VERSION ""

NS_ :

BS_:

BU_: ILC4 ILC3 ILC2 ILC1 C1 C0 ACU ECAS2 CCU TPMS ACC AEBS Door4 Door3 Door2 Door1 WWCU HVAC HVAC_HMI EPHS LDWS SCSM EVCC ECAS1 BMS SWS EBS VCU2 PCi_ECM DCU EPH VFC VCU1 Tachograph EPIC

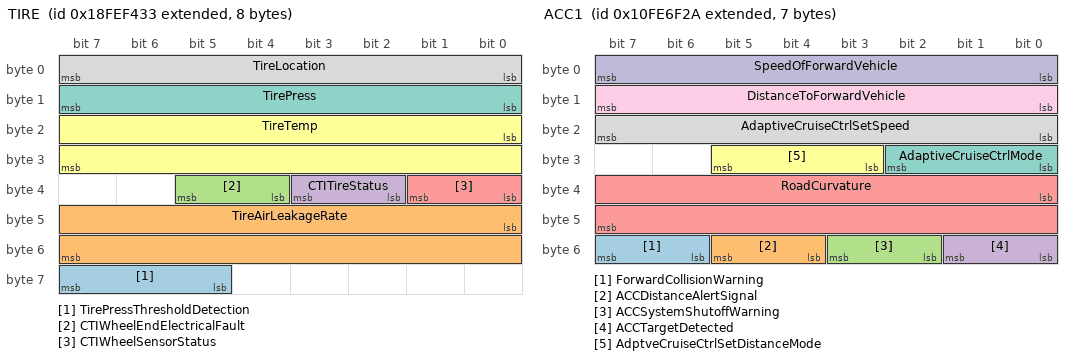
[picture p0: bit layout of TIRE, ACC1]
BO_ 2566845491 TIRE: 8 TPMS
 SG_ TirePressThresholdDetection : 61|3@1+ (1,0) [0|7] "" Vector__XXX
 SG_ TireAirLeakageRate : 40|16@1+ (0.1,0) [0|6425.5] "Pa/s" Vector__XXX
 SG_ CTIWheelEndElectricalFault : 36|2@1+ (1,0) [0|3] "" Vector__XXX
 SG_ CTITireStatus : 34|2@1+ (1,0) [0|3] "" Vector__XXX
 SG_ CTIWheelSensorStatus : 32|2@1+ (1,0) [0|3] "" Vector__XXX
 SG_ TireTemp : 16|16@1+ (0.03125,-273) [-273|1735] "deg" Vector__XXX
 SG_ TirePress : 8|8@1+ (8,0) [0|2040] "kPa" Vector__XXX
 SG_ TireLocation : 0|8@1+ (1,0) [0|255] "" Vector__XXX

BO_ 2432593706 ACC1: 7 ACC
 SG_ ForwardCollisionWarning : 54|2@1+ (1,0) [0|0] "" Vector__XXX
 SG_ ACCDistanceAlertSignal : 52|2@1+ (1,0) [0|3] "" Vector__XXX
 SG_ ACCSystemShutoffWarning : 50|2@1+ (1,0) [0|3] "" Vector__XXX
 SG_ ACCTargetDetected : 48|2@1+ (1,0) [0|3] "" Vector__XXX
 SG_ RoadCurvature : 32|16@1+ (0.0078125,-250) [-250|251.992] "1/km" Vector__XXX
 SG_ AdptveCruiseCtrlSetDistanceMode : 27|3@1+ (1,0) [0|7] "" Vector__XXX
 SG_ AdaptiveCruiseCtrlMode : 24|3@1+ (1,0) [0|7] "" Vector__XXX
 SG_ AdaptiveCruiseCtrlSetSpeed : 16|8@1+ (1,0) [0|250] "km/h" Vector__XXX
 SG_ DistanceToForwardVehicle : 8|8@1+ (1,0) [0|250] "m" Vector__XXX
 SG_ SpeedOfForwardVehicle : 0|8@1+ (1,0) [0|250] "km/h" Vector__XXX

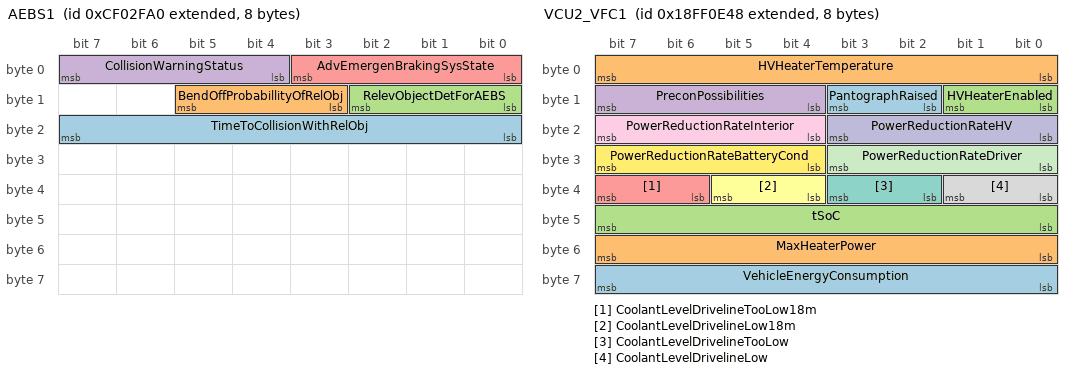
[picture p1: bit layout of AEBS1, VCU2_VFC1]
BO_ 2364551072 AEBS1: 8 AEBS
 SG_ TimeToCollisionWithRelObj : 16|8@1+ (0.05,0) [0|13] "sec" Vector__XXX
 SG_ BendOffProbabillityOfRelObj : 11|3@1+ (1,0) [0|0] "" Vector__XXX
 SG_ RelevObjectDetForAEBS : 8|3@1+ (1,0) [0|0] "" Vector__XXX
 SG_ CollisionWarningStatus : 4|4@1+ (1,0) [0|0] "" Vector__XXX
 SG_ AdvEmergenBrakingSysState : 0|4@1+ (1,0) [0|0] "" Vector__XXX

BO_ 2566852168 VCU2_VFC1: 8 VCU2
 SG_ VehicleEnergyConsumption : 56|8@1+ (1,0) [0|0] "kWh/100km" Vector__XXX
 SG_ MaxHeaterPower : 48|8@1+ (500,0) [0|125000] "Watt" Vector__XXX
 SG_ tSoC : 40|8@1+ (0.4,0) [0|100] "%" Vector__XXX
 SG_ PreconPossibilities : 12|4@1+ (1,0) [0|0] "" Vector__XXX
 SG_ CoolantLevelDrivelineTooLow18m : 38|2@1+ (1,0) [0|3] "" Vector__XXX
 SG_ CoolantLevelDrivelineLow18m : 36|2@1+ (1,0) [0|3] "" Vector__XXX
 SG_ CoolantLevelDrivelineTooLow : 34|2@1+ (1,0) [0|3] "" Vector__XXX
 SG_ CoolantLevelDrivelineLow : 32|2@1+ (1,0) [0|3] "" Vector__XXX
 SG_ PowerReductionRateInterior : 20|4@1+ (10,0) [0|100] "%" Vector__XXX
 SG_ PowerReductionRateHV : 16|4@1+ (10,0) [0|100] "%" Vector__XXX
 SG_ PowerReductionRateDriver : 24|4@1+ (10,0) [0|100] "%" Vector__XXX
 SG_ PowerReductionRateBatteryCond : 28|4@1+ (10,0) [0|100] "%" Vector__XXX
 SG_ PantographRaised : 10|2@1+ (1,0) [0|0] "" Vector__XXX
 SG_ HVHeaterTemperature : 0|8@1+ (1,-50) [-50|205] "C" Vector__XXX
 SG_ HVHeaterEnabled : 8|2@1+ (1,0) [0|0] "" Vector__XXX

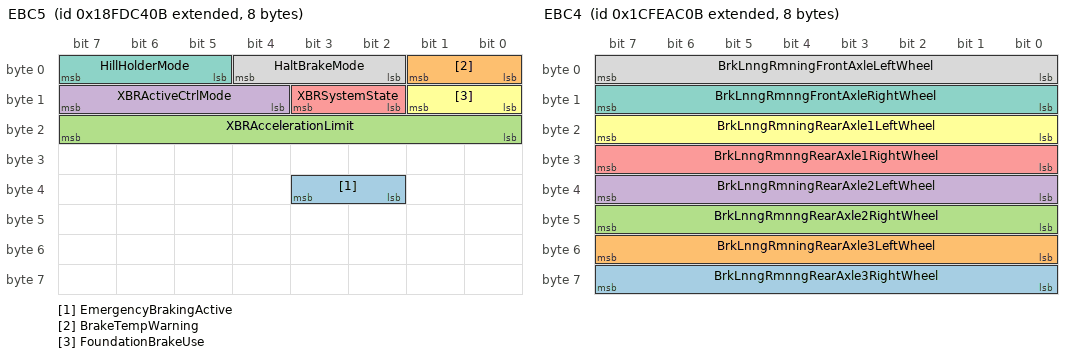
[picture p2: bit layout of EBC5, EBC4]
BO_ 2566767627 EBC5: 8 EBS
 SG_ EmergencyBrakingActive : 34|2@1+ (1,0) [0|0] "" Vector__XXX
 SG_ BrakeTempWarning : 0|2@1+ (1,0) [0|3] "" Vector__XXX
 SG_ XBRAccelerationLimit : 16|8@1+ (0.1,-12.5) [-12.5|12.5] "m/s²" Vector__XXX
 SG_ XBRActiveCtrlMode : 12|4@1+ (1,0) [0|15] "" Vector__XXX
 SG_ XBRSystemState : 10|2@1+ (1,0) [0|3] "" Vector__XXX
 SG_ FoundationBrakeUse : 8|2@1+ (1,0) [0|3] "" Vector__XXX
 SG_ HillHolderMode : 5|3@1+ (1,0) [0|7] "" Vector__XXX
 SG_ HaltBrakeMode : 2|3@1+ (1,0) [0|7] "" Vector__XXX

BO_ 2565865739 EBC1_EBS: 8 EBS
 SG_ SrcAddrssOfCtrllngDvcFrBrkCntrl : 48|8@1+ (1,0) [0|255] "" Vector__XXX
 SG_ BrakePedalPos : 8|8@1+ (0.4,0) [0|100] "%" Vector__XXX
 SG_ TrctrMntdTrilerABSWarningSignal : 62|2@1+ (1,0) [0|3] "" Vector__XXX
 SG_ TrailerABSStatus : 60|2@1+ (1,0) [0|3] "" Vector__XXX
 SG_ HaltBrakeSwitch : 58|2@1+ (1,0) [0|3] "" Vector__XXX
 SG_ ATC_ASRInformationSignal : 46|2@1+ (1,0) [0|3] "" Vector__XXX
 SG_ ABS_EBSAmberWarningSignal : 44|2@1+ (1,0) [0|3] "" Vector__XXX
 SG_ EBSRedWarningSignal : 42|2@1+ (1,0) [0|3] "" Vector__XXX
 SG_ ABSFullyOperational : 40|2@1+ (1,0) [0|3] "" Vector__XXX
 SG_ EngRetarderSelection : 32|8@1+ (0.4,0) [0|100] "%" Vector__XXX
 SG_ RemoteAccelEnableSwitch : 30|2@1+ (1,0) [0|3] "" Vector__XXX
 SG_ EngAuxEngShutdownSwitch : 28|2@1+ (1,0) [0|3] "" Vector__XXX
 SG_ EngDerateSwitch : 26|2@1+ (1,0) [0|3] "" Vector__XXX
 SG_ AccelInterlockSwitch : 24|2@1+ (1,0) [0|3] "" Vector__XXX
 SG_ TractionCtrlOverrideSwitch : 22|2@1+ (1,0) [0|3] "" Vector__XXX
 SG_ ASRHillHolderSwitch : 20|2@1+ (1,0) [0|3] "" Vector__XXX
 SG_ ASROffroadSwitch : 18|2@1+ (1,0) [0|3] "" Vector__XXX
 SG_ ABSOffroadSwitch : 16|2@1+ (1,0) [0|3] "" Vector__XXX
 SG_ EBSBrakeSwitch : 6|2@1+ (1,0) [0|3] "" Vector__XXX
 SG_ AntiLockBrakingActive : 4|2@1+ (1,0) [0|3] "" Vector__XXX
 SG_ ASRBrakeCtrlActive : 2|2@1+ (1,0) [0|3] "" Vector__XXX
 SG_ ASREngCtrlActive : 0|2@1+ (1,0) [0|3] "" Vector__XXX

BO_ 2633935883 EBC4: 8 EBS
 SG_ BrkLnngRmnngRearAxle3RightWheel : 56|8@1+ (0.4,0) [0|100] "%" Vector__XXX
 SG_ BrkLnngRmningRearAxle3LeftWheel : 48|8@1+ (0.4,0) [0|100] "%" Vector__XXX
 SG_ BrkLnngRmnngRearAxle2RightWheel : 40|8@1+ (0.4,0) [0|100] "%" Vector__XXX
 SG_ BrkLnngRmningRearAxle2LeftWheel : 32|8@1+ (0.4,0) [0|100] "%" Vector__XXX
 SG_ BrkLnngRmnngRearAxle1RightWheel : 24|8@1+ (0.4,0) [0|100] "%" Vector__XXX
 SG_ BrkLnngRmningRearAxle1LeftWheel : 16|8@1+ (0.4,0) [0|100] "%" Vector__XXX
 SG_ BrkLnngRmnngFrontAxleRightWheel : 8|8@1+ (0.4,0) [0|100] "%" Vector__XXX
 SG_ BrkLnngRmningFrontAxleLeftWheel : 0|8@1+ (0.4,0) [0|100] "%" Vector__XXX

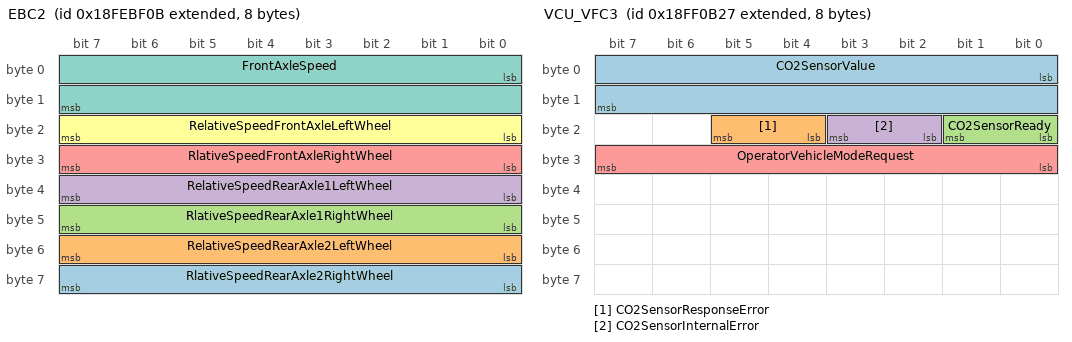
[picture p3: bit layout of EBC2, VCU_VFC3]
BO_ 2566831883 EBC2: 8 EBS
 SG_ RlativeSpeedRearAxle2RightWheel : 56|8@1+ (0.0625,-7.8125) [-7.8125|7.8125] "km/h" Vector__XXX
 SG_ RelativeSpeedRearAxle2LeftWheel : 48|8@1+ (0.0625,-7.8125) [-7.8125|7.8125] "km/h" Vector__XXX
 SG_ RlativeSpeedRearAxle1RightWheel : 40|8@1+ (0.0625,-7.8125) [-7.8125|7.8125] "km/h" Vector__XXX
 SG_ RelativeSpeedRearAxle1LeftWheel : 32|8@1+ (0.0625,-7.8125) [-7.8125|7.8125] "km/h" Vector__XXX
 SG_ RlativeSpeedFrontAxleRightWheel : 24|8@1+ (0.0625,-7.8125) [-7.8125|7.8125] "km/h" Vector__XXX
 SG_ RelativeSpeedFrontAxleLeftWheel : 16|8@1+ (0.0625,-7.8125) [-7.8125|7.8125] "km/h" Vector__XXX
 SG_ FrontAxleSpeed : 0|16@1+ (0.00390625,0) [0|250.996] "km/h" Vector__XXX

BO_ 2365479471 ASC1_ECAS1: 8 ECAS1
 SG_ SspensionCtrlRefusalInformation : 56|4@1+ (1,0) [0|15] "" Vector__XXX
 SG_ SuspensionRemoteCtrl2 : 50|2@1+ (1,0) [0|3] "" Vector__XXX
 SG_ SuspensionRemoteCtrl1 : 48|2@1+ (1,0) [0|3] "" Vector__XXX
 SG_ RearAxleInBumperRange : 42|2@1+ (1,0) [0|3] "" Vector__XXX
 SG_ FrontAxleInBumperRange : 40|2@1+ (1,0) [0|3] "" Vector__XXX
 SG_ DoorRelease : 36|2@1+ (1,0) [0|3] "" Vector__XXX
 SG_ VehicleMotionInhibit : 34|2@1+ (1,0) [0|3] "" Vector__XXX
 SG_ SecurityDevice : 32|2@1+ (1,0) [0|3] "" Vector__XXX
 SG_ LevelCtrlMode : 28|4@1+ (1,0) [0|15] "" Vector__XXX
 SG_ KneelingInformation : 24|4@1+ (1,0) [0|15] "" Vector__XXX
 SG_ LiftingCtrlModeRearAxle : 22|2@1+ (1,0) [0|3] "" Vector__XXX
 SG_ LiftingCtrlModeFrontAxle : 20|2@1+ (1,0) [0|3] "" Vector__XXX
 SG_ LoweringCtrlModeRearAxle : 18|2@1+ (1,0) [0|3] "" Vector__XXX
 SG_ LoweringCtrlModeFrontAxle : 16|2@1+ (1,0) [0|3] "" Vector__XXX
 SG_ AboveNominalLevelRearAxle : 14|2@1+ (1,0) [0|3] "" Vector__XXX
 SG_ AboveNominalLevelFrontAxle : 12|2@1+ (1,0) [0|3] "" Vector__XXX
 SG_ BelowNominalLevelRearAxle : 10|2@1+ (1,0) [0|3] "" Vector__XXX
 SG_ BelowNominalLevelFrontAxle : 8|2@1+ (1,0) [0|3] "" Vector__XXX
 SG_ NominalLevelRearAxle : 4|4@1+ (1,0) [0|15] "" Vector__XXX
 SG_ NominalLevelFrontAxle : 0|4@1+ (1,0) [0|15] "" Vector__XXX
 SG_ LiftAxle2Pos : 46|2@1+ (1,0) [0|3] "" Vector__XXX
 SG_ LiftAxle1Pos : 38|2@1+ (1,0) [0|3] "" Vector__XXX

BO_ 2365525031 VCU_VFC2: 8 VCU1
 SG_ EmergencyBrakeLight : 2|2@1+ (1,0) [0|0] "" Vector__XXX
 SG_ BrakeLightRequest : 0|2@1+ (1,0) [0|0] "" Vector__XXX

BO_ 2565866801 ETC2_VFC: 8 VFC
 SG_ TransCurrentGear : 24|8@1+ (1,-125) [-125|125] "" Vector__XXX

BO_ 2565812692 DCU_Veh_4: 8 Door4
 SG_ DeadboltInput : 62|2@1- (1,0) [0|0] ""  VFC
 SG_ Door_Block_Input_State : 60|2@1+ (1,0) [0|3] ""  VFC
 SG_ Light_Barrier_Input_State : 58|2@1+ (1,0) [0|3] ""  VFC
 SG_ External_Close_Button : 56|2@1+ (1,0) [0|3] ""  VFC
 SG_ External_Open_Button : 54|2@1+ (1,0) [0|3] ""  VFC
 SG_ Workshop_Button : 52|2@1+ (1,0) [0|3] ""  VFC
 SG_ Inner_Sensitive_Edge_Input_State : 50|2@1+ (1,0) [0|3] ""  VFC
 SG_ Spare_In_5 : 48|2@1+ (1,0) [0|3] ""  VFC
 SG_ Spare_In_4 : 46|2@1+ (1,0) [0|3] ""  VFC
 SG_ Spare_In_3 : 44|2@1+ (1,0) [0|3] ""  VFC
 SG_ Spare_In_2 : 42|2@1+ (1,0) [0|3] ""  VFC
 SG_ Spare_In_1 : 40|2@1+ (1,0) [0|3] ""  VFC
 SG_ Door_Mode_Right : 36|4@1+ (1,0) [0|15] ""  VFC
 SG_ Door_Mode_Left : 32|4@1+ (1,0) [0|15] ""  VFC
 SG_ Right_Leaf_Obstruction_State : 28|4@1+ (1,0) [0|15] ""  VFC
 SG_ Left_Leaf_Obstruction_State : 24|4@1+ (1,0) [0|15] ""  VFC
 SG_ Door_Position_Right : 16|8@1+ (0.4,0) [0|102] ""  VFC
 SG_ Door_Position_Left : 8|8@1+ (0.4,0) [0|102] ""  VFC
 SG_ Leaf_State_Right : 4|4@1+ (1,0) [0|15] ""  VFC
 SG_ Leaf_State_Left : 0|4@1+ (1,0) [0|15] ""  VFC

BO_ 2565812691 DCU_Veh_3: 8 Door3
 SG_ DeadboltInput : 62|2@1- (1,0) [0|0] ""  VFC
 SG_ Door_Block_Input_State : 60|2@1+ (1,0) [0|3] ""  VFC
 SG_ Light_Barrier_Input_State : 58|2@1+ (1,0) [0|3] ""  VFC
 SG_ External_Close_Button : 56|2@1+ (1,0) [0|3] ""  VFC
 SG_ External_Open_Button : 54|2@1+ (1,0) [0|3] ""  VFC
 SG_ Workshop_Button : 52|2@1+ (1,0) [0|3] ""  VFC
 SG_ Inner_Sensitive_Edge_Input_State : 50|2@1+ (1,0) [0|3] ""  VFC
 SG_ Spare_In_5 : 48|2@1+ (1,0) [0|3] ""  VFC
 SG_ Spare_In_4 : 46|2@1+ (1,0) [0|3] ""  VFC
 SG_ Spare_In_3 : 44|2@1+ (1,0) [0|3] ""  VFC
 SG_ Spare_In_2 : 42|2@1+ (1,0) [0|3] ""  VFC
 SG_ Spare_In_1 : 40|2@1+ (1,0) [0|3] ""  VFC
 SG_ Door_Mode_Right : 36|4@1+ (1,0) [0|15] ""  VFC
 SG_ Door_Mode_Left : 32|4@1+ (1,0) [0|15] ""  VFC
 SG_ Right_Leaf_Obstruction_State : 28|4@1+ (1,0) [0|15] ""  VFC
 SG_ Left_Leaf_Obstruction_State : 24|4@1+ (1,0) [0|15] ""  VFC
 SG_ Door_Position_Right : 16|8@1+ (0.4,0) [0|102] ""  VFC
 SG_ Door_Position_Left : 8|8@1+ (0.4,0) [0|102] ""  VFC
 SG_ Leaf_State_Right : 4|4@1+ (1,0) [0|15] ""  VFC
 SG_ Leaf_State_Left : 0|4@1+ (1,0) [0|15] ""  VFC

BO_ 2565812690 DCU_Veh_2: 8 Door2
 SG_ DeadboltInput : 62|2@1- (1,0) [0|0] ""  VFC
 SG_ Door_Block_Input_State : 60|2@1+ (1,0) [0|3] ""  VFC
 SG_ Light_Barrier_Input_State : 58|2@1+ (1,0) [0|3] ""  VFC
 SG_ External_Close_Button : 56|2@1+ (1,0) [0|3] ""  VFC
 SG_ External_Open_Button : 54|2@1+ (1,0) [0|3] ""  VFC
 SG_ Workshop_Button : 52|2@1+ (1,0) [0|3] ""  VFC
 SG_ Inner_Sensitive_Edge_Input_State : 50|2@1+ (1,0) [0|3] ""  VFC
 SG_ Spare_In_5 : 48|2@1+ (1,0) [0|3] ""  VFC
 SG_ Spare_In_4 : 46|2@1+ (1,0) [0|3] ""  VFC
 SG_ Spare_In_3 : 44|2@1+ (1,0) [0|3] ""  VFC
 SG_ Spare_In_2 : 42|2@1+ (1,0) [0|3] ""  VFC
 SG_ Spare_In_1 : 40|2@1+ (1,0) [0|3] ""  VFC
 SG_ Door_Mode_Right : 36|4@1+ (1,0) [0|15] ""  VFC
 SG_ Door_Mode_Left : 32|4@1+ (1,0) [0|15] ""  VFC
 SG_ Right_Leaf_Obstruction_State : 28|4@1+ (1,0) [0|15] ""  VFC
 SG_ Left_Leaf_Obstruction_State : 24|4@1+ (1,0) [0|15] ""  VFC
 SG_ Door_Position_Right : 16|8@1+ (0.4,0) [0|102] ""  VFC
 SG_ Door_Position_Left : 8|8@1+ (0.4,0) [0|102] ""  VFC
 SG_ Leaf_State_Right : 4|4@1+ (1,0) [0|15] ""  VFC
 SG_ Leaf_State_Left : 0|4@1+ (1,0) [0|15] ""  VFC

BO_ 2565812689 DCU_Veh_1: 8 Door1
 SG_ DeadboltInput : 62|2@1- (1,0) [0|0] ""  VFC
 SG_ Door_Block_Input_State : 60|2@1+ (1,0) [0|3] ""  VFC
 SG_ Light_Barrier_Input_State : 58|2@1+ (1,0) [0|3] ""  VFC
 SG_ External_Close_Button : 56|2@1+ (1,0) [0|3] ""  VFC
 SG_ External_Open_Button : 54|2@1+ (1,0) [0|3] ""  VFC
 SG_ Workshop_Button : 52|2@1+ (1,0) [0|3] ""  VFC
 SG_ Inner_Sensitive_Edge_Input_State : 50|2@1+ (1,0) [0|3] ""  VFC
 SG_ Spare_In_5 : 48|2@1+ (1,0) [0|3] ""  VFC
 SG_ Spare_In_4 : 46|2@1+ (1,0) [0|3] ""  VFC
 SG_ Spare_In_3 : 44|2@1+ (1,0) [0|3] ""  VFC
 SG_ Spare_In_2 : 42|2@1+ (1,0) [0|3] ""  VFC
 SG_ Spare_In_1 : 40|2@1+ (1,0) [0|3] ""  VFC
 SG_ Door_Mode_Right : 36|4@1+ (1,0) [0|15] ""  VFC
 SG_ Door_Mode_Left : 32|4@1+ (1,0) [0|15] ""  VFC
 SG_ Right_Leaf_Obstruction_State : 28|4@1+ (1,0) [0|15] ""  VFC
 SG_ Left_Leaf_Obstruction_State : 24|4@1+ (1,0) [0|15] ""  VFC
 SG_ Door_Position_Right : 16|8@1+ (0.4,0) [0|102] ""  VFC
 SG_ Door_Position_Left : 8|8@1+ (0.4,0) [0|102] ""  VFC
 SG_ Leaf_State_Right : 4|4@1+ (1,0) [0|15] ""  VFC
 SG_ Leaf_State_Left : 0|4@1+ (1,0) [0|15] ""  VFC

BO_ 2565854257 Veh_DCU_4: 8 VFC
 SG_ AutoCloseTime : 56|4@1+ (1,0) [0|14] "s"  Door4
 SG_ Inhibit_Opening : 62|2@1- (1,0) [0|0] ""  Door4
 SG_ Inhibit_Closing : 60|2@1- (1,0) [0|0] ""  Door4
 SG_ Ignore_Outer_Sensitive_Edge : 54|2@1+ (1,0) [0|3] ""  Door4
 SG_ Ignore_Light_Barrier : 50|2@1+ (1,0) [0|3] ""  Door4
 SG_ Spare_Out_Request_7 : 44|2@1+ (1,0) [0|3] ""  Door4
 SG_ Spare_Out_Request_5 : 40|2@1+ (1,0) [0|3] ""  Door4
 SG_ Spare_Out_Request_4 : 38|2@1+ (1,0) [0|3] ""  Door4
 SG_ Spare_Out_Request_3 : 36|2@1+ (1,0) [0|3] ""  Door4
 SG_ Spare_Out_Request_2 : 34|2@1+ (1,0) [0|3] ""  Door4
 SG_ Spare_Out_Request_6 : 42|2@1+ (1,0) [0|3] ""  Door4
 SG_ Spare_Out_Request_8 : 46|2@1+ (1,0) [0|3] ""  Door4
 SG_ Ignore_Speed_Obstruction : 52|2@1+ (1,0) [0|3] ""  Door4
 SG_ Ignore_Sensitive_Edge : 48|2@1+ (1,0) [0|3] ""  Door4
 SG_ Spare_Out_Request_1 : 32|2@1+ (1,0) [0|3] ""  Door4
 SG_ Door_Position_Request_Right : 24|8@1+ (0.4,0) [0|102] ""  Door4
 SG_ Door_Position_Request_Left_Both : 16|8@1+ (0.4,0) [0|102] ""  Door4
 SG_ Right_Leaf_Command : 12|4@1+ (1,0) [0|15] ""  Door4
 SG_ Left_Leaf_Command : 8|4@1+ (1,0) [0|15] ""  Door4
 SG_ Buzzer : 6|2@1+ (1,0) [0|3] ""  Door4
 SG_ Step_Lights : 4|2@1+ (1,0) [0|3] ""  Door4
 SG_ Reset_Inhibit_Emergency_Valve : 2|2@1+ (1,0) [0|3] ""  Door4
 SG_ Speed_Standstill_Signal : 0|2@1+ (1,0) [0|3] ""  Door4

BO_ 2565854001 Veh_DCU_3: 8 VFC
 SG_ AutoCloseTime : 56|4@1+ (1,0) [0|14] "s"  Door3
 SG_ Inhibit_Opening : 62|2@1- (1,0) [0|0] ""  Door3
 SG_ Inhibit_Closing : 60|2@1- (1,0) [0|0] ""  Door3
 SG_ Ignore_Outer_Sensitive_Edge : 54|2@1+ (1,0) [0|3] ""  Door3
 SG_ Ignore_Light_Barrier : 50|2@1+ (1,0) [0|3] ""  Door3
 SG_ Spare_Out_Request_7 : 44|2@1+ (1,0) [0|3] ""  Door3
 SG_ Spare_Out_Request_5 : 40|2@1+ (1,0) [0|3] ""  Door3
 SG_ Spare_Out_Request_4 : 38|2@1+ (1,0) [0|3] ""  Door3
 SG_ Spare_Out_Request_3 : 36|2@1+ (1,0) [0|3] ""  Door3
 SG_ Spare_Out_Request_2 : 34|2@1+ (1,0) [0|3] ""  Door3
 SG_ Spare_Out_Request_6 : 42|2@1+ (1,0) [0|3] ""  Door3
 SG_ Spare_Out_Request_8 : 46|2@1+ (1,0) [0|3] ""  Door3
 SG_ Ignore_Speed_Obstruction : 52|2@1+ (1,0) [0|3] ""  Door3
 SG_ Ignore_Sensitive_Edge : 48|2@1+ (1,0) [0|3] ""  Door3
 SG_ Spare_Out_Request_1 : 32|2@1+ (1,0) [0|3] ""  Door3
 SG_ Door_Position_Request_Right : 24|8@1+ (0.4,0) [0|102] ""  Door3
 SG_ Door_Position_Request_Left_Both : 16|8@1+ (0.4,0) [0|102] ""  Door3
 SG_ Right_Leaf_Command : 12|4@1+ (1,0) [0|15] ""  Door3
 SG_ Left_Leaf_Command : 8|4@1+ (1,0) [0|15] ""  Door3
 SG_ Buzzer : 6|2@1+ (1,0) [0|3] ""  Door3
 SG_ Step_Lights : 4|2@1+ (1,0) [0|3] ""  Door3
 SG_ Reset_Inhibit_Emergency_Valve : 2|2@1+ (1,0) [0|3] ""  Door3
 SG_ Speed_Standstill_Signal : 0|2@1+ (1,0) [0|3] ""  Door3

BO_ 2565853745 Veh_DCU_2: 8 VFC
 SG_ AutoCloseTime : 56|4@1+ (1,0) [0|14] "s"  Door2
 SG_ Inhibit_Opening : 62|2@1- (1,0) [0|0] ""  Door2
 SG_ Inhibit_Closing : 60|2@1- (1,0) [0|0] ""  Door2
 SG_ Ignore_Outer_Sensitive_Edge : 54|2@1+ (1,0) [0|3] ""  Door2
 SG_ Ignore_Light_Barrier : 50|2@1+ (1,0) [0|3] ""  Door2
 SG_ Spare_Out_Request_7 : 44|2@1+ (1,0) [0|3] ""  Door2
 SG_ Spare_Out_Request_5 : 40|2@1+ (1,0) [0|3] ""  Door2
 SG_ Spare_Out_Request_4 : 38|2@1+ (1,0) [0|3] ""  Door2
 SG_ Spare_Out_Request_3 : 36|2@1+ (1,0) [0|3] ""  Door2
 SG_ Spare_Out_Request_2 : 34|2@1+ (1,0) [0|3] ""  Door2
 SG_ Spare_Out_Request_6 : 42|2@1+ (1,0) [0|3] ""  Door2
 SG_ Spare_Out_Request_8 : 46|2@1+ (1,0) [0|3] ""  Door2
 SG_ Ignore_Speed_Obstruction : 52|2@1+ (1,0) [0|3] ""  Door2
 SG_ Ignore_Sensitive_Edge : 48|2@1+ (1,0) [0|3] ""  Door2
 SG_ Spare_Out_Request_1 : 32|2@1+ (1,0) [0|3] ""  Door2
 SG_ Door_Position_Request_Right : 24|8@1+ (0.4,0) [0|102] ""  Door2
 SG_ Door_Position_Request_Left_Both : 16|8@1+ (0.4,0) [0|102] ""  Door2
 SG_ Right_Leaf_Command : 12|4@1+ (1,0) [0|15] ""  Door2
 SG_ Left_Leaf_Command : 8|4@1+ (1,0) [0|15] ""  Door2
 SG_ Buzzer : 6|2@1+ (1,0) [0|3] ""  Door2
 SG_ Step_Lights : 4|2@1+ (1,0) [0|3] ""  Door2
 SG_ Reset_Inhibit_Emergency_Valve : 2|2@1+ (1,0) [0|3] ""  Door2
 SG_ Speed_Standstill_Signal : 0|2@1+ (1,0) [0|3] ""  Door2

BO_ 2565853489 Veh_DCU_1: 8 VFC
 SG_ Inhibit_Opening : 62|2@1- (1,0) [0|0] ""  Door1
 SG_ Inhibit_Closing : 60|2@1- (1,0) [0|0] ""  Door1
 SG_ AutoCloseTime : 56|4@1+ (1,0) [0|14] "s"  Door1
 SG_ Ignore_Outer_Sensitive_Edge : 54|2@1+ (1,0) [0|3] ""  Door1
 SG_ Ignore_Light_Barrier : 50|2@1+ (1,0) [0|3] ""  Door1
 SG_ Spare_Out_Request_7 : 44|2@1+ (1,0) [0|3] ""  Door1
 SG_ Spare_Out_Request_5 : 40|2@1+ (1,0) [0|3] ""  Door1
 SG_ Spare_Out_Request_4 : 38|2@1+ (1,0) [0|3] ""  Door1
 SG_ Spare_Out_Request_3 : 36|2@1+ (1,0) [0|3] ""  Door1
 SG_ Spare_Out_Request_2 : 34|2@1+ (1,0) [0|3] ""  Door1
 SG_ Spare_Out_Request_6 : 42|2@1+ (1,0) [0|3] ""  Door1
 SG_ Spare_Out_Request_8 : 46|2@1+ (1,0) [0|3] ""  Door1
 SG_ Ignore_Speed_Obstruction : 52|2@1+ (1,0) [0|3] ""  Door1
 SG_ Ignore_Sensitive_Edge : 48|2@1+ (1,0) [0|3] ""  Door1
 SG_ Spare_Out_Request_1 : 32|2@1+ (1,0) [0|3] ""  Door1
 SG_ Door_Position_Request_Right : 24|8@1+ (0.4,0) [0|102] ""  Door1
 SG_ Door_Position_Request_Left_Both : 16|8@1+ (0.4,0) [0|102] ""  Door1
 SG_ Right_Leaf_Command : 12|4@1+ (1,0) [0|15] ""  Door1
 SG_ Left_Leaf_Command : 8|4@1+ (1,0) [0|15] ""  Door1
 SG_ Buzzer : 6|2@1+ (1,0) [0|3] ""  Door1
 SG_ Step_Lights : 4|2@1+ (1,0) [0|3] ""  Door1
 SG_ Reset_Inhibit_Emergency_Valve : 2|2@1+ (1,0) [0|3] ""  Door1
 SG_ Speed_Standstill_Signal : 0|2@1+ (1,0) [0|3] ""  Door1

BO_ 2566853885 WiperStatus: 8 WWCU
 SG_ Motor2sensorstatus : 2|2@1+ (1,0) [0|3] "" Vector__XXX
 SG_ Motor1sensorstatus : 0|2@1+ (1,0) [0|3] "" Vector__XXX

BO_ 2566850855 CMS: 8 VFC
 SG_ CMS_DayNightSwitch : 0|8@1+ (1,0) [0|0] "" Vector__XXX

BO_ 2566851367 VCU_VFC3: 8 VCU1
 SG_ CO2SensorValue : 0|16@1+ (1,0) [0|0] "ppm" Vector__XXX
 SG_ CO2SensorResponseError : 20|2@1+ (1,0) [0|0] "" Vector__XXX
 SG_ CO2SensorReady : 16|2@1+ (1,0) [0|0] "" Vector__XXX
 SG_ CO2SensorInternalError : 18|2@1+ (1,0) [0|0] "" Vector__XXX
 SG_ OperatorVehicleModeRequest : 24|8@1+ (1,0) [0|0] "" Vector__XXX

BO_ 2566889521 WWCUDoor: 8 VFC
 SG_ WWCUDoorOpen : 0|1@1+ (1,0) [0|0] "" Vector__XXX

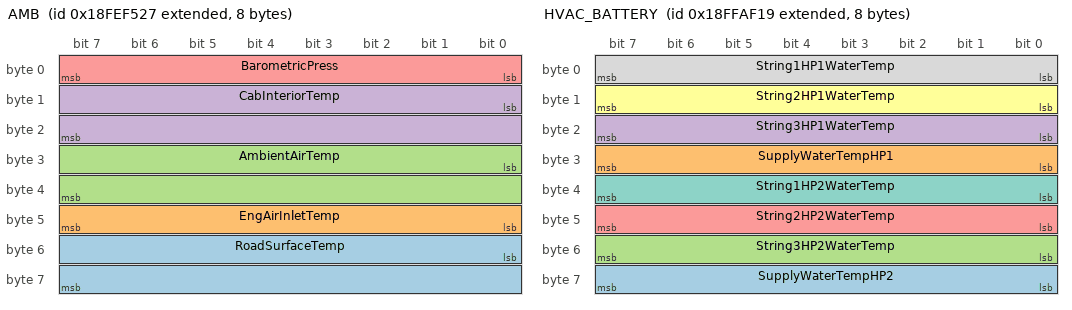
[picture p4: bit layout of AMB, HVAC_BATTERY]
BO_ 2566845735 AMB: 8 VFC
 SG_ RoadSurfaceTemp : 48|16@1+ (0.03125,-273) [-273|1735] "deg" Vector__XXX
 SG_ EngAirInletTemp : 40|8@1+ (1,-40) [-40|210] "deg" Vector__XXX
 SG_ AmbientAirTemp : 24|16@1+ (0.03125,-273) [-273|1735] "deg" Vector__XXX
 SG_ CabInteriorTemp : 8|16@1+ (0.03125,-273) [-273|1735] "deg" Vector__XXX
 SG_ BarometricPress : 0|8@1+ (0.5,0) [0|125] "kPa" Vector__XXX

BO_ 2566893337 HVAC_BATTERY: 8 HVAC
 SG_ SupplyWaterTempHP2 : 56|8@1+ (0.4,-40) [0|62] "degC" Vector__XXX
 SG_ SupplyWaterTempHP1 : 24|8@1+ (0.4,-40) [0|62] "degC" Vector__XXX
 SG_ String3HP2WaterTemp : 48|8@1+ (0.4,-40) [0|62] "degC" Vector__XXX
 SG_ String3HP1WaterTemp : 16|8@1+ (0.4,-40) [0|62] "degC" Vector__XXX
 SG_ String2HP2WaterTemp : 40|8@1+ (0.4,-40) [0|62] "degC" Vector__XXX
 SG_ String2HP1WaterTemp : 8|8@1+ (0.4,-40) [0|62] "degC" Vector__XXX
 SG_ String1HP2WaterTemp : 32|8@1+ (0.4,-40) [0|62] "degC" Vector__XXX
 SG_ String1HP1WaterTemp : 0|8@1+ (0.4,-40) [0|62] "degC" Vector__XXX

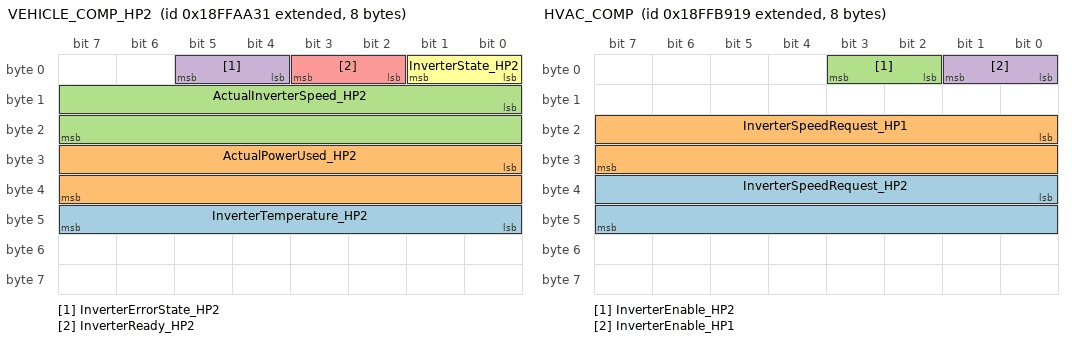
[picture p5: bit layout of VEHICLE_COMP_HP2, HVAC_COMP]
BO_ 2566892081 VEHICLE_COMP_HP2: 8 VFC
 SG_ InverterTemperature_HP2 : 40|8@1+ (1,-40) [0|0] "" Vector__XXX
 SG_ ActualPowerUsed_HP2 : 24|16@1+ (0.005,-160) [-160|167.675] "kW" Vector__XXX
 SG_ ActualInverterSpeed_HP2 : 8|16@1+ (1,-32000) [-32000|32255] "rpm" Vector__XXX
 SG_ InverterErrorState_HP2 : 4|2@1+ (1,0) [0|3] "" Vector__XXX
 SG_ InverterReady_HP2 : 2|2@1+ (1,0) [0|3] "" Vector__XXX
 SG_ InverterState_HP2 : 0|2@1+ (1,0) [0|3] "" Vector__XXX

BO_ 2566895897 HVAC_COMP: 8 HVAC
 SG_ InverterSpeedRequest_HP2 : 32|16@1+ (1,-32000) [-32000|32255] "" Vector__XXX
 SG_ InverterSpeedRequest_HP1 : 16|16@1+ (1,-32000) [-32000|32255] "" Vector__XXX
 SG_ InverterEnable_HP2 : 2|2@1+ (1,0) [0|3] "" Vector__XXX
 SG_ InverterEnable_HP1 : 0|2@1+ (1,0) [0|3] "" Vector__XXX

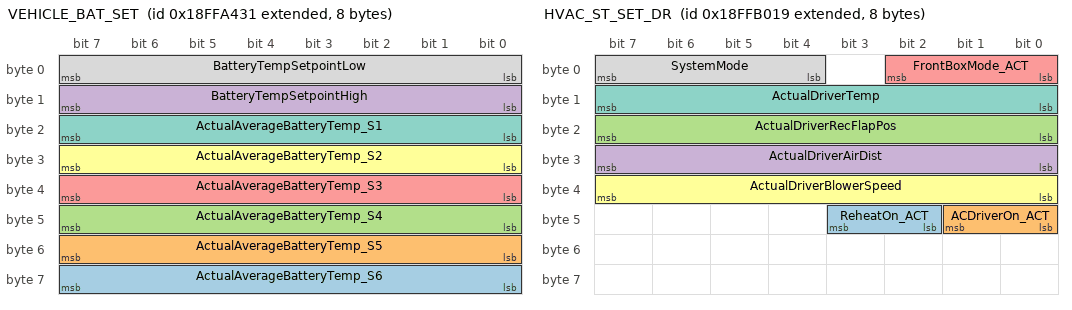
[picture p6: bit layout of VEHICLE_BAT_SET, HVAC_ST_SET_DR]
BO_ 2566890545 VEHICLE_BAT_SET: 8 VFC
 SG_ ActualAverageBatteryTemp_S6 : 56|8@1+ (0.4,-40) [-40|62] "C" Vector__XXX
 SG_ ActualAverageBatteryTemp_S5 : 48|8@1+ (0.4,-40) [-40|62] "C" Vector__XXX
 SG_ ActualAverageBatteryTemp_S4 : 40|8@1+ (0.4,-40) [-40|62] "C" Vector__XXX
 SG_ BatteryTempSetpointHigh : 8|8@1+ (0.4,-40) [-40|62] "" Vector__XXX
 SG_ ActualAverageBatteryTemp_S3 : 32|8@1+ (0.4,-40) [-40|62] "C" Vector__XXX
 SG_ ActualAverageBatteryTemp_S2 : 24|8@1+ (0.4,-40) [-40|62] "C" Vector__XXX
 SG_ ActualAverageBatteryTemp_S1 : 16|8@1+ (0.4,-40) [-40|62] "C" Vector__XXX
 SG_ BatteryTempSetpointLow : 0|8@1+ (0.4,-40) [-40|62] "" Vector__XXX

BO_ 2566893593 HVAC_ST_SET_DR: 8 HVAC
 SG_ ReheatOn_ACT : 42|2@1+ (1,0) [0|3] "-" Vector__XXX
 SG_ ACDriverOn_ACT : 40|2@1+ (1,0) [0|3] "" Vector__XXX
 SG_ ActualDriverRecFlapPos : 16|8@1+ (1,0) [0|255] "%" Vector__XXX
 SG_ ActualDriverAirDist : 24|8@1+ (1,0) [0|255] "%" Vector__XXX
 SG_ FrontBoxMode_ACT : 0|3@1+ (1,0) [0|7] "" Vector__XXX
 SG_ ActualDriverBlowerSpeed : 32|8@1+ (1,0) [0|255] "%" Vector__XXX
 SG_ ActualDriverTemp : 8|8@1+ (0.4,-40) [-40|62] "C" Vector__XXX
 SG_ SystemMode : 4|4@1+ (1,0) [0|15] "" Vector__XXX

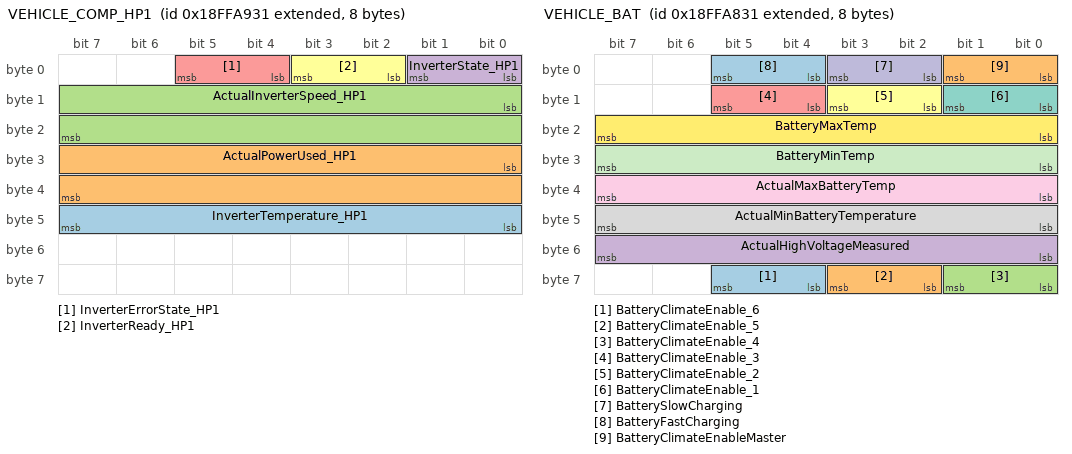
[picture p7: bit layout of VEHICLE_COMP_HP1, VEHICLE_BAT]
BO_ 2566891825 VEHICLE_COMP_HP1: 8 VFC
 SG_ InverterTemperature_HP1 : 40|8@1+ (1,-40) [0|0] "" Vector__XXX
 SG_ ActualPowerUsed_HP1 : 24|16@1+ (0.005,-160) [-160|167.675] "kW" Vector__XXX
 SG_ ActualInverterSpeed_HP1 : 8|16@1+ (1,-32000) [-32000|32255] "rpm" Vector__XXX
 SG_ InverterState_HP1 : 0|2@1+ (1,0) [0|3] "" Vector__XXX
 SG_ InverterErrorState_HP1 : 4|2@1+ (1,0) [0|3] "" Vector__XXX
 SG_ InverterReady_HP1 : 2|2@1+ (1,0) [0|3] "" Vector__XXX

BO_ 2566891569 VEHICLE_BAT: 8 VFC
 SG_ BatteryClimateEnable_6 : 60|2@1+ (1,0) [0|3] "" Vector__XXX
 SG_ BatteryClimateEnable_5 : 58|2@1+ (1,0) [0|3] "" Vector__XXX
 SG_ BatteryClimateEnable_4 : 56|2@1+ (1,0) [0|3] "" Vector__XXX
 SG_ ActualHighVoltageMeasured : 48|8@1+ (4,0) [0|1020] "" Vector__XXX
 SG_ BatteryClimateEnable_3 : 12|2@1+ (1,0) [0|3] "" Vector__XXX
 SG_ BatteryClimateEnable_2 : 10|2@1+ (1,0) [0|3] "" Vector__XXX
 SG_ BatteryClimateEnable_1 : 8|2@1+ (1,0) [0|3] "" Vector__XXX
 SG_ ActualMinBatteryTemperature : 40|8@1+ (0.4,-40) [-40|62] "C" Vector__XXX
 SG_ ActualMaxBatteryTemp : 32|8@1+ (0.4,-40) [-40|62] "C" Vector__XXX
 SG_ BatterySlowCharging : 2|2@1+ (1,0) [0|3] "" Vector__XXX
 SG_ BatteryMinTemp : 24|8@1+ (0.4,-40) [0|0] "C" Vector__XXX
 SG_ BatteryMaxTemp : 16|8@1+ (0.4,-40) [-40|62] "" Vector__XXX
 SG_ BatteryFastCharging : 4|2@1+ (1,0) [0|3] "" Vector__XXX
 SG_ BatteryClimateEnableMaster : 0|2@1+ (1,0) [0|3] "" Vector__XXX

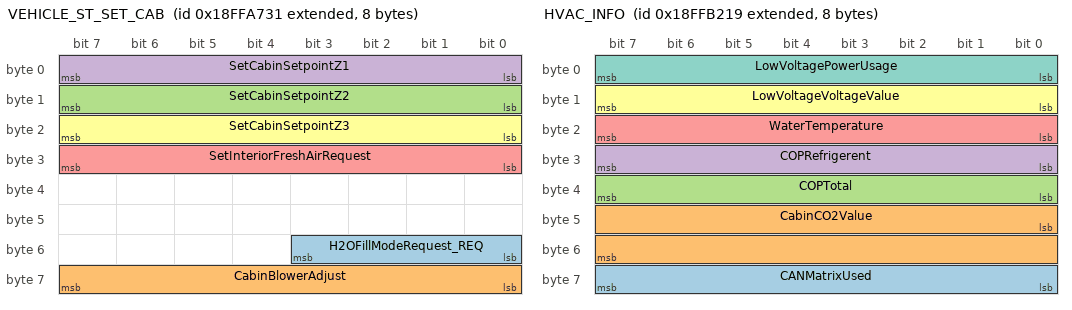
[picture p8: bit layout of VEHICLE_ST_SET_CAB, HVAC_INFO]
BO_ 2566891313 VEHICLE_ST_SET_CAB: 8 VFC
 SG_ H2OFillModeRequest_REQ : 48|4@1+ (1,0) [0|15] "-" Vector__XXX
 SG_ CabinBlowerAdjust : 56|8@1+ (1,-100) [-100|155] "%" Vector__XXX
 SG_ SetCabinSetpointZ2 : 8|8@1+ (0.4,-40) [0|0] "C" Vector__XXX
 SG_ SetCabinSetpointZ1 : 0|8@1+ (0.4,-40) [0|0] "C" Vector__XXX
 SG_ SetInteriorFreshAirRequest : 24|8@1+ (1,0) [0|255] "%" Vector__XXX
 SG_ SetCabinSetpointZ3 : 16|8@1+ (0.4,-40) [0|0] "C" Vector__XXX

BO_ 2566894105 HVAC_INFO: 8 HVAC
 SG_ CANMatrixUsed : 56|8@1+ (1,0) [0|0] "" Vector__XXX
 SG_ CabinCO2Value : 40|16@1+ (1,0) [0|64000] "ppm" Vector__XXX
 SG_ COPTotal : 32|8@1+ (0.05,0) [0|12.75] "" Vector__XXX
 SG_ COPRefrigerent : 24|8@1+ (0.05,0) [0|12.75] "" Vector__XXX
 SG_ WaterTemperature : 16|8@1+ (0.4,-40) [-40|62] "C" Vector__XXX
 SG_ LowVoltageVoltageValue : 8|8@1+ (0.25,0) [0|62.5] "V" Vector__XXX
 SG_ LowVoltagePowerUsage : 0|8@1+ (0.1,0) [0|25] "kW" Vector__XXX

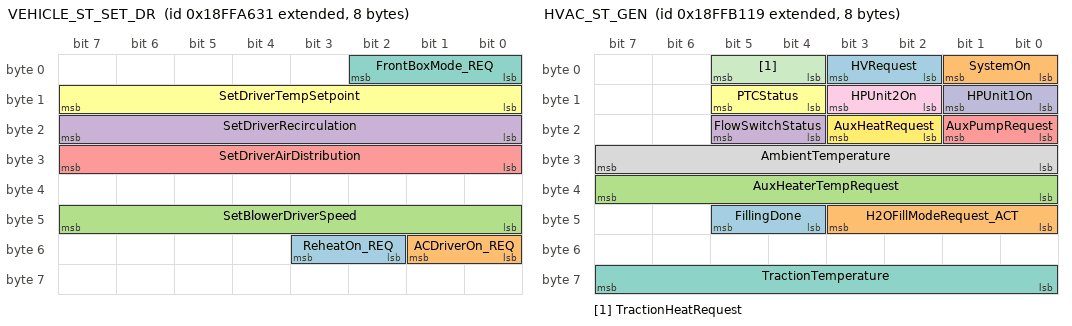
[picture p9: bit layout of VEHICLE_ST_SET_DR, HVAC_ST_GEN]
BO_ 2566891057 VEHICLE_ST_SET_DR: 8 VFC
 SG_ ReheatOn_REQ : 50|2@1+ (1,0) [0|3] "-" Vector__XXX
 SG_ ACDriverOn_REQ : 48|2@1+ (1,0) [0|3] "" Vector__XXX
 SG_ SetBlowerDriverSpeed : 40|8@1+ (1,0) [0|255] "%" Vector__XXX
 SG_ SetDriverRecirculation : 16|8@1+ (1,0) [0|255] "%" Vector__XXX
 SG_ SetDriverAirDistribution : 24|8@1+ (1,0) [0|255] "%" Vector__XXX
 SG_ SetDriverTempSetpoint : 8|8@1+ (0.4,-40) [-40|62] "C" Vector__XXX
 SG_ FrontBoxMode_REQ : 0|3@1+ (1,0) [0|7] "" Vector__XXX

BO_ 2566890801 VEHICLE_ST: 8 VFC
 SG_ AmbientLimitOverwrite : 60|2@1+ (1,0) [0|0] "" Vector__XXX
 SG_ AuxHeatSelection : 56|4@1+ (1,0) [0|0] "" Vector__XXX
 SG_ PowerReductionRateBat : 28|4@1+ (1,0) [0|15] "" Vector__XXX
 SG_ AuxHeaterActualTemp : 48|8@1+ (0.4,0) [0|102] "C" Vector__XXX
 SG_ Preconditioning : 14|2@1+ (1,0) [0|3] "" Vector__XXX
 SG_ PTCEnable : 12|2@1+ (1,0) [0|3] "" Vector__XXX
 SG_ TractionHeatMinimum : 40|8@1+ (0.4,-40) [-40|62] "C" Vector__XXX
 SG_ Door4Status : 38|2@1+ (1,0) [0|3] "" Vector__XXX
 SG_ Door3Status : 36|2@1+ (1,0) [0|3] "" Vector__XXX
 SG_ Door2Status : 34|2@1+ (1,0) [0|3] "" Vector__XXX
 SG_ Door1Status : 32|2@1+ (1,0) [0|3] "" Vector__XXX
 SG_ PowerReductionRateDriver : 24|4@1+ (1,0) [0|15] "" Vector__XXX
 SG_ PowerReductionRateInterior : 20|4@1+ (1,0) [0|15] "" Vector__XXX
 SG_ PowerReductionRateHV : 16|4@1+ (1,0) [0|15] "" Vector__XXX
 SG_ AuxHeatActivation : 10|2@1+ (1,0) [0|3] "" Vector__XXX
 SG_ TractionHeatEnable : 8|2@1+ (1,0) [0|3] "" Vector__XXX
 SG_ DriveReady : 6|2@1+ (1,0) [0|3] "" Vector__XXX
 SG_ EngineRunning : 4|2@1+ (1,0) [0|3] "" Vector__XXX
 SG_ Ignition : 2|2@1+ (1,0) [0|3] "" Vector__XXX
 SG_ MainSwitch : 0|2@1+ (1,0) [0|3] "" Vector__XXX

BO_ 2566893849 HVAC_ST_GEN: 8 HVAC
 SG_ FillingDone : 44|2@1+ (1,0) [0|3] "-" Vector__XXX
 SG_ H2OFillModeRequest_ACT : 40|4@1+ (1,0) [0|15] "-" Vector__XXX
 SG_ AuxHeaterTempRequest : 32|8@1+ (0.4,0) [0|102] "" Vector__XXX
 SG_ FlowSwitchStatus : 20|2@1+ (1,0) [0|0] "" Vector__XXX
 SG_ AuxPumpRequest : 16|2@1+ (1,0) [0|3] "" Vector__XXX
 SG_ PTCStatus : 12|2@1+ (1,0) [0|3] "" Vector__XXX
 SG_ TractionTemperature : 56|8@1+ (0.4,0) [0|102] "C" Vector__XXX
 SG_ AmbientTemperature : 24|8@1+ (0.4,-40) [-40|62] "C" Vector__XXX
 SG_ HPUnit2On : 10|2@1+ (1,0) [0|3] "" Vector__XXX
 SG_ HPUnit1On : 8|2@1+ (1,0) [0|3] "" Vector__XXX
 SG_ TractionHeatRequest : 4|2@1+ (1,0) [0|3] "" Vector__XXX
 SG_ AuxHeatRequest : 18|2@1+ (1,0) [0|3] "" Vector__XXX
 SG_ HVRequest : 2|2@1+ (1,0) [0|3] "" Vector__XXX
 SG_ SystemOn : 0|2@1+ (1,0) [0|3] "" Vector__XXX

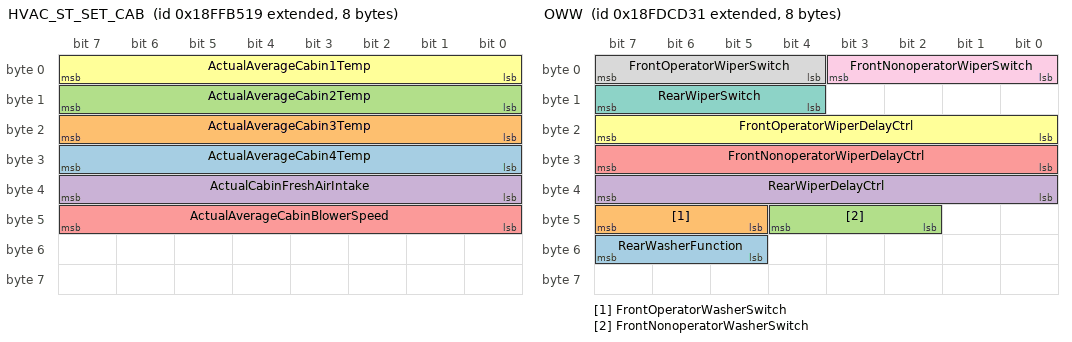
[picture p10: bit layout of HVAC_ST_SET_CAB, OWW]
BO_ 2566894873 HVAC_ST_SET_CAB: 8 HVAC
 SG_ ActualAverageCabin4Temp : 24|8@1+ (0.4,-40) [-40|62] "C" Vector__XXX
 SG_ ActualAverageCabin3Temp : 16|8@1+ (0.4,-40) [-40|62] "C" Vector__XXX
 SG_ ActualAverageCabin2Temp : 8|8@1+ (0.4,-40) [-40|62] "C" Vector__XXX
 SG_ ActualCabinFreshAirIntake : 32|8@1+ (1,0) [0|255] "%" Vector__XXX
 SG_ ActualAverageCabinBlowerSpeed : 40|8@1+ (1,0) [0|255] "%" Vector__XXX
 SG_ ActualAverageCabin1Temp : 0|8@1+ (0.4,-40) [-40|62] "C" Vector__XXX

BO_ 2566834941 DM1_WWCU: 22 WWCU
 SG_ FailureModeIdentifier5 : 160|5@1+ (1,0) [0|0] "" Vector__XXX
 SG_ FailureModeIdentifier4 : 128|5@1+ (1,0) [0|0] "" Vector__XXX
 SG_ FailureModeIdentifier3 : 96|5@1+ (1,0) [0|0] "" Vector__XXX
 SG_ FailureModeIdentifier2 : 64|5@1+ (1,0) [0|0] "" Vector__XXX
 SG_ OccurenceCount5 : 168|7@1+ (1,0) [0|126] "" Vector__XXX
 SG_ OccurenceCount4 : 136|7@1+ (1,0) [0|126] "" Vector__XXX
 SG_ OccurenceCount3 : 104|7@1+ (1,0) [0|126] "" Vector__XXX
 SG_ OccurenceCount2 : 72|7@1+ (1,0) [0|126] "" Vector__XXX
 SG_ SPNConversionMethod5 : 175|1@1+ (1,0) [0|1] "" Vector__XXX
 SG_ SPNConversionMethod4 : 143|1@1+ (1,0) [0|1] "" Vector__XXX
 SG_ SPNConversionMethod3 : 111|1@1+ (1,0) [0|1] "" Vector__XXX
 SG_ SPNConversionMethod2 : 79|1@1+ (1,0) [0|1] "" Vector__XXX
 SG_ SPN5High : 165|3@1+ (1,0) [0|7] "" Vector__XXX
 SG_ SPN5 : 144|16@1+ (1,0) [0|65536] "" Vector__XXX
 SG_ SPN4High : 133|3@1+ (1,0) [0|7] "" Vector__XXX
 SG_ SPN4 : 112|16@1+ (1,0) [0|65536] "" Vector__XXX
 SG_ SPN3High : 101|3@1+ (1,0) [0|7] "" Vector__XXX
 SG_ SPN3 : 80|16@1+ (1,0) [0|65536] "" Vector__XXX
 SG_ SPN2High : 69|3@1+ (1,0) [0|7] "" Vector__XXX
 SG_ SPN2 : 48|16@1+ (1,0) [0|65536] "" Vector__XXX
 SG_ SPN1 : 16|16@1+ (1,0) [0|65536] "" Vector__XXX
 SG_ SPNConversionMethod1 : 47|1@1+ (1,0) [0|1] "" Vector__XXX
 SG_ OccurenceCount1 : 40|7@1+ (1,0) [0|126] "" Vector__XXX
 SG_ SPN1High : 37|3@1+ (1,0) [0|7] "" Vector__XXX
 SG_ FailureModeIdentifier1 : 32|5@1+ (1,0) [0|0] "" Vector__XXX
 SG_ FlashMalfuncIndicatorLamp : 14|2@1+ (1,0) [0|3] "" Vector__XXX
 SG_ FlashRedStopLamp : 12|2@1+ (1,0) [0|3] "" Vector__XXX
 SG_ FlashAmberWarningLamp : 10|2@1+ (1,0) [0|3] "" Vector__XXX
 SG_ FlashProtectLamp : 8|2@1+ (1,0) [0|3] "" Vector__XXX
 SG_ MalfunctionIndicatorLampStatus : 6|2@1+ (1,0) [0|3] "" Vector__XXX
 SG_ RedStopLampState : 4|2@1+ (1,0) [0|3] "" Vector__XXX
 SG_ AmberWarningLampStatus : 2|2@1+ (1,0) [0|3] "" Vector__XXX
 SG_ ProtectLampStatus : 0|2@1+ (1,0) [0|3] "" Vector__XXX

BO_ 2566834713 DM1_HVAC: 22 HVAC
 SG_ FailureModeIdentifier5 : 160|5@1+ (1,0) [0|0] "" Vector__XXX
 SG_ FailureModeIdentifier4 : 128|5@1+ (1,0) [0|0] "" Vector__XXX
 SG_ FailureModeIdentifier3 : 96|5@1+ (1,0) [0|0] "" Vector__XXX
 SG_ FailureModeIdentifier2 : 64|5@1+ (1,0) [0|0] "" Vector__XXX
 SG_ OccurenceCount5 : 168|7@1+ (1,0) [0|126] "" Vector__XXX
 SG_ OccurenceCount4 : 136|7@1+ (1,0) [0|126] "" Vector__XXX
 SG_ OccurenceCount3 : 104|7@1+ (1,0) [0|126] "" Vector__XXX
 SG_ OccurenceCount2 : 72|7@1+ (1,0) [0|126] "" Vector__XXX
 SG_ SPNConversionMethod5 : 175|1@1+ (1,0) [0|1] "" Vector__XXX
 SG_ SPNConversionMethod4 : 143|1@1+ (1,0) [0|1] "" Vector__XXX
 SG_ SPNConversionMethod3 : 111|1@1+ (1,0) [0|1] "" Vector__XXX
 SG_ SPNConversionMethod2 : 79|1@1+ (1,0) [0|1] "" Vector__XXX
 SG_ SPN5High : 165|3@1+ (1,0) [0|7] "" Vector__XXX
 SG_ SPN5 : 144|16@1+ (1,0) [0|65536] "" Vector__XXX
 SG_ SPN4High : 133|3@1+ (1,0) [0|7] "" Vector__XXX
 SG_ SPN4 : 112|16@1+ (1,0) [0|65536] "" Vector__XXX
 SG_ SPN3High : 101|3@1+ (1,0) [0|7] "" Vector__XXX
 SG_ SPN3 : 80|16@1+ (1,0) [0|65536] "" Vector__XXX
 SG_ SPN2High : 69|3@1+ (1,0) [0|7] "" Vector__XXX
 SG_ SPN2 : 48|16@1+ (1,0) [0|65536] "" Vector__XXX
 SG_ SPN1 : 16|16@1+ (1,0) [0|65536] "" Vector__XXX
 SG_ SPNConversionMethod1 : 47|1@1+ (1,0) [0|1] "" Vector__XXX
 SG_ OccurenceCount1 : 40|7@1+ (1,0) [0|126] "" Vector__XXX
 SG_ SPN1High : 37|3@1+ (1,0) [0|7] "" Vector__XXX
 SG_ FailureModeIdentifier1 : 32|5@1+ (1,0) [0|0] "" Vector__XXX
 SG_ FlashMalfuncIndicatorLamp : 14|2@1+ (1,0) [0|3] "" Vector__XXX
 SG_ FlashRedStopLamp : 12|2@1+ (1,0) [0|3] "" Vector__XXX
 SG_ FlashAmberWarningLamp : 10|2@1+ (1,0) [0|3] "" Vector__XXX
 SG_ FlashProtectLamp : 8|2@1+ (1,0) [0|3] "" Vector__XXX
 SG_ MalfunctionIndicatorLampStatus : 6|2@1+ (1,0) [0|3] "" Vector__XXX
 SG_ RedStopLampState : 4|2@1+ (1,0) [0|3] "" Vector__XXX
 SG_ AmberWarningLampStatus : 2|2@1+ (1,0) [0|3] "" Vector__XXX
 SG_ ProtectLampStatus : 0|2@1+ (1,0) [0|3] "" Vector__XXX

BO_ 2365531141 CL_DNR: 8 VFC
 SG_ Illumination : 0|8@1+ (0.4,0) [0|100] "%" Vector__XXX

BO_ 2566769969 OWW: 8 VFC
 SG_ RearWasherFunction : 53|3@1+ (1,0) [0|7] "" Vector__XXX
 SG_ FrontOperatorWasherSwitch : 45|3@1+ (1,0) [0|7] "" Vector__XXX
 SG_ FrontNonoperatorWasherSwitch : 42|3@1+ (1,0) [0|7] "" Vector__XXX
 SG_ RearWiperDelayCtrl : 32|8@1+ (0.4,0) [0|100] "%" Vector__XXX
 SG_ FrontNonoperatorWiperDelayCtrl : 24|8@1+ (0.4,0) [0|100] "%" Vector__XXX
 SG_ FrontOperatorWiperDelayCtrl : 16|8@1+ (0.4,0) [0|100] "%" Vector__XXX
 SG_ RearWiperSwitch : 12|4@1+ (1,0) [0|15] "" Vector__XXX
 SG_ FrontOperatorWiperSwitch : 4|4@1+ (1,0) [0|15] "" Vector__XXX
 SG_ FrontNonoperatorWiperSwitch : 0|4@1+ (1,0) [0|15] "" Vector__XXX

BO_ 2561271857 FLIC: 8 VFC
 SG_ LaneDepartureWarningEnableCmd : 0|2@1+ (1,0) [0|3] ""  LDWS

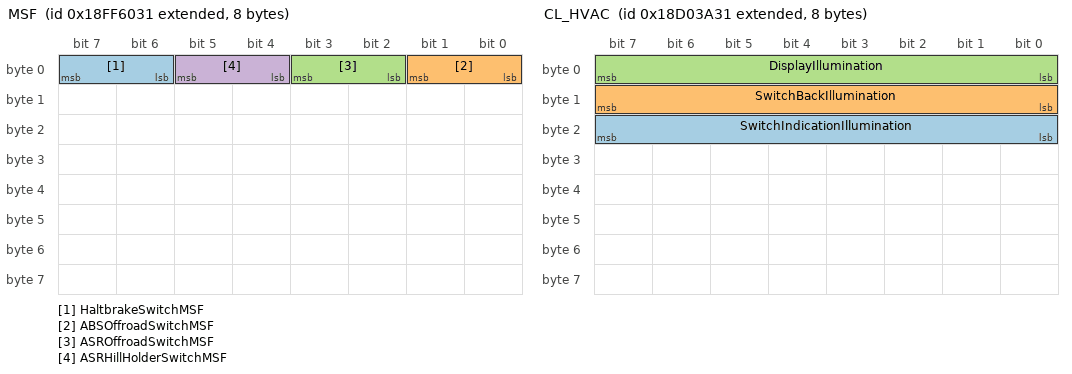
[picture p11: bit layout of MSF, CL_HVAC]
BO_ 2566873137 MSF: 8 VFC
 SG_ HaltbrakeSwitchMSF : 6|2@1+ (1,0) [0|0] "" Vector__XXX
 SG_ ABSOffroadSwitchMSF : 0|2@1+ (1,0) [0|0] "" Vector__XXX
 SG_ ASROffroadSwitchMSF : 2|2@1+ (1,0) [0|0] "" Vector__XXX
 SG_ ASRHillHolderSwitchMSF : 4|2@1+ (1,0) [0|0] "" Vector__XXX

BO_ 2563804199 CL_SCSM: 8 VFC
 SG_ Illumination : 0|8@1+ (0.4,0) [0|100] "%"  SCSM

BO_ 2563788071 CL_SWS: 8 VFC
 SG_ Illumination : 0|8@1+ (0.4,0) [0|100] "%"  SWS

BO_ 2563783217 CL_HVAC: 8 VFC
 SG_ SwitchIndicationIllumination : 16|8@1+ (0.4,0) [0|100] "%"  HVAC_HMI
 SG_ SwitchBackIllumination : 8|8@1+ (0.4,0) [0|100] "%"  HVAC_HMI
 SG_ DisplayIllumination : 0|8@1+ (0.4,0) [0|100] "%"  HVAC_HMI

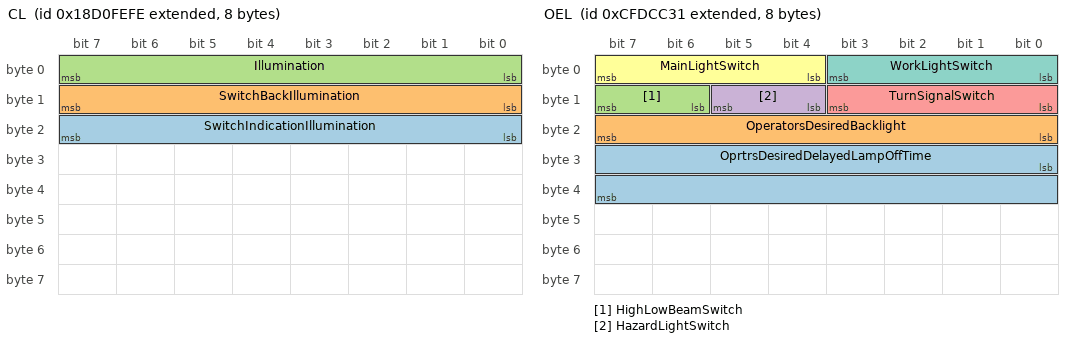
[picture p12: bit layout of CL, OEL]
BO_ 2563833598 CL: 8 Vector__XXX
 SG_ SwitchIndicationIllumination : 16|8@1+ (0.4,0) [0|100] "%" Vector__XXX
 SG_ SwitchBackIllumination : 8|8@1+ (0.4,0) [0|100] "%" Vector__XXX
 SG_ Illumination : 0|8@1+ (0.4,0) [0|100] "%" Vector__XXX

BO_ 2365443121 OEL: 8 VFC
 SG_ OprtrsDesiredDelayedLampOffTime : 24|16@1+ (1,0) [0|64255] "s" Vector__XXX
 SG_ OperatorsDesiredBacklight : 16|8@1+ (0.4,0) [0|100] "%" Vector__XXX
 SG_ HighLowBeamSwitch : 14|2@1+ (1,0) [0|3] "" Vector__XXX
 SG_ HazardLightSwitch : 12|2@1+ (1,0) [0|3] "" Vector__XXX
 SG_ TurnSignalSwitch : 8|4@1+ (1,0) [0|15] "" Vector__XXX
 SG_ MainLightSwitch : 4|4@1+ (1,0) [0|15] "" Vector__XXX
 SG_ WorkLightSwitch : 0|4@1+ (1,0) [0|15] "" Vector__XXX

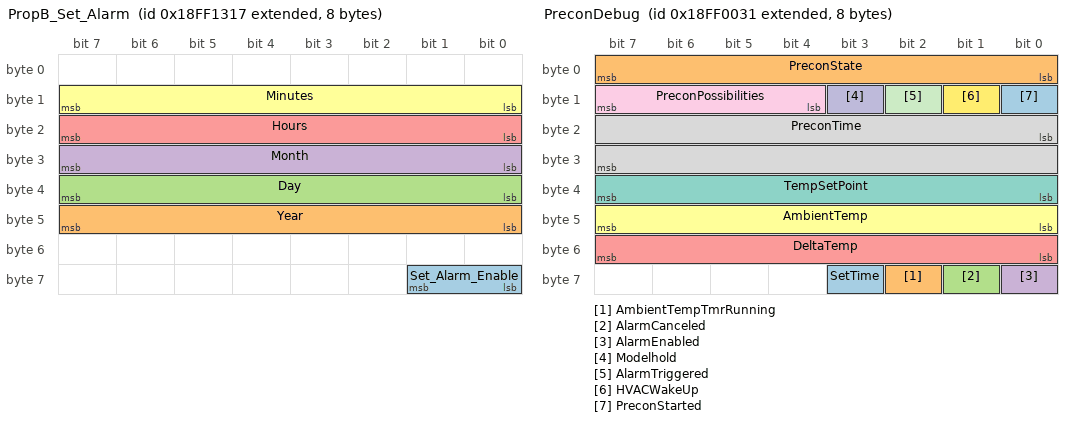
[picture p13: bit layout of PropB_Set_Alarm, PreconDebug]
BO_ 2566853399 PropB_Set_Alarm: 8 EPIC
 SG_ Set_Alarm_Enable : 56|2@1+ (1,0) [0|0] "" Vector__XXX
 SG_ Year : 40|8@1+ (1,1985) [1985|2235] "years" Vector__XXX
 SG_ Day : 32|8@1+ (0.25,0) [0|62.5] "days" Vector__XXX
 SG_ Month : 24|8@1+ (1,0) [0|250] "months" Vector__XXX
 SG_ Hours : 16|8@1+ (1,0) [0|250] "hr" Vector__XXX
 SG_ Minutes : 8|8@1+ (1,0) [0|250] "min" Vector__XXX

BO_ 2566848561 PreconDebug: 8 VFC
 SG_ SetTime : 59|1@1+ (1,0) [0|1] "" Vector__XXX
 SG_ AmbientTempTmrRunning : 58|1@1+ (1,0) [0|1] "" Vector__XXX
 SG_ AlarmCanceled : 57|1@1+ (1,0) [0|1] "" Vector__XXX
 SG_ AlarmEnabled : 56|1@1+ (1,0) [0|1] "" Vector__XXX
 SG_ DeltaTemp : 48|8@1+ (1,0) [0|255] "" Vector__XXX
 SG_ AmbientTemp : 40|8@1+ (1,0) [0|255] "" Vector__XXX
 SG_ TempSetPoint : 32|8@1+ (1,0) [0|255] "" Vector__XXX
 SG_ PreconTime : 16|16@1+ (1,0) [0|65535] "" Vector__XXX
 SG_ PreconPossibilities : 12|4@1+ (1,0) [0|15] "" Vector__XXX
 SG_ Modelhold : 11|1@1+ (1,0) [0|1] "" Vector__XXX
 SG_ AlarmTriggered : 10|1@1+ (1,0) [0|1] "" Vector__XXX
 SG_ HVACWakeUp : 9|1@1+ (1,0) [0|1] "" Vector__XXX
 SG_ PreconStarted : 8|1@1+ (1,0) [0|1] "" Vector__XXX
 SG_ PreconState : 0|8@1+ (1,0) [0|255] "" Vector__XXX

BO_ 2566848817 PreconDebug2: 8 VFC
 SG_ SystemTime : 32|32@1+ (1,0) [0|4294967295] "" Vector__XXX
 SG_ CurrentAlarmTime : 0|32@1+ (1,0) [0|4294967295] "" Vector__XXX

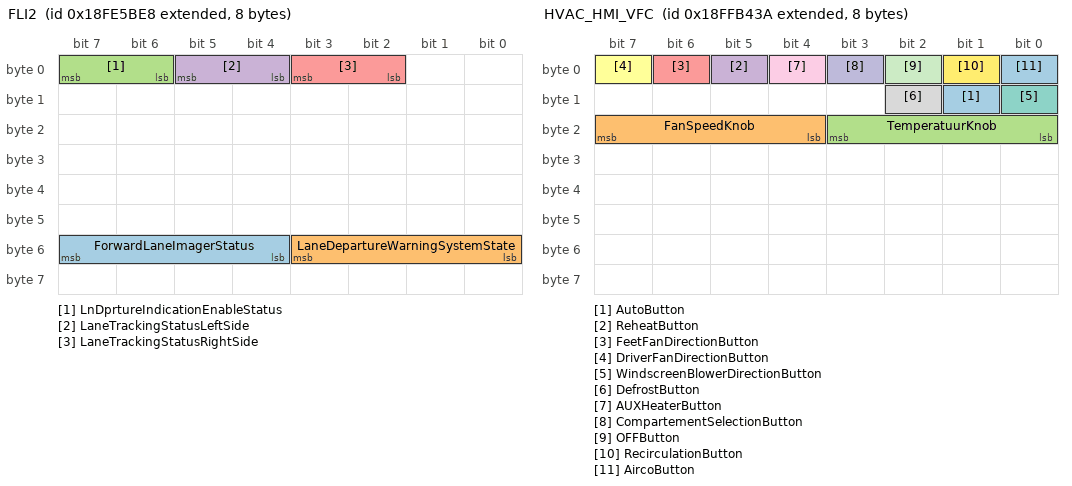
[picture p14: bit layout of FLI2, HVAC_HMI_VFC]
BO_ 2566806504 FLI2: 8 LDWS
 SG_ ForwardLaneImagerStatus : 52|4@1+ (1,0) [0|0] "" Vector__XXX
 SG_ LaneDepartureWarningSystemState : 48|4@1+ (1,0) [0|0] "" Vector__XXX
 SG_ LnDprtureIndicationEnableStatus : 6|2@1+ (1,0) [0|3] "" Vector__XXX
 SG_ LaneTrackingStatusLeftSide : 4|2@1+ (1,0) [0|3] "" Vector__XXX
 SG_ LaneTrackingStatusRightSide : 2|2@1+ (1,0) [0|3] "" Vector__XXX

BO_ 2431649768 FLI1: 8 LDWS
 SG_ LaneDepartureImminentLeftSide : 6|2@1+ (1,0) [0|3] "" Vector__XXX
 SG_ LaneDepartureImminentRightSide : 4|2@1+ (1,0) [0|3] "" Vector__XXX

BO_ 2566894650 HVAC_HMI_VFC: 8 HVAC_HMI
 SG_ AutoButton : 9|1@1+ (1,0) [0|0] "" Vector__XXX
 SG_ FanSpeedKnob : 20|4@1+ (1,-5) [0|0] "" Vector__XXX
 SG_ TemperatuurKnob : 16|4@1+ (1,-5) [0|0] "" Vector__XXX
 SG_ ReheatButton : 5|1@1+ (1,0) [0|0] "" Vector__XXX
 SG_ FeetFanDirectionButton : 6|1@1+ (1,0) [0|0] "" Vector__XXX
 SG_ DriverFanDirectionButton : 7|1@1+ (1,0) [0|0] "" Vector__XXX
 SG_ WindscreenBlowerDirectionButton : 8|1@1+ (1,0) [0|0] "" Vector__XXX
 SG_ DefrostButton : 10|1@1+ (1,0) [0|0] "" Vector__XXX
 SG_ AUXHeaterButton : 4|1@1+ (1,0) [0|0] "" Vector__XXX
 SG_ CompartementSelectionButton : 3|1@1+ (1,0) [0|0] "" Vector__XXX
 SG_ OFFButton : 2|1@1+ (1,0) [0|0] "" Vector__XXX
 SG_ RecirculationButton : 1|1@1+ (1,0) [0|0] "" Vector__XXX
 SG_ AircoButton : 0|1@1+ (1,0) [0|0] "" Vector__XXX

BO_ 2565867787 VDC2: 8 EBS
 SG_ SteerWheelAngle : 0|16@1+ (0.000976563,-31.374) [-31.374|31.374] "rad" Vector__XXX

BO_ 2349399885 SWS_2: 8 SWS
 SG_ AUX_IO_Channel6 : 0|16@1+ (1,0) [0|64255] "count" Vector__XXX

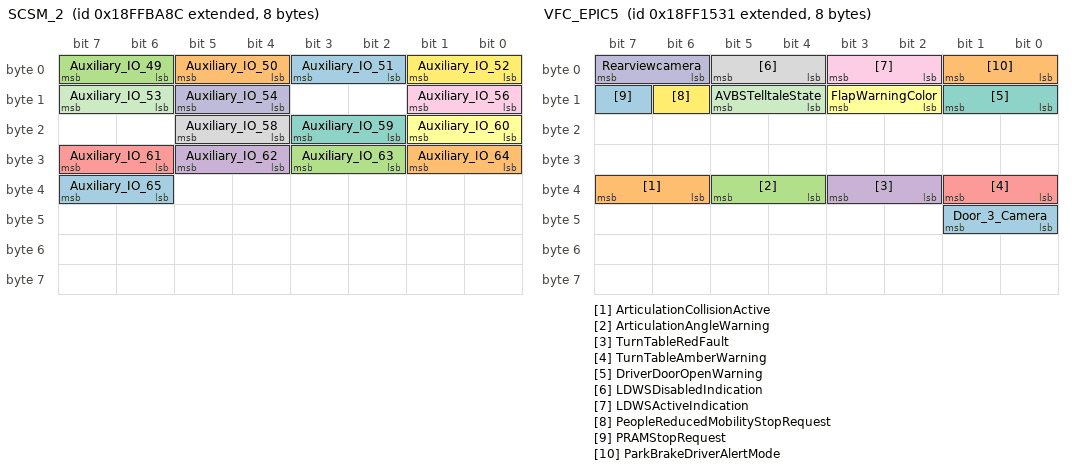
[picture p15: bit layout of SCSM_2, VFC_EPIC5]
BO_ 2566896268 SCSM_2: 8 SCSM
 SG_ Auxiliary_IO_65 : 38|2@1+ (1,0) [0|3] "" Vector__XXX
 SG_ Auxiliary_IO_64 : 24|2@1+ (1,0) [0|3] "" Vector__XXX
 SG_ Auxiliary_IO_63 : 26|2@1+ (1,0) [0|3] "" Vector__XXX
 SG_ Auxiliary_IO_62 : 28|2@1+ (1,0) [0|3] "" Vector__XXX
 SG_ Auxiliary_IO_61 : 30|2@1+ (1,0) [0|3] "" Vector__XXX
 SG_ Auxiliary_IO_60 : 16|2@1+ (1,0) [0|3] "" Vector__XXX
 SG_ Auxiliary_IO_59 : 18|2@1+ (1,0) [0|3] "" Vector__XXX
 SG_ Auxiliary_IO_58 : 20|2@1+ (1,0) [0|3] "" Vector__XXX
 SG_ Auxiliary_IO_56 : 8|2@1+ (1,0) [0|3] "" Vector__XXX
 SG_ Auxiliary_IO_54 : 12|2@1+ (1,0) [0|3] "" Vector__XXX
 SG_ Auxiliary_IO_53 : 14|2@1+ (1,0) [0|3] "" Vector__XXX
 SG_ Auxiliary_IO_52 : 0|2@1+ (1,0) [0|3] "" Vector__XXX
 SG_ Auxiliary_IO_51 : 2|2@1+ (1,0) [0|3] "" Vector__XXX
 SG_ Auxiliary_IO_50 : 4|2@1+ (1,0) [0|3] "" Vector__XXX
 SG_ Auxiliary_IO_49 : 6|2@1+ (1,0) [0|3] "" Vector__XXX

BO_ 2566873740 SCSM_1: 8 SCSM
 SG_ MessageCounter_SCSM1 : 56|4@1+ (1,0) [0|15] "" Vector__XXX
 SG_ MessageChecksum_SCSM1 : 60|4@1+ (1,0) [0|15] "" Vector__XXX
 SG_ Auxiliary_IO_32 : 24|2@1+ (1,0) [0|3] "" Vector__XXX
 SG_ Auxiliary_IO_31 : 26|2@1+ (1,0) [0|3] "" Vector__XXX
 SG_ Auxiliary_IO_30 : 28|2@1+ (1,0) [0|3] "" Vector__XXX
 SG_ Auxiliary_IO_29 : 30|2@1+ (1,0) [0|3] "" Vector__XXX
 SG_ Auxiliary_IO_28 : 16|2@1+ (1,0) [0|3] "" Vector__XXX
 SG_ Auxiliary_IO_27 : 18|2@1+ (1,0) [0|3] "" Vector__XXX
 SG_ Auxiliary_IO_26 : 20|2@1+ (1,0) [0|3] "" Vector__XXX
 SG_ Auxiliary_IO_25 : 22|2@1+ (1,0) [0|3] "" Vector__XXX
 SG_ Auxiliary_IO_24 : 8|2@1+ (1,0) [0|3] "" Vector__XXX
 SG_ Auxiliary_IO_23 : 10|2@1+ (1,0) [0|3] "" Vector__XXX
 SG_ Auxiliary_IO_22 : 12|2@1+ (1,0) [0|3] "" Vector__XXX
 SG_ Auxiliary_IO_21 : 14|2@1+ (1,0) [0|3] "" Vector__XXX
 SG_ Auxiliary_IO_20 : 0|2@1+ (1,0) [0|3] "" Vector__XXX
 SG_ Auxiliary_IO_19 : 2|2@1+ (1,0) [0|3] "" Vector__XXX
 SG_ Auxiliary_IO_18 : 4|2@1+ (1,0) [0|3] "" Vector__XXX
 SG_ Auxiliary_IO_17 : 6|2@1+ (1,0) [0|3] "" Vector__XXX

BO_ 2561015629 SWS_1: 8 SWS
 SG_ Auxiliary_IO_96 : 24|2@1+ (1,0) [0|3] "" Vector__XXX
 SG_ Auxiliary_IO_93 : 30|2@1+ (1,0) [0|3] "" Vector__XXX
 SG_ Auxiliary_IO_98 : 36|2@1+ (1,0) [0|3] "" Vector__XXX
 SG_ Auxiliary_IO_99 : 34|2@1+ (1,0) [0|3] "" Vector__XXX
 SG_ Auxiliary_IO_100 : 32|2@1+ (1,0) [0|3] "" Vector__XXX
 SG_ Auxiliary_IO_95 : 26|2@1+ (1,0) [0|3] "" Vector__XXX
 SG_ Auxiliary_IO_94 : 28|2@1+ (1,0) [0|3] "" Vector__XXX
 SG_ Auxiliary_IO_92 : 16|2@1+ (1,0) [0|3] "" Vector__XXX
 SG_ Auxiliary_IO_91 : 18|2@1+ (1,0) [0|3] "" Vector__XXX
 SG_ Auxiliary_IO_90 : 20|2@1+ (1,0) [0|3] "" Vector__XXX
 SG_ Auxiliary_IO_89 : 22|2@1+ (1,0) [0|3] "" Vector__XXX
 SG_ Auxiliary_IO_88 : 8|2@1+ (1,0) [0|3] "" Vector__XXX
 SG_ Auxiliary_IO_87 : 10|2@1+ (1,0) [0|3] "" Vector__XXX
 SG_ Auxiliary_IO_86 : 12|2@1+ (1,0) [0|3] "" Vector__XXX
 SG_ Auxiliary_IO_85 : 14|2@1+ (1,0) [0|3] "" Vector__XXX
 SG_ Auxiliary_IO_81 : 6|2@1+ (1,0) [0|3] "" Vector__XXX
 SG_ Auxiliary_IO_82 : 4|2@1+ (1,0) [0|3] "" Vector__XXX
 SG_ Auxiliary_IO_84 : 0|2@1+ (1,0) [0|3] "" Vector__XXX

BO_ 2566834828 DM1_SCSM: 22 SCSM
 SG_ FailureModeIdentifier5 : 160|5@1+ (1,0) [0|0] "" Vector__XXX
 SG_ FailureModeIdentifier4 : 128|5@1+ (1,0) [0|0] "" Vector__XXX
 SG_ FailureModeIdentifier3 : 96|5@1+ (1,0) [0|0] "" Vector__XXX
 SG_ FailureModeIdentifier2 : 64|5@1+ (1,0) [0|0] "" Vector__XXX
 SG_ OccurenceCount5 : 168|7@1+ (1,0) [0|126] "" Vector__XXX
 SG_ OccurenceCount4 : 136|7@1+ (1,0) [0|126] "" Vector__XXX
 SG_ OccurenceCount3 : 104|7@1+ (1,0) [0|126] "" Vector__XXX
 SG_ OccurenceCount2 : 72|7@1+ (1,0) [0|126] "" Vector__XXX
 SG_ SPNConversionMethod5 : 175|1@1+ (1,0) [0|1] "" Vector__XXX
 SG_ SPNConversionMethod4 : 143|1@1+ (1,0) [0|1] "" Vector__XXX
 SG_ SPNConversionMethod3 : 111|1@1+ (1,0) [0|1] "" Vector__XXX
 SG_ SPNConversionMethod2 : 79|1@1+ (1,0) [0|1] "" Vector__XXX
 SG_ SPN5High : 165|3@1+ (1,0) [0|7] "" Vector__XXX
 SG_ SPN5 : 144|16@1+ (1,0) [0|65536] "" Vector__XXX
 SG_ SPN4High : 133|3@1+ (1,0) [0|7] "" Vector__XXX
 SG_ SPN4 : 112|16@1+ (1,0) [0|65536] "" Vector__XXX
 SG_ SPN3High : 101|3@1+ (1,0) [0|7] "" Vector__XXX
 SG_ SPN3 : 80|16@1+ (1,0) [0|65536] "" Vector__XXX
 SG_ SPN2High : 69|3@1+ (1,0) [0|7] "" Vector__XXX
 SG_ SPN2 : 48|16@1+ (1,0) [0|65536] "" Vector__XXX
 SG_ SPN1 : 16|16@1+ (1,0) [0|65536] "" Vector__XXX
 SG_ SPNConversionMethod1 : 47|1@1+ (1,0) [0|1] "" Vector__XXX
 SG_ OccurenceCount1 : 40|7@1+ (1,0) [0|126] "" Vector__XXX
 SG_ SPN1High : 37|3@1+ (1,0) [0|7] "" Vector__XXX
 SG_ FailureModeIdentifier1 : 32|5@1+ (1,0) [0|0] "" Vector__XXX
 SG_ FlashMalfuncIndicatorLamp : 14|2@1+ (1,0) [0|3] "" Vector__XXX
 SG_ FlashRedStopLamp : 12|2@1+ (1,0) [0|3] "" Vector__XXX
 SG_ FlashAmberWarningLamp : 10|2@1+ (1,0) [0|3] "" Vector__XXX
 SG_ FlashProtectLamp : 8|2@1+ (1,0) [0|3] "" Vector__XXX
 SG_ MalfunctionIndicatorLampStatus : 6|2@1+ (1,0) [0|3] "" Vector__XXX
 SG_ RedStopLampState : 4|2@1+ (1,0) [0|3] "" Vector__XXX
 SG_ AmberWarningLampStatus : 2|2@1+ (1,0) [0|3] "" Vector__XXX
 SG_ ProtectLampStatus : 0|2@1+ (1,0) [0|3] "" Vector__XXX

BO_ 2565799719 SORT: 8 Vector__XXX
 SG_ AUTOSORT : 2|2@1+ (1,0) [0|0] "" Vector__XXX

BO_ 2566678856 EVOI1: 8 VCU2
 SG_ EstimatedRemainingDistance : 0|16@1+ (0.25,0) [0|0] "km" Vector__XXX

BO_ 2566853937 VFC_EPIC5: 8 VFC
 SG_ Door_3_Camera : 40|2@1+ (1,0) [0|0] "" Vector__XXX
 SG_ ArticulationCollisionActive : 38|2@1+ (1,0) [0|0] "" Vector__XXX
 SG_ ArticulationAngleWarning : 36|2@1+ (1,0) [0|0] "" Vector__XXX
 SG_ TurnTableRedFault : 34|2@1+ (1,0) [0|0] "" Vector__XXX
 SG_ TurnTableAmberWarning : 32|2@1+ (1,0) [0|0] "" Vector__XXX
 SG_ FlapWarningColor : 10|2@1+ (1,0) [0|0] "" Vector__XXX
 SG_ DriverDoorOpenWarning : 8|2@1+ (1,0) [0|0] "" Vector__XXX
 SG_ LDWSDisabledIndication : 4|2@1+ (1,0) [0|0] "" Vector__XXX
 SG_ LDWSActiveIndication : 2|2@1+ (1,0) [0|0] "" Vector__XXX
 SG_ Rearviewcamera : 6|2@1+ (1,0) [0|0] "" Vector__XXX
 SG_ AVBSTelltaleState : 12|2@1+ (1,0) [0|0] "" Vector__XXX
 SG_ PeopleReducedMobilityStopRequest : 14|1@1+ (1,0) [0|0] "" Vector__XXX
 SG_ PRAMStopRequest : 15|1@1+ (1,0) [0|0] "" Vector__XXX
 SG_ ParkBrakeDriverAlertMode : 0|2@1+ (1,0) [0|0] "" Vector__XXX

BO_ 2566834698 DM1_EPHS: 22 EPHS
 SG_ FailureModeIdentifier5 : 160|5@1+ (1,0) [0|0] "" Vector__XXX
 SG_ FailureModeIdentifier4 : 128|5@1+ (1,0) [0|0] "" Vector__XXX
 SG_ FailureModeIdentifier3 : 96|5@1+ (1,0) [0|0] "" Vector__XXX
 SG_ FailureModeIdentifier2 : 64|5@1+ (1,0) [0|0] "" Vector__XXX
 SG_ OccurenceCount5 : 168|7@1+ (1,0) [0|126] "" Vector__XXX
 SG_ OccurenceCount4 : 136|7@1+ (1,0) [0|126] "" Vector__XXX
 SG_ OccurenceCount3 : 104|7@1+ (1,0) [0|126] "" Vector__XXX
 SG_ OccurenceCount2 : 72|7@1+ (1,0) [0|126] "" Vector__XXX
 SG_ SPNConversionMethod5 : 175|1@1+ (1,0) [0|1] "" Vector__XXX
 SG_ SPNConversionMethod4 : 143|1@1+ (1,0) [0|1] "" Vector__XXX
 SG_ SPNConversionMethod3 : 111|1@1+ (1,0) [0|1] "" Vector__XXX
 SG_ SPNConversionMethod2 : 79|1@1+ (1,0) [0|1] "" Vector__XXX
 SG_ SPN5High : 165|3@1+ (1,0) [0|7] "" Vector__XXX
 SG_ SPN5 : 144|16@1+ (1,0) [0|65536] "" Vector__XXX
 SG_ SPN4High : 133|3@1+ (1,0) [0|7] "" Vector__XXX
 SG_ SPN4 : 112|16@1+ (1,0) [0|65536] "" Vector__XXX
 SG_ SPN3High : 101|3@1+ (1,0) [0|7] "" Vector__XXX
 SG_ SPN3 : 80|16@1+ (1,0) [0|65536] "" Vector__XXX
 SG_ SPN2High : 69|3@1+ (1,0) [0|7] "" Vector__XXX
 SG_ SPN2 : 48|16@1+ (1,0) [0|65536] "" Vector__XXX
 SG_ SPN1 : 16|16@1+ (1,0) [0|65536] "" Vector__XXX
 SG_ SPNConversionMethod1 : 47|1@1+ (1,0) [0|1] "" Vector__XXX
 SG_ OccurenceCount1 : 40|7@1+ (1,0) [0|126] "" Vector__XXX
 SG_ SPN1High : 37|3@1+ (1,0) [0|7] "" Vector__XXX
 SG_ FailureModeIdentifier1 : 32|5@1+ (1,0) [0|0] "" Vector__XXX
 SG_ FlashMalfuncIndicatorLamp : 14|2@1+ (1,0) [0|3] "" Vector__XXX
 SG_ FlashRedStopLamp : 12|2@1+ (1,0) [0|3] "" Vector__XXX
 SG_ FlashAmberWarningLamp : 10|2@1+ (1,0) [0|3] "" Vector__XXX
 SG_ FlashProtectLamp : 8|2@1+ (1,0) [0|3] "" Vector__XXX
 SG_ MalfunctionIndicatorLampStatus : 6|2@1+ (1,0) [0|3] "" Vector__XXX
 SG_ RedStopLampState : 4|2@1+ (1,0) [0|3] "" Vector__XXX
 SG_ AmberWarningLampStatus : 2|2@1+ (1,0) [0|3] "" Vector__XXX
 SG_ ProtectLampStatus : 0|2@1+ (1,0) [0|3] "" Vector__XXX

BO_ 2566840303 EEC3: 8 DCU
 SG_ NominalFrictionPercentTorque : 0|8@1+ (1,-125) [-125|125] "%" Vector__XXX

CM_ BO_ 2566845491 "Tire Condition";
CM_ SG_ 2566845491 TirePressThresholdDetection "Signal indicating the pressure level of the tire.";
CM_ SG_ 2566845491 TireAirLeakageRate "The pressure loss rate of a tire.";
CM_ SG_ 2566845491 CTIWheelEndElectricalFault "Indicates the status of electrical fault on CTI wheel interface.";
CM_ SG_ 2566845491 CTITireStatus "Indicates the status of the tire.";
CM_ SG_ 2566845491 CTIWheelSensorStatus "Indicates whether the wheel is being monitored by the CTI controller.";
CM_ SG_ 2566845491 TireTemp "Temperature at the surface of the tire sidewall.";
CM_ SG_ 2566845491 TirePress "Pressure at which air is contained in cavity formed by tire and rim.";
CM_ SG_ 2566845491 TireLocation "Identifies which tire is associated with the parametric data in this PGN.";
CM_ BO_ 2432593706 "Adaptive Cruise Control";
CM_ SG_ 2432593706 ACCDistanceAlertSignal "Signal to indicate to the operator that the ACC system is not able to maintain the distance to the target.";
CM_ SG_ 2432593706 ACCSystemShutoffWarning "Signal to warn the driver of system deactivation due to non-driver actions.";
CM_ SG_ 2432593706 ACCTargetDetected "Signal to indicate to the driver that the ACC system has detected a target.";
CM_ SG_ 2432593706 RoadCurvature "Estimated value of the current road curvature for use by the adaptive cruise control system.";
CM_ SG_ 2432593706 AdptveCruiseCtrlSetDistanceMode "Selected distance mode for adaptive cruise control.";
CM_ SG_ 2432593706 AdaptiveCruiseCtrlMode "This parameter is used to indicate the current state, or mode, of operation by the Adaptive Cruise Control (ACC) device.";
CM_ SG_ 2432593706 AdaptiveCruiseCtrlSetSpeed "Value of the desired (chosen) velocity of the adaptive cruise control system.";
CM_ SG_ 2432593706 DistanceToForwardVehicle "Distance to the preceding vehicle situated within 250 m in the same lane and moving in the same direction.";
CM_ SG_ 2432593706 SpeedOfForwardVehicle "Absolute velocity of the preceding vehicle situated within 250 m in the same lane and moving in the same direction.";
CM_ BO_ 2364551072 "Advanced Emergency Braking System 1";
CM_ BO_ 2566767627 "Electronic Brake Controller 5";
CM_ SG_ 2566767627 BrakeTempWarning "This parameter indicates if the temperature in the service brakes exceeds a certain value.";
CM_ SG_ 2566767627 XBRAccelerationLimit "The brake system may temporarily or generally limit the maximum brake performance available for external systems.";
CM_ SG_ 2566767627 XBRActiveCtrlMode "This parameter indicates which XBR Control Mode is executed by the brake system.";
CM_ SG_ 2566767627 XBRSystemState "This parameter indicates which external brake control is allowed.";
CM_ SG_ 2566767627 FoundationBrakeUse "This parameter indicates if the brake system presently uses the foundation brakes.";
CM_ SG_ 2566767627 HillHolderMode "Signal which indicates the current mode of the hill holder function.";
CM_ SG_ 2566767627 HaltBrakeMode "Signal which indicates the current mode of the halt brake function.";
CM_ BO_ 2565865739 "Electronic Brake Controller 1";
CM_ SG_ 2565865739 SrcAddrssOfCtrllngDvcFrBrkCntrl "The source address of the SAE J1939 device currently controlling the brake system.";
CM_ SG_ 2565865739 BrakePedalPos "Ratio of brake pedal position to maximum pedal position.";
CM_ SG_ 2565865739 TrctrMntdTrilerABSWarningSignal "This parameter commands the tractor-mounted trailer ABS optical warning signal.";
CM_ SG_ 2565865739 TrailerABSStatus "State signal which indicates that ABS in the trailer is actively controlling the brakes.";
CM_ SG_ 2565865739 HaltBrakeSwitch "Switch signal which indicates the position of the halt brake switch.";
CM_ SG_ 2565865739 ATC_ASRInformationSignal "This parameter commands the ATC/ASR driver information signal, for example a dash lamp.";
CM_ SG_ 2565865739 RemoteAccelEnableSwitch "Switch signal which indicates that the remote accelerator has been enabled and controls the engine.";
CM_ SG_ 2565865739 EngAuxEngShutdownSwitch "Switch signal which requests that all engine fueling stop.";
CM_ SG_ 2565865739 EngDerateSwitch "Switch signal used to activate the torque limiting feature of the engine.";
CM_ SG_ 2565865739 AccelInterlockSwitch "Switch signal used to disable the accelerator and remote accelerator inputs, causing the engine to return to idle.";
CM_ SG_ 2565865739 TractionCtrlOverrideSwitch "Switch signal which indicates the position of the traction control override switch.";
CM_ SG_ 2565865739 ASRHillHolderSwitch "Switch signal which indicates the position of the ASR “hill holder” switch.";
CM_ SG_ 2565865739 ASROffroadSwitch "Switch signal which indicates the position of the ASR off-road switch.";
CM_ SG_ 2565865739 ABSOffroadSwitch "Switch signal which indicates the position of the ABS off-road switch.";
CM_ SG_ 2565865739 EBSBrakeSwitch "Switch signal which indicates that the brake pedal is being pressed.";
CM_ SG_ 2565865739 AntiLockBrakingActive "State signal which indicates that the ABS is active.";
CM_ SG_ 2565865739 ASRBrakeCtrlActive "State signal which indicates that ASR brake control is active.";
CM_ SG_ 2565865739 ASREngCtrlActive "State signal which indicates that ASR engine control has been commanded to be active.";
CM_ BO_ 2633935883 "Wheel Brake Lining Remaining Information";
CM_ SG_ 2633935883 BrkLnngRmnngRearAxle3RightWheel "The percentage of brake lining which can still be measured for the right wheel on the rear axle #3.";
CM_ SG_ 2633935883 BrkLnngRmningRearAxle3LeftWheel "The percentage of brake lining which can still be measured for the left wheel on the rear axle #3.";
CM_ SG_ 2633935883 BrkLnngRmnngRearAxle2RightWheel "The percentage of brake lining which can still be measured for the right wheel on the rear axle #2.";
CM_ SG_ 2633935883 BrkLnngRmningRearAxle2LeftWheel "The percentage of brake lining which can still be measured for the left wheel on the rear axle #2.";
CM_ SG_ 2633935883 BrkLnngRmnngRearAxle1RightWheel "The percentage of brake lining which can still be measured for the right wheel on the rear axle #1.";
CM_ SG_ 2633935883 BrkLnngRmningRearAxle1LeftWheel "The percentage of brake lining which can still be measured for the left wheel on the rear axle #1.";
CM_ SG_ 2633935883 BrkLnngRmnngFrontAxleRightWheel "The percentage of brake lining which can still be measured for the right wheel on the front axle.";
CM_ SG_ 2633935883 BrkLnngRmningFrontAxleLeftWheel "The percentage of brake lining which can still be measured for the left wheel on the front axle.";
CM_ BO_ 2566831883 "Wheel Speed Information";
CM_ SG_ 2566831883 RlativeSpeedRearAxle2RightWheel "The speed of the rear axle #2, right wheel relative to the front axle speed, SPN 904.";
CM_ SG_ 2566831883 RelativeSpeedRearAxle2LeftWheel "The speed of the rear axle #2, left wheel relative to the front axle speed, SPN 904.";
CM_ SG_ 2566831883 RlativeSpeedRearAxle1RightWheel "The speed of the rear axle #1, right wheel relative to the front axle speed, SPN 904.";
CM_ SG_ 2566831883 RelativeSpeedRearAxle1LeftWheel "The speed of the rear axle #1, left wheel relative to the front axle speed, SPN 904.";
CM_ SG_ 2566831883 RlativeSpeedFrontAxleRightWheel "The speed of the front axle, right wheel relative to the front axle speed, SPN 904.";
CM_ SG_ 2566831883 RelativeSpeedFrontAxleLeftWheel "The speed of the front axle, left wheel relative to the front axle speed, SPN 904.";
CM_ SG_ 2566831883 FrontAxleSpeed "The average speed of the two front wheels.";
CM_ BO_ 2365479471 "Air Suspension Control 1";
CM_ SG_ 2365479471 SspensionCtrlRefusalInformation "Signal which indicates that the air suspension control cannot perform a request due to the operating conditions.";
CM_ SG_ 2365479471 SuspensionRemoteCtrl2 "Signal which indicates that the suspension system is controlled by remote control #2.";
CM_ SG_ 2365479471 SuspensionRemoteCtrl1 "Signal which indicates that the suspension system is controlled by remote control #1.";
CM_ SG_ 2365479471 RearAxleInBumperRange "Signal which indicates that the vehicle height at the rear axle (SPNs 1723 and 1724) is within the bumper range.";
CM_ SG_ 2365479471 FrontAxleInBumperRange "Signal which indicates that the vehicle height at the front axle (SPNs 1721 and 1722) is within the bumper range.";
CM_ SG_ 2365479471 DoorRelease "Signal which indicates that the doors may be opened.";
CM_ SG_ 2365479471 VehicleMotionInhibit "Signal which indicates whether vehicle motion is inhibited.";
CM_ SG_ 2365479471 SecurityDevice "The signal which indicates the status of the security device.";
CM_ SG_ 2365479471 AboveNominalLevelRearAxle "Signal which indicates whether the actual height of the rear axle is above the nominal (desired) level of the rear axle.";
CM_ SG_ 2365479471 AboveNominalLevelFrontAxle "Signal which indicates whether the actual height of the front axle is above the nominal (desired) level of the front axle.";
CM_ SG_ 2365479471 BelowNominalLevelRearAxle "Signal which indicates whether the actual height of the rear axle is below the nominal (desired) level for the rear axle.";
CM_ SG_ 2365479471 BelowNominalLevelFrontAxle "Signal which indicates whether the actual height of the front axle is below the nominal (desired) level for the front axle.";
CM_ SG_ 2365479471 NominalLevelRearAxle "Signal which indicates the nominal (desired) height of the rear axle to be controlled by the suspension system.";
CM_ SG_ 2365479471 NominalLevelFrontAxle "Signal which indicates the nominal (desired) height of the front axle to be controlled by the suspension system.";
CM_ SG_ 2365479471 LiftAxle2Pos "Signal which indicates the position / load condition of lift axle / tag axle #2.";
CM_ SG_ 2365479471 LiftAxle1Pos "Signal which indicates the position / load condition of lift axle / tag axle #1.";
CM_ SG_ 2565812692 Door_Position_Right "Note: This information shall not be used to determine if the door is fully closed or to make other safety decisions!";
CM_ SG_ 2565812692 Door_Position_Left "Note: This information shall not be used to determine if the door is fully closed or to make other safety decisions!";
CM_ SG_ 2565812691 Door_Position_Right "Note: This information shall not be used to determine if the door is fully closed or to make other safety decisions!";
CM_ SG_ 2565812691 Door_Position_Left "Note: This information shall not be used to determine if the door is fully closed or to make other safety decisions!";
CM_ SG_ 2565812690 Door_Position_Right "Note: This information shall not be used to determine if the door is fully closed or to make other safety decisions!";
CM_ SG_ 2565812690 Door_Position_Left "Note: This information shall not be used to determine if the door is fully closed or to make other safety decisions!";
CM_ SG_ 2565812689 Door_Position_Right "Note: This information shall not be used to determine if the door is fully closed or to make other safety decisions!";
CM_ SG_ 2565812689 Door_Position_Left "Note: This information shall not be used to determine if the door is fully closed or to make other safety decisions!";
CM_ BO_ 2566853885 "WiperStatus";
CM_ BO_ 2566845735 "Ambient Conditions";
CM_ SG_ 2566845735 RoadSurfaceTemp "Indicated temperature of road surface over which vehicle is operating.";
CM_ SG_ 2566845735 EngAirInletTemp "Temperature of air entering vehicle air induction system.";
CM_ SG_ 2566845735 AmbientAirTemp "Temperature of air surrounding vehicle.";
CM_ SG_ 2566845735 CabInteriorTemp "Temperature of air inside the part of the vehicle that encloses the driver and vehicle operating controls.";
CM_ SG_ 2566845735 BarometricPress "Absolute air pressure of the atmosphere.";
CM_ BO_ 2566890545 "This message contains the battery information to climatize the battery";
CM_ BO_ 2566893593 "This message contains information about the actual setpoints used within the system";
CM_ BO_ 2566891825 "This message contains the information of the inverter driving the compressor";
CM_ BO_ 2566891569 "This message contains the battery information to climatize the battery";
CM_ BO_ 2566891313 "This message contains information about which setpoints the system should use";
CM_ BO_ 2566894105 "This message contains the non-operation information about the performance of the system";
CM_ BO_ 2566891057 "This message contain overrole information this message has to be send otherwise an error will be reported. if no overrule is required the settings can be either 0 or FF";
CM_ BO_ 2566890801 "This message contains information about the setpoints the system should use";
CM_ SG_ 2566890801 AmbientLimitOverwrite "By sending this signal the interior mode switching will ignore ambient limits for heating. This means the setpoints will need to be high enough for heating";
CM_ SG_ 2566890801 PowerReductionRateBat "This allows the vehicle to reduce the HV power requirement by the unit";
CM_ SG_ 2566890801 AuxHeaterActualTemp " The actual temperature of the auxiliary heater. If not available set to not available";
CM_ SG_ 2566890801 TractionHeatMinimum "The minimum traction heat temperature allowed by the vehicle";
CM_ SG_ 2566890801 PowerReductionRateDriver "This allows the vehicle to reduce the 24V power used for the driver";
CM_ SG_ 2566890801 PowerReductionRateInterior "This allows the vehicle to reduce the 24V power used for the cabin";
CM_ SG_ 2566890801 PowerReductionRateHV "This allows the vehicle to reduce the HV power requirement by the unit";
CM_ SG_ 2566890801 AuxHeatActivation "Allows the system to use the auxilary heater. if off the auxilary heater will never be used";
CM_ SG_ 2566890801 TractionHeatEnable "The vehicle enables the heating system to use traction heating except for deice mode this is automatically done";
CM_ SG_ 2566890801 DriveReady "Same as engine running only in electric vehicles";
CM_ SG_ 2566890801 EngineRunning "The engine running signal (only required in diesel vehicles)";
CM_ SG_ 2566890801 Ignition "Requiered to start the unit (KL15) when this is off the system will not start";
CM_ SG_ 2566890801 MainSwitch "The main switch of the vehicle if it has one";
CM_ BO_ 2566893849 "This message contains the general status information about the system";
CM_ SG_ 2566893849 AuxPumpRequest "For future use not ready yet";
CM_ SG_ 2566893849 HPUnit2On "The heatpump 2 unit is on or not";
CM_ SG_ 2566893849 HPUnit1On "The first heatpump system is running or not";
CM_ SG_ 2566893849 TractionHeatRequest "Requests the use of the traction water system";
CM_ SG_ 2566893849 AuxHeatRequest "Requests the use of the auxilary heater";
CM_ SG_ 2566893849 HVRequest "requests the high voltage from the system";
CM_ BO_ 2566894873 "This message contains information about the actual setpoints used within the system";
CM_ BO_ 2566834941 "Active diagnostic trouble codes";
CM_ SG_ 2566834941 FailureModeIdentifier5 "The FMI defines the type of failure detected in the subsystem identified by an SPN.";
CM_ SG_ 2566834941 FailureModeIdentifier4 "The FMI defines the type of failure detected in the subsystem identified by an SPN.";
CM_ SG_ 2566834941 FailureModeIdentifier3 "The FMI defines the type of failure detected in the subsystem identified by an SPN.";
CM_ SG_ 2566834941 FailureModeIdentifier2 "The FMI defines the type of failure detected in the subsystem identified by an SPN.";
CM_ SG_ 2566834941 OccurenceCount5 "The 7 bit occurence count field contains the number of times a fault has gone from active to previously active.";
CM_ SG_ 2566834941 OccurenceCount4 "The 7 bit occurence count field contains the number of times a fault has gone from active to previously active.";
CM_ SG_ 2566834941 OccurenceCount3 "The 7 bit occurence count field contains the number of times a fault has gone from active to previously active.";
CM_ SG_ 2566834941 OccurenceCount2 "The 7 bit occurence count field contains the number of times a fault has gone from active to previously active.";
CM_ SG_ 2566834941 SPN5High "SPN #5 (Conversion Version 4)";
CM_ SG_ 2566834941 SPN5 "SPN #5 (Conversion Version 4)";
CM_ SG_ 2566834941 SPN4High "SPN #4 (Conversion Version 4)";
CM_ SG_ 2566834941 SPN4 "SPN #4 (Conversion Version 4)";
CM_ SG_ 2566834941 SPN3High "SPN #3 (Conversion Version 4)";
CM_ SG_ 2566834941 SPN3 "SPN #3 (Conversion Version 4)";
CM_ SG_ 2566834941 SPN2High "SPN #2 (Conversion Version 4)";
CM_ SG_ 2566834941 SPN2 "SPN #2 (Conversion Version 4)";
CM_ SG_ 2566834941 SPN1 "SPN #1 (Conversion Version 4)";
CM_ SG_ 2566834941 OccurenceCount1 "The 7 bit occurence count field contains the number of times a fault has gone from active to previously active.";
CM_ SG_ 2566834941 SPN1High "SPN #1 (Conversion Version 4)";
CM_ SG_ 2566834941 FailureModeIdentifier1 "The FMI defines the type of failure detected in the subsystem identified by an SPN.";
CM_ SG_ 2566834941 FlashMalfuncIndicatorLamp "This parameter provides the capability to flash the MIL (SPN 3038).";
CM_ SG_ 2566834941 FlashRedStopLamp "This parameter provides the capability to flash the RSL (SPN 3039).";
CM_ SG_ 2566834941 FlashAmberWarningLamp "This parameter provides the capability to flash the AWL (SPN 3040). ";
CM_ SG_ 2566834941 FlashProtectLamp "This parameter provides the capability to flash the engine protect lamp (SPN 3041).";
CM_ SG_ 2566834941 MalfunctionIndicatorLampStatus "A lamp used to relay only emissions-related trouble code information.";
CM_ SG_ 2566834941 RedStopLampState "This lamp is uesed to relay trouble code information that is of a severe enought condition that it warrants stopping the vehicle.";
CM_ SG_ 2566834941 AmberWarningLampStatus "This lamp is used to relay trouble code information that is reporting a problem with the vehicle system but the vehicle need
not be immediately stopped.";
CM_ SG_ 2566834941 ProtectLampStatus "This lamp is used to relay trouble code informatio that is reporting a problem with a vehicle system that is most
probably not electronic subsystem related.";
CM_ BO_ 2566834713 "Active diagnostic trouble codes";
CM_ SG_ 2566834713 FailureModeIdentifier5 "The FMI defines the type of failure detected in the subsystem identified by an SPN.";
CM_ SG_ 2566834713 FailureModeIdentifier4 "The FMI defines the type of failure detected in the subsystem identified by an SPN.";
CM_ SG_ 2566834713 FailureModeIdentifier3 "The FMI defines the type of failure detected in the subsystem identified by an SPN.";
CM_ SG_ 2566834713 FailureModeIdentifier2 "The FMI defines the type of failure detected in the subsystem identified by an SPN.";
CM_ SG_ 2566834713 OccurenceCount5 "The 7 bit occurence count field contains the number of times a fault has gone from active to previously active.";
CM_ SG_ 2566834713 OccurenceCount4 "The 7 bit occurence count field contains the number of times a fault has gone from active to previously active.";
CM_ SG_ 2566834713 OccurenceCount3 "The 7 bit occurence count field contains the number of times a fault has gone from active to previously active.";
CM_ SG_ 2566834713 OccurenceCount2 "The 7 bit occurence count field contains the number of times a fault has gone from active to previously active.";
CM_ SG_ 2566834713 SPN5High "SPN #5 (Conversion Version 4)";
CM_ SG_ 2566834713 SPN5 "SPN #5 (Conversion Version 4)";
CM_ SG_ 2566834713 SPN4High "SPN #4 (Conversion Version 4)";
CM_ SG_ 2566834713 SPN4 "SPN #4 (Conversion Version 4)";
CM_ SG_ 2566834713 SPN3High "SPN #3 (Conversion Version 4)";
CM_ SG_ 2566834713 SPN3 "SPN #3 (Conversion Version 4)";
CM_ SG_ 2566834713 SPN2High "SPN #2 (Conversion Version 4)";
CM_ SG_ 2566834713 SPN2 "SPN #2 (Conversion Version 4)";
CM_ SG_ 2566834713 SPN1 "SPN #1 (Conversion Version 4)";
CM_ SG_ 2566834713 OccurenceCount1 "The 7 bit occurence count field contains the number of times a fault has gone from active to previously active.";
CM_ SG_ 2566834713 SPN1High "SPN #1 (Conversion Version 4)";
CM_ SG_ 2566834713 FailureModeIdentifier1 "The FMI defines the type of failure detected in the subsystem identified by an SPN.";
CM_ SG_ 2566834713 FlashMalfuncIndicatorLamp "This parameter provides the capability to flash the MIL (SPN 3038).";
CM_ SG_ 2566834713 FlashRedStopLamp "This parameter provides the capability to flash the RSL (SPN 3039).";
CM_ SG_ 2566834713 FlashAmberWarningLamp "This parameter provides the capability to flash the AWL (SPN 3040). ";
CM_ SG_ 2566834713 FlashProtectLamp "This parameter provides the capability to flash the engine protect lamp (SPN 3041).";
CM_ SG_ 2566834713 MalfunctionIndicatorLampStatus "A lamp used to relay only emissions-related trouble code information.";
CM_ SG_ 2566834713 RedStopLampState "This lamp is uesed to relay trouble code information that is of a severe enought condition that it warrants stopping the vehicle.";
CM_ SG_ 2566834713 AmberWarningLampStatus "This lamp is used to relay trouble code information that is reporting a problem with the vehicle system but the vehicle need
not be immediately stopped.";
CM_ SG_ 2566834713 ProtectLampStatus "This lamp is used to relay trouble code informatio that is reporting a problem with a vehicle system that is most
probably not electronic subsystem related.";
CM_ BO_ 2566769969 "Operator Wiper and Washer Controls Message";
CM_ SG_ 2566769969 RearWasherFunction "State of operation selected by operator switch for the rear washer.";
CM_ SG_ 2566769969 FrontOperatorWasherSwitch "State of operation selected by operator switch for the washer in front of the operator position.";
CM_ SG_ 2566769969 FrontNonoperatorWasherSwitch "State of operation selected by operator switch for the front washer not in front of the operator position.";
CM_ SG_ 2566769969 RearWiperDelayCtrl "Time between cycles of the rear wiper (i.";
CM_ SG_ 2566769969 FrontNonoperatorWiperDelayCtrl "Time between cycles of the front non-operator side wiper (i.";
CM_ SG_ 2566769969 FrontOperatorWiperDelayCtrl "Time between cycles of the front operator side wiper (i.";
CM_ SG_ 2566769969 RearWiperSwitch "State of operation selected by operator switch for the rear wiper.";
CM_ SG_ 2566769969 FrontOperatorWiperSwitch "State of operation selected by operator switch for the Wiper in front of the operator position.";
CM_ SG_ 2566769969 FrontNonoperatorWiperSwitch "State of operation selected by operator switch for the front wiper not in front of the operator position.";
CM_ BO_ 2365443121 "Operators External Light Controls Message";
CM_ SG_ 2365443121 OprtrsDesiredDelayedLampOffTime "A 16 bit parameter to be associated with Delayed Off position (1000 binary) of the Main Light Switch.";
CM_ SG_ 2365443121 OperatorsDesiredBacklight "A 8 bit parameter to indicate the level of back lighting the operator has selected for displays.";
CM_ SG_ 2365443121 HighLowBeamSwitch "A 2 bit parameter to indicate the selected position of the operator's high/low beam select switch.";
CM_ SG_ 2365443121 HazardLightSwitch "A 2 bit parameter to indicate the selected position of the operator's hazard light switch.";
CM_ SG_ 2365443121 TurnSignalSwitch "A 4 bit parameter to indicate the selected position of the operator's turn signal switch.";
CM_ SG_ 2365443121 MainLightSwitch "A 4 bit parameter to indicate the selected position of the operator's main light switch.";
CM_ SG_ 2365443121 WorkLightSwitch "A 4 bit parameter to indicate the selected position of the operator's work light switch.";
CM_ BO_ 2566853399 "Time/Date";
CM_ SG_ 2566853399 Year "Part of a parameter used to represent a calendar date.";
CM_ SG_ 2566853399 Day "Part of a parameter used to represent a calendar date.";
CM_ SG_ 2566853399 Month "Part of a parameter used to represent a calendar date.";
CM_ SG_ 2566853399 Hours "Part of a parameter used to represent time.";
CM_ SG_ 2566853399 Minutes "Part of a parameter used to represent time.";
CM_ SG_ 2566806504 LnDprtureIndicationEnableStatus "Indicates whether lane departure indication is active.";
CM_ SG_ 2566806504 LaneTrackingStatusLeftSide "Indicates whether the left side is tracking lane.";
CM_ SG_ 2566806504 LaneTrackingStatusRightSide "Indicates whether right side is tracking lane.";
CM_ BO_ 2431649768 "Forward Lane Image urgent msg";
CM_ SG_ 2431649768 LaneDepartureImminentLeftSide "Indicates departure imminent on left side of lane.";
CM_ SG_ 2431649768 LaneDepartureImminentRightSide "Indicates departure imminent on right side of lane.";
CM_ SG_ 2565867787 SteerWheelAngle "The main operator`s steering wheel angle (on the steering column, not the actual wheel angle).";
CM_ SG_ 2349399885 AUX_IO_Channel6 "Right SWS scroll Wheel";
CM_ SG_ 2566896268 Auxiliary_IO_65 "Horn Switch";
CM_ SG_ 2566896268 Auxiliary_IO_64 "Wiper Sensitivity +2";
CM_ SG_ 2566896268 Auxiliary_IO_63 "Wiper Sensitivity +1";
CM_ SG_ 2566896268 Auxiliary_IO_62 "Wiper Sensitivity - 1";
CM_ SG_ 2566896268 Auxiliary_IO_61 "Wiper Sensitivity - 2";
CM_ SG_ 2566896268 Auxiliary_IO_60 "Washer Switch";
CM_ SG_ 2566896268 Auxiliary_IO_59 "Main Beam Switch - Continuous";
CM_ SG_ 2566896268 Auxiliary_IO_58 "Main Beam Switch - Signalling";
CM_ SG_ 2566896268 Auxiliary_IO_56 "Direction Indicator Switch - Right";
CM_ SG_ 2566896268 Auxiliary_IO_54 "Direction Indicator Switch - Left";
CM_ SG_ 2566896268 Auxiliary_IO_53 "Wiper Switch Position - Mode Down 2";
CM_ SG_ 2566896268 Auxiliary_IO_52 "Wiper Switch Position - Mode Down 1";
CM_ SG_ 2566896268 Auxiliary_IO_51 "Wiper Switch Position - Rest Position";
CM_ SG_ 2566896268 Auxiliary_IO_50 "Wiper Switch Position - Mode Up 1";
CM_ SG_ 2566896268 Auxiliary_IO_49 "Wiper Switch Position - Mode Up 2";
CM_ SG_ 2566873740 Auxiliary_IO_32 "Primary Retarder Position 3 (Fixed Pos)";
CM_ SG_ 2566873740 Auxiliary_IO_31 "ECO On/Off";
CM_ SG_ 2566873740 Auxiliary_IO_30 "Automatic/Manual Mode - Zero Position";
CM_ SG_ 2566873740 Auxiliary_IO_29 "Automatic/Manual Mode - Mode change";
CM_ SG_ 2566873740 Auxiliary_IO_28 "Primary Retarder Off (Spring Return)";
CM_ SG_ 2566873740 Auxiliary_IO_27 "Primary Retarder On (Spring Return)";
CM_ SG_ 2566873740 Auxiliary_IO_26 "Primary Retarder Position 1 (Fixed Pos)";
CM_ SG_ 2566873740 Auxiliary_IO_25 "Primary Retarder Position 2 (Fixed Pos)";
CM_ SG_ 2566873740 Auxiliary_IO_24 "Gear Selector - Reverse Step 2";
CM_ SG_ 2566873740 Auxiliary_IO_23 "Shift Request - Upshift";
CM_ SG_ 2566873740 Auxiliary_IO_22 "Shift Request - Zero Position";
CM_ SG_ 2566873740 Auxiliary_IO_21 "Shift Request - Downshift";
CM_ SG_ 2566873740 Auxiliary_IO_20 "Gear Selector - Drive Step 2";
CM_ SG_ 2566873740 Auxiliary_IO_19 "Gear Selector - Drive Step 1";
CM_ SG_ 2566873740 Auxiliary_IO_18 "Gear Selector - Rest Position";
CM_ SG_ 2566873740 Auxiliary_IO_17 "Gear Selector - Reverse Step 1";
CM_ SG_ 2561015629 Auxiliary_IO_96 "Voice Control Switch";
CM_ SG_ 2561015629 Auxiliary_IO_93 "Volume Mute Switch";
CM_ SG_ 2561015629 Auxiliary_IO_99 "Volume Down Switch";
CM_ SG_ 2561015629 Auxiliary_IO_100 "Volume Up Switch";
CM_ SG_ 2561015629 Auxiliary_IO_95 "Menu Control Press Switch";
CM_ SG_ 2561015629 Auxiliary_IO_94 "Menu Control Back Switch";
CM_ SG_ 2561015629 Auxiliary_IO_92 "Left SWS Toggle Press Switch";
CM_ SG_ 2561015629 Auxiliary_IO_91 "Infotainment Next Switch";
CM_ SG_ 2561015629 Auxiliary_IO_90 "Infotainment Previous Switch";
CM_ SG_ 2561015629 Auxiliary_IO_89 "Infotainment Source Switch";
CM_ SG_ 2561015629 Auxiliary_IO_88 "Left SWS Toggle Down Switch";
CM_ SG_ 2561015629 Auxiliary_IO_87 "Left SWS Toggle Up Switch";
CM_ SG_ 2561015629 Auxiliary_IO_86 "Cruise Control Resume Switch";
CM_ SG_ 2561015629 Auxiliary_IO_85 "Cruise Control Set Switch";
CM_ SG_ 2561015629 Auxiliary_IO_81 "Speed Limiter Plus Switch";
CM_ SG_ 2561015629 Auxiliary_IO_82 "Speed Limiter minus switch";
CM_ SG_ 2561015629 Auxiliary_IO_84 "Functions OFF Switch";
CM_ BO_ 2566834828 "Active diagnostic trouble codes";
CM_ SG_ 2566834828 FailureModeIdentifier5 "The FMI defines the type of failure detected in the subsystem identified by an SPN.";
CM_ SG_ 2566834828 FailureModeIdentifier4 "The FMI defines the type of failure detected in the subsystem identified by an SPN.";
CM_ SG_ 2566834828 FailureModeIdentifier3 "The FMI defines the type of failure detected in the subsystem identified by an SPN.";
CM_ SG_ 2566834828 FailureModeIdentifier2 "The FMI defines the type of failure detected in the subsystem identified by an SPN.";
CM_ SG_ 2566834828 OccurenceCount5 "The 7 bit occurence count field contains the number of times a fault has gone from active to previously active.";
CM_ SG_ 2566834828 OccurenceCount4 "The 7 bit occurence count field contains the number of times a fault has gone from active to previously active.";
CM_ SG_ 2566834828 OccurenceCount3 "The 7 bit occurence count field contains the number of times a fault has gone from active to previously active.";
CM_ SG_ 2566834828 OccurenceCount2 "The 7 bit occurence count field contains the number of times a fault has gone from active to previously active.";
CM_ SG_ 2566834828 SPN5High "SPN #5 (Conversion Version 4)";
CM_ SG_ 2566834828 SPN5 "SPN #5 (Conversion Version 4)";
CM_ SG_ 2566834828 SPN4High "SPN #4 (Conversion Version 4)";
CM_ SG_ 2566834828 SPN4 "SPN #4 (Conversion Version 4)";
CM_ SG_ 2566834828 SPN3High "SPN #3 (Conversion Version 4)";
CM_ SG_ 2566834828 SPN3 "SPN #3 (Conversion Version 4)";
CM_ SG_ 2566834828 SPN2High "SPN #2 (Conversion Version 4)";
CM_ SG_ 2566834828 SPN2 "SPN #2 (Conversion Version 4)";
CM_ SG_ 2566834828 SPN1 "SPN #1 (Conversion Version 4)";
CM_ SG_ 2566834828 OccurenceCount1 "The 7 bit occurence count field contains the number of times a fault has gone from active to previously active.";
CM_ SG_ 2566834828 SPN1High "SPN #1 (Conversion Version 4)";
CM_ SG_ 2566834828 FailureModeIdentifier1 "The FMI defines the type of failure detected in the subsystem identified by an SPN.";
CM_ SG_ 2566834828 FlashMalfuncIndicatorLamp "This parameter provides the capability to flash the MIL (SPN 3038).";
CM_ SG_ 2566834828 FlashRedStopLamp "This parameter provides the capability to flash the RSL (SPN 3039).";
CM_ SG_ 2566834828 FlashAmberWarningLamp "This parameter provides the capability to flash the AWL (SPN 3040). ";
CM_ SG_ 2566834828 FlashProtectLamp "This parameter provides the capability to flash the engine protect lamp (SPN 3041).";
CM_ SG_ 2566834828 MalfunctionIndicatorLampStatus "A lamp used to relay only emissions-related trouble code information.";
CM_ SG_ 2566834828 RedStopLampState "This lamp is uesed to relay trouble code information that is of a severe enought condition that it warrants stopping the vehicle.";
CM_ SG_ 2566834828 AmberWarningLampStatus "This lamp is used to relay trouble code information that is reporting a problem with the vehicle system but the vehicle need
not be immediately stopped.";
CM_ SG_ 2566834828 ProtectLampStatus "This lamp is used to relay trouble code informatio that is reporting a problem with a vehicle system that is most
probably not electronic subsystem related.";
CM_ BO_ 2566834698 "Active diagnostic trouble codes";
CM_ SG_ 2566834698 FailureModeIdentifier5 "The FMI defines the type of failure detected in the subsystem identified by an SPN.";
CM_ SG_ 2566834698 FailureModeIdentifier4 "The FMI defines the type of failure detected in the subsystem identified by an SPN.";
CM_ SG_ 2566834698 FailureModeIdentifier3 "The FMI defines the type of failure detected in the subsystem identified by an SPN.";
CM_ SG_ 2566834698 FailureModeIdentifier2 "The FMI defines the type of failure detected in the subsystem identified by an SPN.";
CM_ SG_ 2566834698 OccurenceCount5 "The 7 bit occurence count field contains the number of times a fault has gone from active to previously active.";
CM_ SG_ 2566834698 OccurenceCount4 "The 7 bit occurence count field contains the number of times a fault has gone from active to previously active.";
CM_ SG_ 2566834698 OccurenceCount3 "The 7 bit occurence count field contains the number of times a fault has gone from active to previously active.";
CM_ SG_ 2566834698 OccurenceCount2 "The 7 bit occurence count field contains the number of times a fault has gone from active to previously active.";
CM_ SG_ 2566834698 SPN5High "SPN #5 (Conversion Version 4)";
CM_ SG_ 2566834698 SPN5 "SPN #5 (Conversion Version 4)";
CM_ SG_ 2566834698 SPN4High "SPN #4 (Conversion Version 4)";
CM_ SG_ 2566834698 SPN4 "SPN #4 (Conversion Version 4)";
CM_ SG_ 2566834698 SPN3High "SPN #3 (Conversion Version 4)";
CM_ SG_ 2566834698 SPN3 "SPN #3 (Conversion Version 4)";
CM_ SG_ 2566834698 SPN2High "SPN #2 (Conversion Version 4)";
CM_ SG_ 2566834698 SPN2 "SPN #2 (Conversion Version 4)";
CM_ SG_ 2566834698 SPN1 "SPN #1 (Conversion Version 4)";
CM_ SG_ 2566834698 OccurenceCount1 "The 7 bit occurence count field contains the number of times a fault has gone from active to previously active.";
CM_ SG_ 2566834698 SPN1High "SPN #1 (Conversion Version 4)";
CM_ SG_ 2566834698 FailureModeIdentifier1 "The FMI defines the type of failure detected in the subsystem identified by an SPN.";
CM_ SG_ 2566834698 FlashMalfuncIndicatorLamp "This parameter provides the capability to flash the MIL (SPN 3038).";
CM_ SG_ 2566834698 FlashRedStopLamp "This parameter provides the capability to flash the RSL (SPN 3039).";
CM_ SG_ 2566834698 FlashAmberWarningLamp "This parameter provides the capability to flash the AWL (SPN 3040). ";
CM_ SG_ 2566834698 FlashProtectLamp "This parameter provides the capability to flash the engine protect lamp (SPN 3041).";
CM_ SG_ 2566834698 MalfunctionIndicatorLampStatus "A lamp used to relay only emissions-related trouble code information.";
CM_ SG_ 2566834698 RedStopLampState "This lamp is uesed to relay trouble code information that is of a severe enought condition that it warrants stopping the vehicle.";
CM_ SG_ 2566834698 AmberWarningLampStatus "This lamp is used to relay trouble code information that is reporting a problem with the vehicle system but the vehicle need
not be immediately stopped.";
CM_ SG_ 2566834698 ProtectLampStatus "This lamp is used to relay trouble code informatio that is reporting a problem with a vehicle system that is most
probably not electronic subsystem related.";
CM_ BO_ 2566840303 "Electronic Engine Controller 3";
BA_DEF_ BO_  "SingleFrame" INT 0 1;
BA_DEF_ SG_  "SigType" ENUM  "Default","Range","RangeSigned","ASCII","Discrete","Control","ReferencePGN","DTC","StringDelimiter","StringLength","StringLengthControl","MessageCounter","MessageChecksum";
BA_DEF_ SG_  "GenSigEVName" STRING ;
BA_DEF_ SG_  "GenSigILSupport" ENUM  "No","Yes";
BA_DEF_ SG_  "GenSigSendType" ENUM  "Cyclic","OnWrite","OnWriteWithRepetition","OnChange","OnChangeWithRepetition","IfActive","IfActiveWithRepetition","NoSigSendType";
BA_DEF_ SG_  "GenSigStartValue" INT 0 10000;
BA_DEF_ BO_  "GenMsgILSupport" ENUM  "No","Yes";
BA_DEF_ BO_  "GenMsgSendType" ENUM  "cyclic","NotUsed","IfActive","NotUsed","NotUsed","NotUsed","NotUsed","NotUsed","noMsgSendType";
BA_DEF_ BO_  "GenMsgRequestable" INT 0 1;
BA_DEF_ BO_  "GenMsgCycleTime" INT 0 3600000;
BA_DEF_ SG_  "SPN" INT 0 524287;
BA_DEF_ BO_  "VFrameFormat" ENUM  "StandardCAN","ExtendedCAN","reserved","J1939PG";
BA_DEF_DEF_  "SingleFrame" 1;
BA_DEF_DEF_  "SigType" "Default";
BA_DEF_DEF_  "GenSigEVName" "Env@Nodename_@Signame";
BA_DEF_DEF_  "GenSigILSupport" "Yes";
BA_DEF_DEF_  "GenSigSendType" "NoSigSendType";
BA_DEF_DEF_  "GenSigStartValue" 0;
BA_DEF_DEF_  "GenMsgILSupport" "Yes";
BA_DEF_DEF_  "GenMsgSendType" "noMsgSendType";
BA_DEF_DEF_  "GenMsgRequestable" 1;
BA_DEF_DEF_  "GenMsgCycleTime" 0;
BA_DEF_DEF_  "SPN" 0;
BA_DEF_DEF_  "VFrameFormat" "J1939PG";
BA_ "GenMsgSendType" BO_ 2566845491 0;
BA_ "GenMsgCycleTime" BO_ 2566845491 10000;
BA_ "GenMsgCycleTime" BO_ 2432593706 100;
BA_ "GenMsgSendType" BO_ 2432593706 0;
BA_ "GenMsgCycleTime" BO_ 2364551072 50;
BA_ "GenMsgSendType" BO_ 2364551072 0;
BA_ "GenMsgCycleTime" BO_ 2566852168 100;
BA_ "GenMsgSendType" BO_ 2566852168 0;
BA_ "GenMsgSendType" BO_ 2566767627 0;
BA_ "GenMsgCycleTime" BO_ 2566767627 100;
BA_ "GenMsgCycleTime" BO_ 2565865739 100;
BA_ "GenMsgSendType" BO_ 2565865739 0;
BA_ "GenMsgCycleTime" BO_ 2633935883 100;
BA_ "GenMsgSendType" BO_ 2633935883 0;
BA_ "GenMsgSendType" BO_ 2566831883 0;
BA_ "GenMsgCycleTime" BO_ 2566831883 100;
BA_ "GenMsgSendType" BO_ 2365479471 0;
BA_ "GenMsgCycleTime" BO_ 2365479471 100;
BA_ "GenMsgCycleTime" BO_ 2365525031 100;
BA_ "GenMsgSendType" BO_ 2365525031 0;
BA_ "GenMsgCycleTime" BO_ 2565866801 100;
BA_ "GenMsgSendType" BO_ 2565866801 0;
BA_ "GenMsgSendType" BO_ 2565812692 0;
BA_ "GenMsgCycleTime" BO_ 2565812692 1000;
BA_ "GenMsgSendType" BO_ 2565812691 0;
BA_ "GenMsgCycleTime" BO_ 2565812691 1000;
BA_ "GenMsgSendType" BO_ 2565812690 0;
BA_ "GenMsgCycleTime" BO_ 2565812690 1000;
BA_ "GenMsgSendType" BO_ 2565812689 0;
BA_ "GenMsgCycleTime" BO_ 2565812689 1000;
BA_ "GenMsgSendType" BO_ 2565854257 0;
BA_ "GenMsgCycleTime" BO_ 2565854257 100;
BA_ "GenMsgSendType" BO_ 2565854001 0;
BA_ "GenMsgCycleTime" BO_ 2565854001 100;
BA_ "GenMsgSendType" BO_ 2565853745 0;
BA_ "GenMsgCycleTime" BO_ 2565853745 100;
BA_ "GenMsgSendType" BO_ 2565853489 0;
BA_ "GenMsgCycleTime" BO_ 2565853489 100;
BA_ "GenMsgSendType" BO_ 2566853885 0;
BA_ "GenMsgCycleTime" BO_ 2566853885 50;
BA_ "GenMsgSendType" BO_ 2566850855 0;
BA_ "GenMsgCycleTime" BO_ 2566850855 250;
BA_ "GenMsgCycleTime" BO_ 2566851367 100;
BA_ "GenMsgSendType" BO_ 2566851367 0;
BA_ "GenMsgSendType" BO_ 2566889521 0;
BA_ "GenMsgCycleTime" BO_ 2566889521 100;
BA_ "GenMsgSendType" BO_ 2566845735 0;
BA_ "GenMsgCycleTime" BO_ 2566845735 1000;
BA_ "GenMsgCycleTime" BO_ 2566893337 250;
BA_ "GenMsgSendType" BO_ 2566893337 0;
BA_ "GenMsgCycleTime" BO_ 2566892081 250;
BA_ "GenMsgSendType" BO_ 2566892081 0;
BA_ "GenMsgCycleTime" BO_ 2566895897 250;
BA_ "GenMsgSendType" BO_ 2566895897 0;
BA_ "GenMsgCycleTime" BO_ 2566890545 250;
BA_ "GenMsgSendType" BO_ 2566890545 0;
BA_ "GenMsgCycleTime" BO_ 2566893593 250;
BA_ "GenMsgSendType" BO_ 2566893593 0;
BA_ "GenMsgCycleTime" BO_ 2566891825 250;
BA_ "GenMsgSendType" BO_ 2566891825 0;
BA_ "GenMsgCycleTime" BO_ 2566891569 250;
BA_ "GenMsgSendType" BO_ 2566891569 0;
BA_ "GenMsgCycleTime" BO_ 2566891313 250;
BA_ "GenMsgSendType" BO_ 2566891313 0;
BA_ "GenMsgCycleTime" BO_ 2566894105 250;
BA_ "GenMsgSendType" BO_ 2566894105 0;
BA_ "GenMsgCycleTime" BO_ 2566891057 250;
BA_ "GenMsgSendType" BO_ 2566891057 0;
BA_ "GenMsgCycleTime" BO_ 2566890801 250;
BA_ "GenMsgSendType" BO_ 2566890801 0;
BA_ "GenMsgCycleTime" BO_ 2566893849 250;
BA_ "GenMsgSendType" BO_ 2566893849 0;
BA_ "GenMsgCycleTime" BO_ 2566894873 250;
BA_ "GenMsgSendType" BO_ 2566894873 0;
BA_ "GenMsgSendType" BO_ 2365531141 0;
BA_ "GenMsgCycleTime" BO_ 2365531141 100;
BA_ "GenMsgSendType" BO_ 2566769969 0;
BA_ "GenMsgCycleTime" BO_ 2566769969 100;
BA_ "GenMsgSendType" BO_ 2561271857 0;
BA_ "GenMsgCycleTime" BO_ 2561271857 100;
BA_ "GenMsgCycleTime" BO_ 2566873137 100;
BA_ "GenMsgSendType" BO_ 2566873137 0;
BA_ "GenMsgCycleTime" BO_ 2563804199 100;
BA_ "GenMsgSendType" BO_ 2563804199 0;
BA_ "GenMsgCycleTime" BO_ 2563788071 100;
BA_ "GenMsgSendType" BO_ 2563788071 0;
BA_ "GenMsgSendType" BO_ 2563783217 0;
BA_ "GenMsgCycleTime" BO_ 2563783217 100;
BA_ "GenMsgCycleTime" BO_ 2563833598 100;
BA_ "GenMsgSendType" BO_ 2563833598 0;
BA_ "GenMsgSendType" BO_ 2365443121 0;
BA_ "GenMsgCycleTime" BO_ 2365443121 10;
BA_ "GenMsgCycleTime" BO_ 2566853399 1000;
BA_ "GenMsgSendType" BO_ 2566853399 0;
BA_ "GenMsgCycleTime" BO_ 2566848561 20;
BA_ "GenMsgSendType" BO_ 2566848561 0;
BA_ "GenMsgCycleTime" BO_ 2566848817 20;
BA_ "GenMsgSendType" BO_ 2566848817 0;
BA_ "GenMsgSendType" BO_ 2566806504 0;
BA_ "GenMsgCycleTime" BO_ 2566806504 500;
BA_ "GenMsgSendType" BO_ 2431649768 0;
BA_ "GenMsgCycleTime" BO_ 2431649768 250;
BA_ "GenMsgCycleTime" BO_ 2566894650 20;
BA_ "GenMsgSendType" BO_ 2566894650 0;
BA_ "GenMsgCycleTime" BO_ 2565867787 10;
BA_ "GenMsgSendType" BO_ 2565867787 0;
BA_ "GenMsgCycleTime" BO_ 2349399885 100;
BA_ "GenMsgSendType" BO_ 2349399885 0;
BA_ "GenMsgCycleTime" BO_ 2566896268 100;
BA_ "GenMsgSendType" BO_ 2566896268 0;
BA_ "GenMsgCycleTime" BO_ 2566873740 100;
BA_ "GenMsgSendType" BO_ 2566873740 0;
BA_ "GenMsgCycleTime" BO_ 2561015629 100;
BA_ "GenMsgSendType" BO_ 2561015629 0;
BA_ "GenMsgSendType" BO_ 2565799719 0;
BA_ "GenMsgCycleTime" BO_ 2565799719 100;
BA_ "GenMsgSendType" BO_ 2566678856 0;
BA_ "GenMsgSendType" BO_ 2566853937 0;
BA_ "GenMsgCycleTime" BO_ 2566853937 100;
BA_ "GenMsgCycleTime" BO_ 2566840303 250;
BA_ "GenMsgSendType" BO_ 2566840303 0;
BA_ "SPN" SG_ 2566845491 TirePressThresholdDetection 2587;
BA_ "SPN" SG_ 2566845491 TireAirLeakageRate 2586;
BA_ "SPN" SG_ 2566845491 CTIWheelEndElectricalFault 1697;
BA_ "SPN" SG_ 2566845491 CTITireStatus 1698;
BA_ "SPN" SG_ 2566845491 CTIWheelSensorStatus 1699;
BA_ "SPN" SG_ 2566845491 TireTemp 242;
BA_ "SPN" SG_ 2566845491 TirePress 241;
BA_ "SPN" SG_ 2566845491 TireLocation 929;
BA_ "SPN" SG_ 2432593706 ACCDistanceAlertSignal 1796;
BA_ "SPN" SG_ 2432593706 ACCSystemShutoffWarning 1797;
BA_ "SPN" SG_ 2432593706 ACCTargetDetected 1798;
BA_ "SPN" SG_ 2432593706 RoadCurvature 1591;
BA_ "SPN" SG_ 2432593706 AdptveCruiseCtrlSetDistanceMode 1589;
BA_ "SPN" SG_ 2432593706 AdaptiveCruiseCtrlMode 1590;
BA_ "SPN" SG_ 2432593706 AdaptiveCruiseCtrlSetSpeed 1588;
BA_ "SPN" SG_ 2432593706 DistanceToForwardVehicle 1587;
BA_ "SPN" SG_ 2432593706 SpeedOfForwardVehicle 1586;
BA_ "GenSigStartValue" SG_ 2566852168 HVHeaterTemperature 50;
BA_ "SPN" SG_ 2566767627 BrakeTempWarning 3839;
BA_ "SPN" SG_ 2566767627 XBRAccelerationLimit 2921;
BA_ "SPN" SG_ 2566767627 XBRActiveCtrlMode 2918;
BA_ "SPN" SG_ 2566767627 XBRSystemState 2917;
BA_ "SPN" SG_ 2566767627 FoundationBrakeUse 2919;
BA_ "SPN" SG_ 2566767627 HillHolderMode 2912;
BA_ "SPN" SG_ 2566767627 HaltBrakeMode 2913;
BA_ "SPN" SG_ 2565865739 SrcAddrssOfCtrllngDvcFrBrkCntrl 1481;
BA_ "SPN" SG_ 2565865739 BrakePedalPos 521;
BA_ "SPN" SG_ 2565865739 TrctrMntdTrilerABSWarningSignal 1792;
BA_ "SPN" SG_ 2565865739 TrailerABSStatus 1836;
BA_ "SPN" SG_ 2565865739 HaltBrakeSwitch 2911;
BA_ "SPN" SG_ 2565865739 ATC_ASRInformationSignal 1793;
BA_ "SPN" SG_ 2565865739 ABS_EBSAmberWarningSignal 1438;
BA_ "SPN" SG_ 2565865739 EBSRedWarningSignal 1439;
BA_ "SPN" SG_ 2565865739 ABSFullyOperational 1243;
BA_ "SPN" SG_ 2565865739 EngRetarderSelection 973;
BA_ "SPN" SG_ 2565865739 RemoteAccelEnableSwitch 969;
BA_ "SPN" SG_ 2565865739 EngAuxEngShutdownSwitch 970;
BA_ "SPN" SG_ 2565865739 EngDerateSwitch 971;
BA_ "SPN" SG_ 2565865739 AccelInterlockSwitch 972;
BA_ "SPN" SG_ 2565865739 TractionCtrlOverrideSwitch 1238;
BA_ "SPN" SG_ 2565865739 ASRHillHolderSwitch 577;
BA_ "SPN" SG_ 2565865739 ASROffroadSwitch 576;
BA_ "SPN" SG_ 2565865739 ABSOffroadSwitch 575;
BA_ "SPN" SG_ 2565865739 EBSBrakeSwitch 1121;
BA_ "SPN" SG_ 2565865739 AntiLockBrakingActive 563;
BA_ "SPN" SG_ 2565865739 ASRBrakeCtrlActive 562;
BA_ "SPN" SG_ 2565865739 ASREngCtrlActive 561;
BA_ "SPN" SG_ 2633935883 BrkLnngRmnngRearAxle3RightWheel 1106;
BA_ "SPN" SG_ 2633935883 BrkLnngRmningRearAxle3LeftWheel 1105;
BA_ "SPN" SG_ 2633935883 BrkLnngRmnngRearAxle2RightWheel 1104;
BA_ "SPN" SG_ 2633935883 BrkLnngRmningRearAxle2LeftWheel 1103;
BA_ "SPN" SG_ 2633935883 BrkLnngRmnngRearAxle1RightWheel 1102;
BA_ "SPN" SG_ 2633935883 BrkLnngRmningRearAxle1LeftWheel 1101;
BA_ "SPN" SG_ 2633935883 BrkLnngRmnngFrontAxleRightWheel 1100;
BA_ "SPN" SG_ 2633935883 BrkLnngRmningFrontAxleLeftWheel 1099;
BA_ "SPN" SG_ 2566831883 RlativeSpeedRearAxle2RightWheel 910;
BA_ "SPN" SG_ 2566831883 RelativeSpeedRearAxle2LeftWheel 909;
BA_ "SPN" SG_ 2566831883 RlativeSpeedRearAxle1RightWheel 908;
BA_ "SPN" SG_ 2566831883 RelativeSpeedRearAxle1LeftWheel 907;
BA_ "SPN" SG_ 2566831883 RlativeSpeedFrontAxleRightWheel 906;
BA_ "SPN" SG_ 2566831883 RelativeSpeedFrontAxleLeftWheel 905;
BA_ "SPN" SG_ 2566831883 FrontAxleSpeed 904;
BA_ "SPN" SG_ 2365479471 SspensionCtrlRefusalInformation 1827;
BA_ "SPN" SG_ 2365479471 SuspensionRemoteCtrl2 1825;
BA_ "SPN" SG_ 2365479471 SuspensionRemoteCtrl1 1826;
BA_ "SPN" SG_ 2365479471 RearAxleInBumperRange 1823;
BA_ "SPN" SG_ 2365479471 FrontAxleInBumperRange 1824;
BA_ "SPN" SG_ 2365479471 DoorRelease 1744;
BA_ "SPN" SG_ 2365479471 VehicleMotionInhibit 1745;
BA_ "SPN" SG_ 2365479471 SecurityDevice 1746;
BA_ "SPN" SG_ 2365479471 LevelCtrlMode 1741;
BA_ "SPN" SG_ 2365479471 KneelingInformation 1742;
BA_ "SPN" SG_ 2365479471 LiftingCtrlModeRearAxle 1756;
BA_ "SPN" SG_ 2365479471 LiftingCtrlModeFrontAxle 1739;
BA_ "SPN" SG_ 2365479471 LoweringCtrlModeRearAxle 1755;
BA_ "SPN" SG_ 2365479471 LoweringCtrlModeFrontAxle 1740;
BA_ "SPN" SG_ 2365479471 AboveNominalLevelRearAxle 1736;
BA_ "SPN" SG_ 2365479471 AboveNominalLevelFrontAxle 1737;
BA_ "SPN" SG_ 2365479471 BelowNominalLevelRearAxle 1754;
BA_ "SPN" SG_ 2365479471 BelowNominalLevelFrontAxle 1738;
BA_ "SPN" SG_ 2365479471 NominalLevelRearAxle 1733;
BA_ "SPN" SG_ 2365479471 NominalLevelFrontAxle 1734;
BA_ "SPN" SG_ 2365479471 LiftAxle2Pos 1822;
BA_ "SPN" SG_ 2365479471 LiftAxle1Pos 1743;
BA_ "SPN" SG_ 2565866801 TransCurrentGear 523;
BA_ "SPN" SG_ 2566853885 Motor2sensorstatus 2551;
BA_ "SPN" SG_ 2566853885 Motor1sensorstatus 2551;
BA_ "SPN" SG_ 2566845735 RoadSurfaceTemp 79;
BA_ "SPN" SG_ 2566845735 EngAirInletTemp 172;
BA_ "SPN" SG_ 2566845735 AmbientAirTemp 171;
BA_ "SPN" SG_ 2566845735 CabInteriorTemp 170;
BA_ "SPN" SG_ 2566845735 BarometricPress 108;
BA_ "GenSigStartValue" SG_ 2566893337 SupplyWaterTempHP2 100;
BA_ "GenSigStartValue" SG_ 2566893337 SupplyWaterTempHP1 100;
BA_ "GenSigStartValue" SG_ 2566893337 String3HP2WaterTemp 100;
BA_ "GenSigStartValue" SG_ 2566893337 String3HP1WaterTemp 100;
BA_ "GenSigStartValue" SG_ 2566893337 String2HP2WaterTemp 100;
BA_ "GenSigStartValue" SG_ 2566893337 String2HP1WaterTemp 100;
BA_ "GenSigStartValue" SG_ 2566893337 String1HP2WaterTemp 100;
BA_ "GenSigStartValue" SG_ 2566893337 String1HP1WaterTemp 100;
BA_ "SPN" SG_ 2566834941 FailureModeIdentifier5 1215;
BA_ "SPN" SG_ 2566834941 FailureModeIdentifier4 1215;
BA_ "SPN" SG_ 2566834941 FailureModeIdentifier3 1215;
BA_ "SPN" SG_ 2566834941 FailureModeIdentifier2 1215;
BA_ "SPN" SG_ 2566834941 OccurenceCount5 1216;
BA_ "SPN" SG_ 2566834941 OccurenceCount4 1216;
BA_ "SPN" SG_ 2566834941 OccurenceCount3 1216;
BA_ "SPN" SG_ 2566834941 OccurenceCount2 1216;
BA_ "SPN" SG_ 2566834941 SPNConversionMethod5 1706;
BA_ "SPN" SG_ 2566834941 SPNConversionMethod4 1706;
BA_ "SPN" SG_ 2566834941 SPNConversionMethod3 1706;
BA_ "SPN" SG_ 2566834941 SPNConversionMethod2 1706;
BA_ "SPN" SG_ 2566834941 SPN5High 1214;
BA_ "SPN" SG_ 2566834941 SPN5 1214;
BA_ "SPN" SG_ 2566834941 SPN4High 1214;
BA_ "SPN" SG_ 2566834941 SPN4 1214;
BA_ "SPN" SG_ 2566834941 SPN3High 1214;
BA_ "SPN" SG_ 2566834941 SPN3 1214;
BA_ "SPN" SG_ 2566834941 SPN2High 1214;
BA_ "SPN" SG_ 2566834941 SPN2 1214;
BA_ "SPN" SG_ 2566834941 SPN1 1214;
BA_ "SPN" SG_ 2566834941 SPNConversionMethod1 1706;
BA_ "SPN" SG_ 2566834941 OccurenceCount1 1216;
BA_ "SPN" SG_ 2566834941 SPN1High 1214;
BA_ "SPN" SG_ 2566834941 FailureModeIdentifier1 1215;
BA_ "SPN" SG_ 2566834941 FlashMalfuncIndicatorLamp 3038;
BA_ "SPN" SG_ 2566834941 FlashRedStopLamp 3039;
BA_ "SPN" SG_ 2566834941 FlashAmberWarningLamp 3040;
BA_ "SPN" SG_ 2566834941 FlashProtectLamp 3041;
BA_ "SPN" SG_ 2566834941 MalfunctionIndicatorLampStatus 1213;
BA_ "SPN" SG_ 2566834941 RedStopLampState 623;
BA_ "SPN" SG_ 2566834941 AmberWarningLampStatus 624;
BA_ "SPN" SG_ 2566834941 ProtectLampStatus 987;
BA_ "SPN" SG_ 2566834713 FailureModeIdentifier5 1215;
BA_ "SPN" SG_ 2566834713 FailureModeIdentifier4 1215;
BA_ "SPN" SG_ 2566834713 FailureModeIdentifier3 1215;
BA_ "SPN" SG_ 2566834713 FailureModeIdentifier2 1215;
BA_ "SPN" SG_ 2566834713 OccurenceCount5 1216;
BA_ "SPN" SG_ 2566834713 OccurenceCount4 1216;
BA_ "SPN" SG_ 2566834713 OccurenceCount3 1216;
BA_ "SPN" SG_ 2566834713 OccurenceCount2 1216;
BA_ "SPN" SG_ 2566834713 SPNConversionMethod5 1706;
BA_ "SPN" SG_ 2566834713 SPNConversionMethod4 1706;
BA_ "SPN" SG_ 2566834713 SPNConversionMethod3 1706;
BA_ "SPN" SG_ 2566834713 SPNConversionMethod2 1706;
BA_ "SPN" SG_ 2566834713 SPN5High 1214;
BA_ "SPN" SG_ 2566834713 SPN5 1214;
BA_ "SPN" SG_ 2566834713 SPN4High 1214;
BA_ "SPN" SG_ 2566834713 SPN4 1214;
BA_ "SPN" SG_ 2566834713 SPN3High 1214;
BA_ "SPN" SG_ 2566834713 SPN3 1214;
BA_ "SPN" SG_ 2566834713 SPN2High 1214;
BA_ "SPN" SG_ 2566834713 SPN2 1214;
BA_ "SPN" SG_ 2566834713 SPN1 1214;
BA_ "SPN" SG_ 2566834713 SPNConversionMethod1 1706;
BA_ "SPN" SG_ 2566834713 OccurenceCount1 1216;
BA_ "SPN" SG_ 2566834713 SPN1High 1214;
BA_ "SPN" SG_ 2566834713 FailureModeIdentifier1 1215;
BA_ "SPN" SG_ 2566834713 FlashMalfuncIndicatorLamp 3038;
BA_ "SPN" SG_ 2566834713 FlashRedStopLamp 3039;
BA_ "SPN" SG_ 2566834713 FlashAmberWarningLamp 3040;
BA_ "SPN" SG_ 2566834713 FlashProtectLamp 3041;
BA_ "SPN" SG_ 2566834713 MalfunctionIndicatorLampStatus 1213;
BA_ "SPN" SG_ 2566834713 RedStopLampState 623;
BA_ "SPN" SG_ 2566834713 AmberWarningLampStatus 624;
BA_ "SPN" SG_ 2566834713 ProtectLampStatus 987;
BA_ "SPN" SG_ 2365531141 Illumination 1487;
BA_ "SPN" SG_ 2566769969 RearWasherFunction 2868;
BA_ "SPN" SG_ 2566769969 FrontOperatorWasherSwitch 2866;
BA_ "SPN" SG_ 2566769969 FrontNonoperatorWasherSwitch 2867;
BA_ "SPN" SG_ 2566769969 RearWiperDelayCtrl 2871;
BA_ "SPN" SG_ 2566769969 FrontNonoperatorWiperDelayCtrl 2870;
BA_ "SPN" SG_ 2566769969 FrontOperatorWiperDelayCtrl 2869;
BA_ "SPN" SG_ 2566769969 RearWiperSwitch 2865;
BA_ "SPN" SG_ 2566769969 FrontOperatorWiperSwitch 2863;
BA_ "SPN" SG_ 2566769969 FrontNonoperatorWiperSwitch 2864;
BA_ "SPN" SG_ 2561271857 LaneDepartureWarningEnableCmd 3564;
BA_ "SPN" SG_ 2563804199 Illumination 1487;
BA_ "SPN" SG_ 2563788071 Illumination 1487;
BA_ "SPN" SG_ 2563783217 SwitchIndicationIllumination 1487;
BA_ "SPN" SG_ 2563783217 SwitchBackIllumination 1487;
BA_ "SPN" SG_ 2563783217 DisplayIllumination 1487;
BA_ "SPN" SG_ 2563833598 SwitchIndicationIllumination 1487;
BA_ "SPN" SG_ 2563833598 SwitchBackIllumination 1487;
BA_ "SPN" SG_ 2563833598 Illumination 1487;
BA_ "SPN" SG_ 2365443121 OprtrsDesiredDelayedLampOffTime 2877;
BA_ "SPN" SG_ 2365443121 OperatorsDesiredBacklight 2878;
BA_ "SPN" SG_ 2365443121 HighLowBeamSwitch 2874;
BA_ "SPN" SG_ 2365443121 HazardLightSwitch 2875;
BA_ "SPN" SG_ 2365443121 TurnSignalSwitch 2876;
BA_ "SPN" SG_ 2365443121 MainLightSwitch 2872;
BA_ "SPN" SG_ 2365443121 WorkLightSwitch 2873;
BA_ "SPN" SG_ 2566853399 Year 964;
BA_ "SPN" SG_ 2566853399 Day 962;
BA_ "SPN" SG_ 2566853399 Month 963;
BA_ "SPN" SG_ 2566853399 Hours 961;
BA_ "SPN" SG_ 2566853399 Minutes 960;
BA_ "GenSigStartValue" SG_ 2566894650 FanSpeedKnob 5;
BA_ "GenSigStartValue" SG_ 2566894650 TemperatuurKnob 5;
BA_ "SPN" SG_ 2565867787 SteerWheelAngle 1807;
BA_ "SPN" SG_ 2566834828 FailureModeIdentifier5 1215;
BA_ "SPN" SG_ 2566834828 FailureModeIdentifier4 1215;
BA_ "SPN" SG_ 2566834828 FailureModeIdentifier3 1215;
BA_ "SPN" SG_ 2566834828 FailureModeIdentifier2 1215;
BA_ "SPN" SG_ 2566834828 OccurenceCount5 1216;
BA_ "SPN" SG_ 2566834828 OccurenceCount4 1216;
BA_ "SPN" SG_ 2566834828 OccurenceCount3 1216;
BA_ "SPN" SG_ 2566834828 OccurenceCount2 1216;
BA_ "SPN" SG_ 2566834828 SPNConversionMethod5 1706;
BA_ "SPN" SG_ 2566834828 SPNConversionMethod4 1706;
BA_ "SPN" SG_ 2566834828 SPNConversionMethod3 1706;
BA_ "SPN" SG_ 2566834828 SPNConversionMethod2 1706;
BA_ "SPN" SG_ 2566834828 SPN5High 1214;
BA_ "SPN" SG_ 2566834828 SPN5 1214;
BA_ "SPN" SG_ 2566834828 SPN4High 1214;
BA_ "SPN" SG_ 2566834828 SPN4 1214;
BA_ "SPN" SG_ 2566834828 SPN3High 1214;
BA_ "SPN" SG_ 2566834828 SPN3 1214;
BA_ "SPN" SG_ 2566834828 SPN2High 1214;
BA_ "SPN" SG_ 2566834828 SPN2 1214;
BA_ "SPN" SG_ 2566834828 SPN1 1214;
BA_ "SPN" SG_ 2566834828 SPNConversionMethod1 1706;
BA_ "SPN" SG_ 2566834828 OccurenceCount1 1216;
BA_ "SPN" SG_ 2566834828 SPN1High 1214;
BA_ "SPN" SG_ 2566834828 FailureModeIdentifier1 1215;
BA_ "SPN" SG_ 2566834828 FlashMalfuncIndicatorLamp 3038;
BA_ "SPN" SG_ 2566834828 FlashRedStopLamp 3039;
BA_ "SPN" SG_ 2566834828 FlashAmberWarningLamp 3040;
BA_ "SPN" SG_ 2566834828 FlashProtectLamp 3041;
BA_ "SPN" SG_ 2566834828 MalfunctionIndicatorLampStatus 1213;
BA_ "SPN" SG_ 2566834828 RedStopLampState 623;
BA_ "SPN" SG_ 2566834828 AmberWarningLampStatus 624;
BA_ "SPN" SG_ 2566834828 ProtectLampStatus 987;
BA_ "SPN" SG_ 2566834698 FailureModeIdentifier5 1215;
BA_ "SPN" SG_ 2566834698 FailureModeIdentifier4 1215;
BA_ "SPN" SG_ 2566834698 FailureModeIdentifier3 1215;
BA_ "SPN" SG_ 2566834698 FailureModeIdentifier2 1215;
BA_ "SPN" SG_ 2566834698 OccurenceCount5 1216;
BA_ "SPN" SG_ 2566834698 OccurenceCount4 1216;
BA_ "SPN" SG_ 2566834698 OccurenceCount3 1216;
BA_ "SPN" SG_ 2566834698 OccurenceCount2 1216;
BA_ "SPN" SG_ 2566834698 SPNConversionMethod5 1706;
BA_ "SPN" SG_ 2566834698 SPNConversionMethod4 1706;
BA_ "SPN" SG_ 2566834698 SPNConversionMethod3 1706;
BA_ "SPN" SG_ 2566834698 SPNConversionMethod2 1706;
BA_ "SPN" SG_ 2566834698 SPN5High 1214;
BA_ "SPN" SG_ 2566834698 SPN5 1214;
BA_ "SPN" SG_ 2566834698 SPN4High 1214;
BA_ "SPN" SG_ 2566834698 SPN4 1214;
BA_ "SPN" SG_ 2566834698 SPN3High 1214;
BA_ "SPN" SG_ 2566834698 SPN3 1214;
BA_ "SPN" SG_ 2566834698 SPN2High 1214;
BA_ "SPN" SG_ 2566834698 SPN2 1214;
BA_ "SPN" SG_ 2566834698 SPN1 1214;
BA_ "SPN" SG_ 2566834698 SPNConversionMethod1 1706;
BA_ "SPN" SG_ 2566834698 OccurenceCount1 1216;
BA_ "SPN" SG_ 2566834698 SPN1High 1214;
BA_ "SPN" SG_ 2566834698 FailureModeIdentifier1 1215;
BA_ "SPN" SG_ 2566834698 FlashMalfuncIndicatorLamp 3038;
BA_ "SPN" SG_ 2566834698 FlashRedStopLamp 3039;
BA_ "SPN" SG_ 2566834698 FlashAmberWarningLamp 3040;
BA_ "SPN" SG_ 2566834698 FlashProtectLamp 3041;
BA_ "SPN" SG_ 2566834698 MalfunctionIndicatorLampStatus 1213;
BA_ "SPN" SG_ 2566834698 RedStopLampState 623;
BA_ "SPN" SG_ 2566834698 AmberWarningLampStatus 624;
BA_ "SPN" SG_ 2566834698 ProtectLampStatus 987;
BA_ "SPN" SG_ 2566840303 NominalFrictionPercentTorque 514;
VAL_ 2566845491 TirePressThresholdDetection 7 "NotAvailable" 6 "ErrorIndicator" 5 "NotDefined" 4 "ExtrmUndrPrssTrPrssrIsAtALvlWhr" 3 "UndrPrssTrPrssrIsLwrThnThPrssrD" 2 "NWrnngPrssTrPrssrIsWthnThThrshl" 1 "OvrPrssTrPrssrIsHghrThnThPrssrD" 0 "ExtrmOvrPrssTrPrssrIsAtALvlWhrT" ;
VAL_ 2566845491 CTIWheelEndElectricalFault 3 "NotSupported" 2 "Error" 1 "NotDefined" 0 "Ok" ;
VAL_ 2566845491 CTITireStatus 3 "NotSupported" 2 "Error" 1 "TireLeakDetected" 0 "Ok" ;
VAL_ 2566845491 CTIWheelSensorStatus 3 "NotSupported" 2 "NotDefined" 1 "On" 0 "Off_IsolatedFromCTIPressCtrl" ;
VAL_ 2432593706 ACCDistanceAlertSignal 3 "TakeNoAction" 2 "Reserved" 1 "ACCDASActive" 0 "ACCDASNotActive" ;
VAL_ 2432593706 ACCSystemShutoffWarning 3 "TakeNoAction" 2 "Reserved" 1 "ACCSSOWActive" 0 "ACCSSOWNotActive" ;
VAL_ 2432593706 ACCTargetDetected 3 "TakeNoAction" 2 "Reserved" 1 "TargetDetected" 0 "NoTargetsDetected" ;
VAL_ 2432593706 AdptveCruiseCtrlSetDistanceMode 7 "NotAvailable_NotValid" 6 "ErrorCondition" 5 "ConventionalCruiseCtrlMode" 4 "ACCDistanceMode5" 3 "ACCDistanceMode4" 2 "ACCDistanceMode3" 1 "ACCDistanceMode2" 0 "ACCDistanceMode1" ;
VAL_ 2432593706 AdaptiveCruiseCtrlMode 7 "NotAvailable_NotValid" 6 "DsbldErrrCndtnUsdTIndctThtACCIs" 5 "FinishMode" 4 "HldMdUsdTIndctThtACCHsLstThPrvs" 3 "OvertakeMode" 2 "DstncCtrlActvUsdTIndctThtACCIsO" 1 "SpeedCtrlActive" 0 "OffUsdTIndctACCIsEnbldInClbCnfg" ;
VAL_ 2364551072 BendOffProbabillityOfRelObj 7 "Signal not available" 6 "Error indication" 5 "RelObject is in turning maneuver" 4 "Highest prob for bend of RelObj" 3 "High prob for bend of RelObject" 2 "Medium prob for bend RelObject" 1 "Low prob for bend RelObject" 0 "No ind for bend RelObject" ;
VAL_ 2364551072 RelevObjectDetForAEBS 2 "RelevantObj not being detected" 1 "RelevantObj being monitored" 0 "No relevant object monitored" ;
VAL_ 2364551072 CollisionWarningStatus 7 "Warning level 7 (highest)" 6 "Warning level 6" 5 "Warning level 5" 4 "Warning level 4" 3 "Warning level 3" 2 "Warning level 2" 1 "Warning level 1 (lowest)" 0 "No warning" ;
VAL_ 2364551072 AdvEmergenBrakingSysState 7 "Emergency braking active" 6 "Collision warning with braking" 5 "Collision warning active" 4 "Driver overrides system" 3 "System is ready and activated" 2 "System is deactivated by driver" 1 "System Temporarily not available" 0 "System not ready" ;
VAL_ 2566852168 PreconPossibilities 4 "HV Error" 3 "HV ON without charger connected" 2 "HV ON with Charging Error" 1 "Charging" 0 "Not defined" ;
VAL_ 2566852168 CoolantLevelDrivelineTooLow18m 3 "NotAvailable" 2 "Error" 1 "Active" 0 "Off" ;
VAL_ 2566852168 CoolantLevelDrivelineLow18m 3 "NotAvailable" 2 "Error" 1 "Active" 0 "Off" ;
VAL_ 2566852168 CoolantLevelDrivelineTooLow 3 "NotAvailable" 2 "Error" 1 "Active" 0 "Off" ;
VAL_ 2566852168 CoolantLevelDrivelineLow 3 "NotAvailable" 2 "Error" 1 "Active" 0 "Off" ;
VAL_ 2566852168 PantographRaised 3 "NA" 2 "Error" 1 "Pantograph raised" 0 "No Pantrograph raised" ;
VAL_ 2566767627 BrakeTempWarning 3 "notAvailable" 2 "Reserved" 1 "Active" 0 "NotActive" ;
VAL_ 2566767627 XBRActiveCtrlMode 15 "NotAvailable" 4 "1110ReservedForSAEAssignment" 3 "MxMdOfXBRAcclrtnCtrlBngExecuted" 2 "AddtnMdOfXBRAcclrtnCtrlBngExctd" 1 "DrvrsBrkDmndBngExctdNExtlBrkDmn" 0 "NoBrakeDemandBeingExecuted" ;
VAL_ 2566767627 XBRSystemState 3 "NotAvailable" 2 "NoExtlBrakeDemandWillBeAccepted" 1 "OnlyExtlBrkDmndOfHghstXBRPrrtyW" 0 "AnyExtlBrkeDemandWillBeAccepted" ;
VAL_ 2566767627 FoundationBrakeUse 3 "NotAvailable" 2 "Reserved" 1 "FoundationBrakesInUse" 0 "FoundationBrakesNotInUse" ;
VAL_ 2566767627 HillHolderMode 5 "Reserved" 4 "Reserved" 7 "NotAvailable" 6 "HillHolderNotFunctional" 3 "ActvBtMyActvtPrkBrkIfNeeded" 2 "ActvBtWllChngTInctvInAShortTime" 1 "Active" 0 "Inactive" ;
VAL_ 2566767627 HaltBrakeMode 7 "NotAvailable" 6 "Reserved" 3 "101NotDefined" 2 "ActiveButNotFunctioningProperly" 1 "Active" 0 "Inactive" ;
VAL_ 2565865739 TrctrMntdTrilerABSWarningSignal 3 "TakeNoAction" 2 "Reserved" 1 "On" 0 "Off" ;
VAL_ 2565865739 TrailerABSStatus 3 "TrlrABSSttsInfrmtnNtAvlblPrmtrN" 2 "Reserved" 1 "TrailerABSActive" 0 "TrlrABSSttsInfrmtnAvlblBtNtActv" ;
VAL_ 2565865739 HaltBrakeSwitch 3 "NotAvailable" 2 "Error" 1 "HaltBrakeSwitchActive" 0 "HaltBrakeSwitchPassive" ;
VAL_ 2565865739 ATC_ASRInformationSignal 3 "TakeNoAction" 2 "Reserved" 1 "On" 0 "Off" ;
VAL_ 2565865739 ABS_EBSAmberWarningSignal 3 "TakeNoAction" 2 "Reserved" 1 "On" 0 "Off" ;
VAL_ 2565865739 EBSRedWarningSignal 3 "TakeNoAction" 2 "Reserved" 1 "On" 0 "Off" ;
VAL_ 2565865739 ABSFullyOperational 3 "NotAvailable" 2 "Reserved" 1 "FullyOperational" 0 "NotFullyOperational" ;
VAL_ 2565865739 RemoteAccelEnableSwitch 3 "NotAvailable" 2 "Error" 1 "On" 0 "Off" ;
VAL_ 2565865739 EngAuxEngShutdownSwitch 3 "NotAvailable" 2 "Error" 1 "On" 0 "Off" ;
VAL_ 2565865739 EngDerateSwitch 3 "NotAvailable" 2 "Error" 1 "On" 0 "Off" ;
VAL_ 2565865739 AccelInterlockSwitch 3 "NotAvailable" 2 "Error" 1 "On" 0 "Off" ;
VAL_ 2565865739 TractionCtrlOverrideSwitch 3 "NotAvailableNotInstalled" 2 "Error" 1 "On" 0 "Off" ;
VAL_ 2565865739 ASRHillHolderSwitch 3 "NotAvailable" 2 "Error" 1 "ASRHillHolderSwitchActive" 0 "ASRHillHolderSwitchPassive" ;
VAL_ 2565865739 ASROffroadSwitch 2 "Error" 1 "ASROffroadSwitchActive" 0 "ASROffroadSwitchPassive" 3 "NotAvailable" ;
VAL_ 2565865739 ABSOffroadSwitch 3 "NotAvailable" 2 "Error" 1 "ABSOffroadSwitchActive" 0 "ABSOffroadSwitchPassive" ;
VAL_ 2565865739 EBSBrakeSwitch 3 "NotAvailable" 2 "Error" 1 "BrakePedalIsBeingPressed" 0 "BrakePedalIsNotBeingPressed" ;
VAL_ 2565865739 AntiLockBrakingActive 3 "NotAvailable" 2 "Reserved" 1 "ABSActive" 0 "ABSPassiveButInstalled" ;
VAL_ 2565865739 ASRBrakeCtrlActive 3 "NotAvailable" 2 "Reserved" 1 "ASRBrakeCtrlActive" 0 "ASRBrakeCtrlPassiveButInstalled" ;
VAL_ 2565865739 ASREngCtrlActive 3 "NotAvailable" 2 "Reserved" 1 "ASREngCtrlActive" 0 "ASREngCtrlPassiveButInstalled" ;
VAL_ 2365479471 SspensionCtrlRefusalInformation 7 "1101NotDefined" 15 "NotAvailable" 14 "Error" 6 "GnrlRjctINSpcifiedReasonApplies" 5 "BelowSpeedLimit" 4 "AboveSpeedLimit" 3 "BogieDiffNotLocked" 2 "WouldExceedAxleLoadLimit" 1 "AxleLoadLimitReached" 0 "ActualRqNotRefused" ;
VAL_ 2365479471 SuspensionRemoteCtrl2 3 "NotAvailable" 2 "Error" 1 "Active" 0 "NotActive" ;
VAL_ 2365479471 SuspensionRemoteCtrl1 3 "NotAvailable" 2 "Error" 1 "Active" 0 "NotActive" ;
VAL_ 2365479471 RearAxleInBumperRange 3 "NotAvailable" 2 "Error" 1 "ActualLevelWithinBumperRange" 0 "ActualLevelOutOfBumperRange" ;
VAL_ 2365479471 FrontAxleInBumperRange 3 "NotAvailable" 2 "Error" 1 "ActualLevelWithinBumperRange" 0 "ActualLevelOutOfBumperRange" ;
VAL_ 2365479471 DoorRelease 3 "NotAvailable" 2 "Error" 1 "DoorsMayBeOpened" 0 "DoorsMayNotBeOpened" ;
VAL_ 2365479471 VehicleMotionInhibit 3 "NotAvailable" 2 "Error" 1 "VehicleMotionIsInhibited" 0 "VehicleMayBeMoved" ;
VAL_ 2365479471 SecurityDevice 3 "NotAvailable" 2 "Error" 1 "Active" 0 "NotActive" ;
VAL_ 2365479471 LevelCtrlMode 10 "1101NotDefined" 15 "NotAvailable" 14 "Error" 9 "AirSuspensionCtrlProhibited" 8 "ExhstngBllwFnctnIBllwsArExhstdT" 7 "TractionHelpLoadReduce" 6 "OptmmTrctn2IPrssAtThDrvnAxlIsCt" 5 "OptmmTrctn1IPrssAtThDrvnAxlIsCt" 4 "PrssRt2IRtBtwnThPrssrsAtThDrvnA" 3 "PrssRt1IRtBtwnThPrssrsAtThDrvnA" 2 "LdFxngIDrvnAxlnIsLddTAVlDfndByT" 1 "TrctnHlpIDrvnAxlIsLddTAMxVlGvnB" 0 "NrmlOprtnISystmPrfrmsAPrCtrlOfT" ;
VAL_ 2365479471 KneelingInformation 15 "NotAvailable" 14 "Error" 5 "1101NotDefined" 4 "KneelingAborted" 3 "LiftingActive" 2 "KneelingLevelReached" 0 "NotActive" ;
VAL_ 2365479471 LiftingCtrlModeRearAxle 3 "NotAvailable" 2 "Error" 1 "LiftingActive" 0 "LiftingNotActive" ;
VAL_ 2365479471 LiftingCtrlModeFrontAxle 3 "NotAvailable" 2 "Error" 1 "LiftingActive" 0 "LiftingNotActive" ;
VAL_ 2365479471 LoweringCtrlModeRearAxle 3 "NotAvailable" 2 "Error" 1 "LoweringActive" 0 "LoweringNotActive" ;
VAL_ 2365479471 LoweringCtrlModeFrontAxle 3 "NotAvailable" 2 "Error" 1 "LoweringActive" 0 "LoweringNotActive" ;
VAL_ 2365479471 AboveNominalLevelRearAxle 3 "NotAvailable" 2 "Error" 1 "Above" 0 "NotAbove" ;
VAL_ 2365479471 AboveNominalLevelFrontAxle 3 "NotAvailable" 2 "Error" 1 "Above" 0 "NotAbove" ;
VAL_ 2365479471 BelowNominalLevelRearAxle 3 "NotAvailable" 2 "Error" 1 "Below" 0 "NotBelow" ;
VAL_ 2365479471 BelowNominalLevelFrontAxle 3 "NotAvailable" 2 "Error" 1 "Below" 0 "NotBelow" ;
VAL_ 2365479471 NominalLevelRearAxle 15 "NotAvailable" 14 "Error" 8 "1101NotDefined" 7 "LowerLevel" 6 "UpperLevel" 5 "CustomerLevel" 4 "PresetLevel" 3 "NormalLevel3" 2 "NormalLevel2" 1 "NormalLevel1" 0 "LevelNotSpecified" ;
VAL_ 2365479471 NominalLevelFrontAxle 15 "NotAvailable" 14 "Error" 8 "1101NotDefined" 7 "LowerLevel" 6 "UpperLevel" 5 "CustomerLevel" 4 "PresetLevel" 3 "NormalLevel3" 2 "NormalLevel2" 1 "NormalLevel1" 0 "LevelNotSpecified" ;
VAL_ 2365479471 LiftAxle2Pos 3 "NotAvailable" 2 "Error" 1 "LiftAxlePosUp_TagAxleUnladen" 0 "LiftAxlePosDown_TagAxleLaden" ;
VAL_ 2365479471 LiftAxle1Pos 3 "NotAvailable" 2 "Error" 1 "LiftAxlePosUp_TagAxleUnladen" 0 "LiftAxlePosDown_TagAxleLaden" ;
VAL_ 2365525031 EmergencyBrakeLight 3 "Not Available" 2 "Error" 1 "BrakeLight Request" 0 "No BrakeLight Request" ;
VAL_ 2365525031 BrakeLightRequest 3 "Not Available" 2 "Error" 1 "BrakeLight Request" 0 "No BrakeLight Request" ;
VAL_ 2565812692 DeadboltInput 3 "Not Available" 2 "Error" 1 "On" 0 "Off" ;
VAL_ 2565812692 Door_Block_Input_State 3 "Not Available" 2 "Error" 1 "On" 0 "Off" ;
VAL_ 2565812692 Light_Barrier_Input_State 3 "Not Available" 2 "Error" 1 "On" 0 "Off" ;
VAL_ 2565812692 External_Close_Button 3 "Not Available" 2 "Error" 1 "On" 0 "Off" ;
VAL_ 2565812692 External_Open_Button 3 "Not Available" 2 "Error" 1 "On" 0 "Off" ;
VAL_ 2565812692 Workshop_Button 3 "Not Available" 2 "Error" 1 "On" 0 "Off" ;
VAL_ 2565812692 Inner_Sensitive_Edge_Input_State 3 "Not Available" 2 "Error" 1 "On" 0 "Off" ;
VAL_ 2565812692 Spare_In_5 3 "Not Available" 2 "Error" 1 "On" 0 "Off" ;
VAL_ 2565812692 Spare_In_4 3 "Not Available" 2 "Error" 1 "On" 0 "Off" ;
VAL_ 2565812692 Spare_In_3 3 "Not Available" 2 "Error" 1 "On" 0 "Off" ;
VAL_ 2565812692 Spare_In_2 3 "Not Available" 2 "Error" 1 "On" 0 "Off" ;
VAL_ 2565812692 Spare_In_1 3 "Not Available" 2 "Error" 1 "On" 0 "Off" ;
VAL_ 2565812692 Door_Mode_Right 15 "Not Available" 14 "Invalid" 13 "Invalid" 12 "Invalid" 11 "Invalid" 10 "Invalid" 9 "Invalid" 8 "Invalid" 7 "Invalid" 6 "Invalid" 5 "Calibrating" 4 "Major Error" 3 "Minor Error" 2 "Emergency" 1 "Normal" 0 "Init" ;
VAL_ 2565812692 Door_Mode_Left 15 "Not Available" 14 "Invalid" 13 "Invalid" 12 "Invalid" 11 "Invalid" 10 "Invalid" 9 "Invalid" 8 "Invalid" 7 "Invalid" 6 "Invalid" 5 "Calibrating" 4 "Major Error" 3 "Minor Error" 2 "Emergency" 1 "Normal" 0 "Init" ;
VAL_ 2565812692 Right_Leaf_Obstruction_State 15 "Not Available" 14 "Error" 13 "Invalid" 12 "Invalid" 11 "Invalid" 10 "Invalid" 9 "Contextless Speed" 8 "Contextless Time" 7 "Open Time" 6 "Open Sensitive Edge" 5 "Open Speed" 4 "Close Time" 3 "Light Barrier" 2 "Close Sensitive Edge" 1 "Close Speed" 0 "No Obstruction" ;
VAL_ 2565812692 Left_Leaf_Obstruction_State 15 "Not Available" 14 "Error" 13 "Invalid" 12 "Invalid" 11 "Invalid" 10 "Invalid" 9 "Contextless Speed" 8 "Contextless Time" 7 "Open Time" 6 "Open Sensitive Edge" 5 "Open Speed" 4 "Close Time" 3 "Light Barrier" 2 "Close Sensitive Edge" 1 "Close Speed" 0 "No Obstruction" ;
VAL_ 2565812692 Door_Position_Right 255 "Not Available" 254 "Error" ;
VAL_ 2565812692 Door_Position_Left 255 "Not Available" 254 "Error" ;
VAL_ 2565812692 Leaf_State_Right 15 "Not Available" 14 "Error" 13 "Invalid" 12 "Invalid" 11 "Invalid" 10 "Invalid" 9 "Invalid" 8 "Invalid" 7 "Invalid" 6 "Invalid" 5 "Invalid" 4 "Open" 3 "Opening" 2 "Stopped" 1 "Closing" 0 "Closed" ;
VAL_ 2565812692 Leaf_State_Left 15 "Not Available" 14 "Error" 13 "Invalid" 12 "Invalid" 11 "Invalid" 10 "Invalid" 9 "Invalid" 8 "Invalid" 7 "Invalid" 6 "Invalid" 5 "Invalid" 4 "Open" 3 "Opening" 2 "Stopped" 1 "Closing" 0 "Closed" ;
VAL_ 2565812691 DeadboltInput 3 "Not Available" 2 "Error" 1 "On" 0 "Off" ;
VAL_ 2565812691 Door_Block_Input_State 3 "Not Available" 2 "Error" 1 "On" 0 "Off" ;
VAL_ 2565812691 Light_Barrier_Input_State 3 "Not Available" 2 "Error" 1 "On" 0 "Off" ;
VAL_ 2565812691 External_Close_Button 3 "Not Available" 2 "Error" 1 "On" 0 "Off" ;
VAL_ 2565812691 External_Open_Button 3 "Not Available" 2 "Error" 1 "On" 0 "Off" ;
VAL_ 2565812691 Workshop_Button 3 "Not Available" 2 "Error" 1 "On" 0 "Off" ;
VAL_ 2565812691 Inner_Sensitive_Edge_Input_State 3 "Not Available" 2 "Error" 1 "On" 0 "Off" ;
VAL_ 2565812691 Spare_In_5 3 "Not Available" 2 "Error" 1 "On" 0 "Off" ;
VAL_ 2565812691 Spare_In_4 3 "Not Available" 2 "Error" 1 "On" 0 "Off" ;
VAL_ 2565812691 Spare_In_3 3 "Not Available" 2 "Error" 1 "On" 0 "Off" ;
VAL_ 2565812691 Spare_In_2 3 "Not Available" 2 "Error" 1 "On" 0 "Off" ;
VAL_ 2565812691 Spare_In_1 3 "Not Available" 2 "Error" 1 "On" 0 "Off" ;
VAL_ 2565812691 Door_Mode_Right 15 "Not Available" 14 "Invalid" 13 "Invalid" 12 "Invalid" 11 "Invalid" 10 "Invalid" 9 "Invalid" 8 "Invalid" 7 "Invalid" 6 "Invalid" 5 "Calibrating" 4 "Major Error" 3 "Minor Error" 2 "Emergency" 1 "Normal" 0 "Init" ;
VAL_ 2565812691 Door_Mode_Left 15 "Not Available" 14 "Invalid" 13 "Invalid" 12 "Invalid" 11 "Invalid" 10 "Invalid" 9 "Invalid" 8 "Invalid" 7 "Invalid" 6 "Invalid" 5 "Calibrating" 4 "Major Error" 3 "Minor Error" 2 "Emergency" 1 "Normal" 0 "Init" ;
VAL_ 2565812691 Right_Leaf_Obstruction_State 15 "Not Available" 14 "Error" 13 "Invalid" 12 "Invalid" 11 "Invalid" 10 "Invalid" 9 "Contextless Speed" 8 "Contextless Time" 7 "Open Time" 6 "Open Sensitive Edge" 5 "Open Speed" 4 "Close Time" 3 "Light Barrier" 2 "Close Sensitive Edge" 1 "Close Speed" 0 "No Obstruction" ;
VAL_ 2565812691 Left_Leaf_Obstruction_State 15 "Not Available" 14 "Error" 13 "Invalid" 12 "Invalid" 11 "Invalid" 10 "Invalid" 9 "Contextless Speed" 8 "Contextless Time" 7 "Open Time" 6 "Open Sensitive Edge" 5 "Open Speed" 4 "Close Time" 3 "Light Barrier" 2 "Close Sensitive Edge" 1 "Close Speed" 0 "No Obstruction" ;
VAL_ 2565812691 Door_Position_Right 255 "Not Available" 254 "Error" ;
VAL_ 2565812691 Door_Position_Left 255 "Not Available" 254 "Error" ;
VAL_ 2565812691 Leaf_State_Right 15 "Not Available" 14 "Error" 13 "Invalid" 12 "Invalid" 11 "Invalid" 10 "Invalid" 9 "Invalid" 8 "Invalid" 7 "Invalid" 6 "Invalid" 5 "Invalid" 4 "Open" 3 "Opening" 2 "Stopped" 1 "Closing" 0 "Closed" ;
VAL_ 2565812691 Leaf_State_Left 15 "Not Available" 14 "Error" 13 "Invalid" 12 "Invalid" 11 "Invalid" 10 "Invalid" 9 "Invalid" 8 "Invalid" 7 "Invalid" 6 "Invalid" 5 "Invalid" 4 "Open" 3 "Opening" 2 "Stopped" 1 "Closing" 0 "Closed" ;
VAL_ 2565812690 DeadboltInput 3 "Not Available" 2 "Error" 1 "On" 0 "Off" ;
VAL_ 2565812690 Door_Block_Input_State 3 "Not Available" 2 "Error" 1 "On" 0 "Off" ;
VAL_ 2565812690 Light_Barrier_Input_State 3 "Not Available" 2 "Error" 1 "On" 0 "Off" ;
VAL_ 2565812690 External_Close_Button 3 "Not Available" 2 "Error" 1 "On" 0 "Off" ;
VAL_ 2565812690 External_Open_Button 3 "Not Available" 2 "Error" 1 "On" 0 "Off" ;
VAL_ 2565812690 Workshop_Button 3 "Not Available" 2 "Error" 1 "On" 0 "Off" ;
VAL_ 2565812690 Inner_Sensitive_Edge_Input_State 3 "Not Available" 2 "Error" 1 "On" 0 "Off" ;
VAL_ 2565812690 Spare_In_5 3 "Not Available" 2 "Error" 1 "On" 0 "Off" ;
VAL_ 2565812690 Spare_In_4 3 "Not Available" 2 "Error" 1 "On" 0 "Off" ;
VAL_ 2565812690 Spare_In_3 3 "Not Available" 2 "Error" 1 "On" 0 "Off" ;
VAL_ 2565812690 Spare_In_2 3 "Not Available" 2 "Error" 1 "On" 0 "Off" ;
VAL_ 2565812690 Spare_In_1 3 "Not Available" 2 "Error" 1 "On" 0 "Off" ;
VAL_ 2565812690 Door_Mode_Right 15 "Not Available" 14 "Invalid" 13 "Invalid" 12 "Invalid" 11 "Invalid" 10 "Invalid" 9 "Invalid" 8 "Invalid" 7 "Invalid" 6 "Invalid" 5 "Calibrating" 4 "Major Error" 3 "Minor Error" 2 "Emergency" 1 "Normal" 0 "Init" ;
VAL_ 2565812690 Door_Mode_Left 15 "Not Available" 14 "Invalid" 13 "Invalid" 12 "Invalid" 11 "Invalid" 10 "Invalid" 9 "Invalid" 8 "Invalid" 7 "Invalid" 6 "Invalid" 5 "Calibrating" 4 "Major Error" 3 "Minor Error" 2 "Emergency" 1 "Normal" 0 "Init" ;
VAL_ 2565812690 Right_Leaf_Obstruction_State 15 "Not Available" 14 "Error" 13 "Invalid" 12 "Invalid" 11 "Invalid" 10 "Invalid" 9 "Contextless Speed" 8 "Contextless Time" 7 "Open Time" 6 "Open Sensitive Edge" 5 "Open Speed" 4 "Close Time" 3 "Light Barrier" 2 "Close Sensitive Edge" 1 "Close Speed" 0 "No Obstruction" ;
VAL_ 2565812690 Left_Leaf_Obstruction_State 15 "Not Available" 14 "Error" 13 "Invalid" 12 "Invalid" 11 "Invalid" 10 "Invalid" 9 "Contextless Speed" 8 "Contextless Time" 7 "Open Time" 6 "Open Sensitive Edge" 5 "Open Speed" 4 "Close Time" 3 "Light Barrier" 2 "Close Sensitive Edge" 1 "Close Speed" 0 "No Obstruction" ;
VAL_ 2565812690 Door_Position_Right 255 "Not Available" 254 "Error" ;
VAL_ 2565812690 Door_Position_Left 255 "Not Available" 254 "Error" ;
VAL_ 2565812690 Leaf_State_Right 15 "Not Available" 14 "Error" 13 "Invalid" 12 "Invalid" 11 "Invalid" 10 "Invalid" 9 "Invalid" 8 "Invalid" 7 "Invalid" 6 "Invalid" 5 "Invalid" 4 "Open" 3 "Opening" 2 "Stopped" 1 "Closing" 0 "Closed" ;
VAL_ 2565812690 Leaf_State_Left 15 "Not Available" 14 "Error" 13 "Invalid" 12 "Invalid" 11 "Invalid" 10 "Invalid" 9 "Invalid" 8 "Invalid" 7 "Invalid" 6 "Invalid" 5 "Invalid" 4 "Open" 3 "Opening" 2 "Stopped" 1 "Closing" 0 "Closed" ;
VAL_ 2565812689 DeadboltInput 3 "Not Available" 2 "Error" 1 "On" 0 "Off" ;
VAL_ 2565812689 Door_Block_Input_State 3 "Not Available" 2 "Error" 1 "On" 0 "Off" ;
VAL_ 2565812689 Light_Barrier_Input_State 3 "Not Available" 2 "Error" 1 "On" 0 "Off" ;
VAL_ 2565812689 External_Close_Button 3 "Not Available" 2 "Error" 1 "On" 0 "Off" ;
VAL_ 2565812689 External_Open_Button 3 "Not Available" 2 "Error" 1 "On" 0 "Off" ;
VAL_ 2565812689 Workshop_Button 3 "Not Available" 2 "Error" 1 "On" 0 "Off" ;
VAL_ 2565812689 Inner_Sensitive_Edge_Input_State 3 "Not Available" 2 "Error" 1 "On" 0 "Off" ;
VAL_ 2565812689 Spare_In_5 3 "Not Available" 2 "Error" 1 "On" 0 "Off" ;
VAL_ 2565812689 Spare_In_4 3 "Not Available" 2 "Error" 1 "On" 0 "Off" ;
VAL_ 2565812689 Spare_In_3 3 "Not Available" 2 "Error" 1 "On" 0 "Off" ;
VAL_ 2565812689 Spare_In_2 3 "Not Available" 2 "Error" 1 "On" 0 "Off" ;
VAL_ 2565812689 Spare_In_1 3 "Not Available" 2 "Error" 1 "On" 0 "Off" ;
VAL_ 2565812689 Door_Mode_Right 15 "Not Available" 14 "Invalid" 13 "Invalid" 12 "Invalid" 11 "Invalid" 10 "Invalid" 9 "Invalid" 8 "Invalid" 7 "Invalid" 6 "Invalid" 5 "Calibrating" 4 "Major Error" 3 "Minor Error" 2 "Emergency" 1 "Normal" 0 "Init" ;
VAL_ 2565812689 Door_Mode_Left 15 "Not Available" 14 "Invalid" 13 "Invalid" 12 "Invalid" 11 "Invalid" 10 "Invalid" 9 "Invalid" 8 "Invalid" 7 "Invalid" 6 "Invalid" 5 "Calibrating" 4 "Major Error" 3 "Minor Error" 2 "Emergency" 1 "Normal" 0 "Init" ;
VAL_ 2565812689 Right_Leaf_Obstruction_State 15 "Not Available" 14 "Error" 13 "Invalid" 12 "Invalid" 11 "Invalid" 10 "Invalid" 9 "Contextless Speed" 8 "Contextless Time" 7 "Open Time" 6 "Open Sensitive Edge" 5 "Open Speed" 4 "Close Time" 3 "Light Barrier" 2 "Close Sensitive Edge" 1 "Close Speed" 0 "No Obstruction" ;
VAL_ 2565812689 Left_Leaf_Obstruction_State 15 "Not Available" 14 "Error" 13 "Invalid" 12 "Invalid" 11 "Invalid" 10 "Invalid" 9 "Contextless Speed" 8 "Contextless Time" 7 "Open Time" 6 "Open Sensitive Edge" 5 "Open Speed" 4 "Close Time" 3 "Light Barrier" 2 "Close Sensitive Edge" 1 "Close Speed" 0 "No Obstruction" ;
VAL_ 2565812689 Door_Position_Right 255 "Not Available" 254 "Error" ;
VAL_ 2565812689 Door_Position_Left 255 "Not Available" 254 "Error" ;
VAL_ 2565812689 Leaf_State_Right 15 "Not Available" 14 "Error" 13 "Invalid" 12 "Invalid" 11 "Invalid" 10 "Invalid" 9 "Invalid" 8 "Invalid" 7 "Invalid" 6 "Invalid" 5 "Invalid" 4 "Open" 3 "Opening" 2 "Stopped" 1 "Closing" 0 "Closed" ;
VAL_ 2565812689 Leaf_State_Left 15 "Not Available" 14 "Error" 13 "Invalid" 12 "Invalid" 11 "Invalid" 10 "Invalid" 9 "Invalid" 8 "Invalid" 7 "Invalid" 6 "Invalid" 5 "Invalid" 4 "Open" 3 "Opening" 2 "Stopped" 1 "Closing" 0 "Closed" ;
VAL_ 2565854257 Inhibit_Opening 3 "Not Available" 2 "Invalid" 1 "On" 0 "Off" ;
VAL_ 2565854257 Inhibit_Closing 3 "Not Available" 2 "Invalid" 1 "On" 0 "Off" ;
VAL_ 2565854257 Ignore_Outer_Sensitive_Edge 3 "Not Available" 2 "Invalid" 1 "Ignore" 0 "Don't ignore" ;
VAL_ 2565854257 Ignore_Light_Barrier 3 "Not Available" 2 "Invalid" 1 "Ignore" 0 "Don't ignore" ;
VAL_ 2565854257 Spare_Out_Request_7 3 "Not Available" 2 "Invalid" 1 "On" 0 "Off" ;
VAL_ 2565854257 Spare_Out_Request_5 3 "Not Available" 2 "Invalid" 1 "On" 0 "Off" ;
VAL_ 2565854257 Spare_Out_Request_4 3 "Not Available" 2 "Invalid" 1 "On" 0 "Off" ;
VAL_ 2565854257 Spare_Out_Request_3 3 "Not Available" 2 "Invalid" 1 "On" 0 "Off" ;
VAL_ 2565854257 Spare_Out_Request_2 3 "Not Available" 2 "Invalid" 1 "On" 0 "Off" ;
VAL_ 2565854257 Spare_Out_Request_6 3 "Not Available" 2 "Invalid" 1 "On" 0 "Off" ;
VAL_ 2565854257 Spare_Out_Request_8 3 "Not Available" 2 "Invalid" 1 "On" 0 "Off" ;
VAL_ 2565854257 Ignore_Speed_Obstruction 3 "Not Available" 2 "Invalid" 1 "Ignore" 0 "Don't ignore" ;
VAL_ 2565854257 Ignore_Sensitive_Edge 3 "Not Available" 2 "Invalid" 1 "Ignore" 0 "Don't ignore" ;
VAL_ 2565854257 Spare_Out_Request_1 3 "Not Available" 2 "Invalid" 1 "On" 0 "Off" ;
VAL_ 2565854257 Door_Position_Request_Right 250 "Fully Opened" 0 "Fully Closed" 253 "Invalid" 252 "Invalid" 251 "Invalid" 255 "Fully Opened/Closed" 254 "Invalid" ;
VAL_ 2565854257 Door_Position_Request_Left_Both 250 "Fully Opened" 0 "Fully Closed" 253 "Invalid" 252 "Invalid" 251 "Invalid" 255 "Fully Opened/Closed" 254 "Invalid" ;
VAL_ 2565854257 Right_Leaf_Command 15 "No Command" 14 "Invalid" 13 "Invalid" 12 "Invalid" 11 "Invalid" 10 "Invalid" 9 "Invalid" 8 "Invalid" 7 "Invalid" 6 "Invalid" 5 "Invalid" 4 "Invalid" 3 "Calibrate" 2 "Open" 1 "Close" 0 "Stop" ;
VAL_ 2565854257 Left_Leaf_Command 15 "No Command" 14 "Invalid" 13 "Invalid" 12 "Invalid" 11 "Invalid" 10 "Invalid" 9 "Invalid" 8 "Invalid" 7 "Invalid" 6 "Invalid" 5 "Invalid" 4 "Invalid" 3 "Calibrate" 2 "Open" 1 "Close" 0 "Stop" ;
VAL_ 2565854257 Buzzer 3 "Invalid" 2 "Auto" 1 "On" 0 "Off" ;
VAL_ 2565854257 Step_Lights 3 "Invalid" 2 "Auto" 1 "On" 0 "Off" ;
VAL_ 2565854257 Reset_Inhibit_Emergency_Valve 3 "Not Available" 2 "Invalid" 1 "On" 0 "Off" ;
VAL_ 2565854257 Speed_Standstill_Signal 3 "Not Available" 2 "Error" 1 "Standstill" 0 "Driving" ;
VAL_ 2565854001 Inhibit_Opening 3 "Not Available" 2 "Invalid" 1 "On" 0 "Off" ;
VAL_ 2565854001 Inhibit_Closing 3 "Not Available" 2 "Invalid" 1 "On" 0 "Off" ;
VAL_ 2565854001 Ignore_Outer_Sensitive_Edge 3 "Not Available" 2 "Invalid" 1 "Ignore" 0 "Don't ignore" ;
VAL_ 2565854001 Ignore_Light_Barrier 3 "Not Available" 2 "Invalid" 1 "Ignore" 0 "Don't ignore" ;
VAL_ 2565854001 Spare_Out_Request_7 3 "Not Available" 2 "Invalid" 1 "On" 0 "Off" ;
VAL_ 2565854001 Spare_Out_Request_5 3 "Not Available" 2 "Invalid" 1 "On" 0 "Off" ;
VAL_ 2565854001 Spare_Out_Request_4 3 "Not Available" 2 "Invalid" 1 "On" 0 "Off" ;
VAL_ 2565854001 Spare_Out_Request_3 3 "Not Available" 2 "Invalid" 1 "On" 0 "Off" ;
VAL_ 2565854001 Spare_Out_Request_2 3 "Not Available" 2 "Invalid" 1 "On" 0 "Off" ;
VAL_ 2565854001 Spare_Out_Request_6 3 "Not Available" 2 "Invalid" 1 "On" 0 "Off" ;
VAL_ 2565854001 Spare_Out_Request_8 3 "Not Available" 2 "Invalid" 1 "On" 0 "Off" ;
VAL_ 2565854001 Ignore_Speed_Obstruction 3 "Not Available" 2 "Invalid" 1 "Ignore" 0 "Don't ignore" ;
VAL_ 2565854001 Ignore_Sensitive_Edge 3 "Not Available" 2 "Invalid" 1 "Ignore" 0 "Don't ignore" ;
VAL_ 2565854001 Spare_Out_Request_1 3 "Not Available" 2 "Invalid" 1 "On" 0 "Off" ;
VAL_ 2565854001 Door_Position_Request_Right 250 "Fully Opened" 0 "Fully Closed" 253 "Invalid" 252 "Invalid" 251 "Invalid" 255 "Fully Opened/Closed" 254 "Invalid" ;
VAL_ 2565854001 Door_Position_Request_Left_Both 250 "Fully Opened" 0 "Fully Closed" 253 "Invalid" 252 "Invalid" 251 "Invalid" 255 "Fully Opened/Closed" 254 "Invalid" ;
VAL_ 2565854001 Right_Leaf_Command 15 "No Command" 14 "Invalid" 13 "Invalid" 12 "Invalid" 11 "Invalid" 10 "Invalid" 9 "Invalid" 8 "Invalid" 7 "Invalid" 6 "Invalid" 5 "Invalid" 4 "Invalid" 3 "Calibrate" 2 "Open" 1 "Close" 0 "Stop" ;
VAL_ 2565854001 Left_Leaf_Command 15 "No Command" 14 "Invalid" 13 "Invalid" 12 "Invalid" 11 "Invalid" 10 "Invalid" 9 "Invalid" 8 "Invalid" 7 "Invalid" 6 "Invalid" 5 "Invalid" 4 "Invalid" 3 "Calibrate" 2 "Open" 1 "Close" 0 "Stop" ;
VAL_ 2565854001 Buzzer 3 "Invalid" 2 "Auto" 1 "On" 0 "Off" ;
VAL_ 2565854001 Step_Lights 3 "Invalid" 2 "Auto" 1 "On" 0 "Off" ;
VAL_ 2565854001 Reset_Inhibit_Emergency_Valve 3 "Not Available" 2 "Invalid" 1 "On" 0 "Off" ;
VAL_ 2565854001 Speed_Standstill_Signal 3 "Not Available" 2 "Error" 1 "Standstill" 0 "Driving" ;
VAL_ 2565853745 Inhibit_Opening 3 "Not Available" 2 "Invalid" 1 "On" 0 "Off" ;
VAL_ 2565853745 Inhibit_Closing 3 "Not Available" 2 "Invalid" 1 "On" 0 "Off" ;
VAL_ 2565853745 Ignore_Outer_Sensitive_Edge 3 "Not Available" 2 "Invalid" 1 "Ignore" 0 "Don't ignore" ;
VAL_ 2565853745 Ignore_Light_Barrier 3 "Not Available" 2 "Invalid" 1 "Ignore" 0 "Don't ignore" ;
VAL_ 2565853745 Spare_Out_Request_7 3 "Not Available" 2 "Invalid" 1 "On" 0 "Off" ;
VAL_ 2565853745 Spare_Out_Request_5 3 "Not Available" 2 "Invalid" 1 "On" 0 "Off" ;
VAL_ 2565853745 Spare_Out_Request_4 3 "Not Available" 2 "Invalid" 1 "On" 0 "Off" ;
VAL_ 2565853745 Spare_Out_Request_3 3 "Not Available" 2 "Invalid" 1 "On" 0 "Off" ;
VAL_ 2565853745 Spare_Out_Request_2 3 "Not Available" 2 "Invalid" 1 "On" 0 "Off" ;
VAL_ 2565853745 Spare_Out_Request_6 3 "Not Available" 2 "Invalid" 1 "On" 0 "Off" ;
VAL_ 2565853745 Spare_Out_Request_8 3 "Not Available" 2 "Invalid" 1 "On" 0 "Off" ;
VAL_ 2565853745 Ignore_Speed_Obstruction 3 "Not Available" 2 "Invalid" 1 "Ignore" 0 "Don't ignore" ;
VAL_ 2565853745 Ignore_Sensitive_Edge 3 "Not Available" 2 "Invalid" 1 "Ignore" 0 "Don't ignore" ;
VAL_ 2565853745 Spare_Out_Request_1 3 "Not Available" 2 "Invalid" 1 "On" 0 "Off" ;
VAL_ 2565853745 Door_Position_Request_Right 250 "Fully Opened" 0 "Fully Closed" 253 "Invalid" 252 "Invalid" 251 "Invalid" 255 "Fully Opened/Closed" 254 "Invalid" ;
VAL_ 2565853745 Door_Position_Request_Left_Both 250 "Fully Opened" 0 "Fully Closed" 253 "Invalid" 252 "Invalid" 251 "Invalid" 255 "Fully Opened/Closed" 254 "Invalid" ;
VAL_ 2565853745 Right_Leaf_Command 15 "No Command" 14 "Invalid" 13 "Invalid" 12 "Invalid" 11 "Invalid" 10 "Invalid" 9 "Invalid" 8 "Invalid" 7 "Invalid" 6 "Invalid" 5 "Invalid" 4 "Invalid" 3 "Calibrate" 2 "Open" 1 "Close" 0 "Stop" ;
VAL_ 2565853745 Left_Leaf_Command 15 "No Command" 14 "Invalid" 13 "Invalid" 12 "Invalid" 11 "Invalid" 10 "Invalid" 9 "Invalid" 8 "Invalid" 7 "Invalid" 6 "Invalid" 5 "Invalid" 4 "Invalid" 3 "Calibrate" 2 "Open" 1 "Close" 0 "Stop" ;
VAL_ 2565853745 Buzzer 3 "Invalid" 2 "Auto" 1 "On" 0 "Off" ;
VAL_ 2565853745 Step_Lights 3 "Invalid" 2 "Auto" 1 "On" 0 "Off" ;
VAL_ 2565853745 Reset_Inhibit_Emergency_Valve 3 "Not Available" 2 "Invalid" 1 "On" 0 "Off" ;
VAL_ 2565853745 Speed_Standstill_Signal 3 "Not Available" 2 "Error" 1 "Standstill" 0 "Driving" ;
VAL_ 2565853489 Inhibit_Opening 3 "Not Available" 2 "Invalid" 1 "On" 0 "Off" ;
VAL_ 2565853489 Inhibit_Closing 3 "Not Available" 2 "Invalid" 1 "On" 0 "Off" ;
VAL_ 2565853489 Ignore_Outer_Sensitive_Edge 3 "Not Available" 2 "Invalid" 1 "Ignore" 0 "Don't ignore" ;
VAL_ 2565853489 Ignore_Light_Barrier 3 "Not Available" 2 "Invalid" 1 "Ignore" 0 "Don't ignore" ;
VAL_ 2565853489 Spare_Out_Request_7 3 "Not Available" 2 "Invalid" 1 "On" 0 "Off" ;
VAL_ 2565853489 Spare_Out_Request_5 3 "Not Available" 2 "Invalid" 1 "On" 0 "Off" ;
VAL_ 2565853489 Spare_Out_Request_4 3 "Not Available" 2 "Invalid" 1 "On" 0 "Off" ;
VAL_ 2565853489 Spare_Out_Request_3 3 "Not Available" 2 "Invalid" 1 "On" 0 "Off" ;
VAL_ 2565853489 Spare_Out_Request_2 3 "Not Available" 2 "Invalid" 1 "On" 0 "Off" ;
VAL_ 2565853489 Spare_Out_Request_6 3 "Not Available" 2 "Invalid" 1 "On" 0 "Off" ;
VAL_ 2565853489 Spare_Out_Request_8 3 "Not Available" 2 "Invalid" 1 "On" 0 "Off" ;
VAL_ 2565853489 Ignore_Speed_Obstruction 3 "Not Available" 2 "Invalid" 1 "Ignore" 0 "Don't ignore" ;
VAL_ 2565853489 Ignore_Sensitive_Edge 3 "Not Available" 2 "Invalid" 1 "Ignore" 0 "Don't ignore" ;
VAL_ 2565853489 Spare_Out_Request_1 3 "Not Available" 2 "Invalid" 1 "On" 0 "Off" ;
VAL_ 2565853489 Door_Position_Request_Right 250 "Fully Opened" 0 "Fully Closed" 253 "Invalid" 252 "Invalid" 251 "Invalid" 255 "Fully Opened/Closed" 254 "Invalid" ;
VAL_ 2565853489 Door_Position_Request_Left_Both 250 "Fully Opened" 0 "Fully Closed" 253 "Invalid" 252 "Invalid" 251 "Invalid" 255 "Fully Opened/Closed" 254 "Invalid" ;
VAL_ 2565853489 Right_Leaf_Command 15 "No Command" 14 "Invalid" 13 "Invalid" 12 "Invalid" 11 "Invalid" 10 "Invalid" 9 "Invalid" 8 "Invalid" 7 "Invalid" 6 "Invalid" 5 "Invalid" 4 "Invalid" 3 "Calibrate" 2 "Open" 1 "Close" 0 "Stop" ;
VAL_ 2565853489 Left_Leaf_Command 15 "No Command" 14 "Invalid" 13 "Invalid" 12 "Invalid" 11 "Invalid" 10 "Invalid" 9 "Invalid" 8 "Invalid" 7 "Invalid" 6 "Invalid" 5 "Invalid" 4 "Invalid" 3 "Calibrate" 2 "Open" 1 "Close" 0 "Stop" ;
VAL_ 2565853489 Buzzer 3 "Invalid" 2 "Auto" 1 "On" 0 "Off" ;
VAL_ 2565853489 Step_Lights 3 "Invalid" 2 "Auto" 1 "On" 0 "Off" ;
VAL_ 2565853489 Reset_Inhibit_Emergency_Valve 3 "Not Available" 2 "Invalid" 1 "On" 0 "Off" ;
VAL_ 2565853489 Speed_Standstill_Signal 3 "Not Available" 2 "Error" 1 "Standstill" 0 "Driving" ;
VAL_ 2566853885 Motor2sensorstatus 3 "Not available" 2 "Error" 1 "Motor 2 inside home sector" 0 "Motor 2 outside home sector" ;
VAL_ 2566853885 Motor1sensorstatus 3 "Not available" 2 "Error" 1 "Motor 1 inside home sector" 0 "Motor 1 outside home sector" ;
VAL_ 2566850855 CMS_DayNightSwitch 132 "Night" 120 "Dusk" 104 "Day" ;
VAL_ 2566851367 CO2SensorResponseError 3 "Not Available" 2 "Error" 1 "Error Active" 0 "No Error" ;
VAL_ 2566851367 CO2SensorReady 3 "Not Available" 2 "Error" 1 "Ready" 0 "Not Ready" ;
VAL_ 2566851367 CO2SensorInternalError 3 "Not Available" 2 "Error" 1 "Error Active" 0 "No Error" ;
VAL_ 2566889521 WWCUDoorOpen 1 "Open" 0 "Closed" ;
VAL_ 2566893337 SupplyWaterTempHP2 255 "Not Available" 254 "Error" ;
VAL_ 2566893337 SupplyWaterTempHP1 255 "Not Available" 254 "Error" ;
VAL_ 2566893337 String3HP2WaterTemp 255 "Not Available" 254 "Error" ;
VAL_ 2566893337 String3HP1WaterTemp 255 "Not Available" 254 "Error" ;
VAL_ 2566893337 String2HP2WaterTemp 255 "Not Available" 254 "Error" ;
VAL_ 2566893337 String2HP1WaterTemp 255 "Not Available" 254 "Error" ;
VAL_ 2566893337 String1HP2WaterTemp 255 "Not Available" 254 "Error" ;
VAL_ 2566893337 String1HP1WaterTemp 255 "Not Available" 254 "Error" ;
VAL_ 2566892081 InverterTemperature_HP2 255 "Not Available" 254 "Error" ;
VAL_ 2566892081 ActualPowerUsed_HP2 65280 "NOT_AVAILABLE" 65024 "ERROR" ;
VAL_ 2566892081 ActualInverterSpeed_HP2 65280 "NOT_AVAILABLE" 65024 "ERROR" ;
VAL_ 2566892081 InverterErrorState_HP2 3 "NOT_AVAILABLE" 2 "WARNING" 1 "ERROR" 0 "NO_ERROR" ;
VAL_ 2566892081 InverterReady_HP2 3 "NOT AVAILABLE" 2 "Reserved" 1 "READY" 0 "NOT READY" ;
VAL_ 2566892081 InverterState_HP2 3 "NOT AVAILABLE" 2 "ERROR" 1 "ENABLED" 0 "INHIBITED" ;
VAL_ 2566895897 InverterSpeedRequest_HP2 65280 "NOT_AVAILABLE" 65024 "ERROR" ;
VAL_ 2566895897 InverterSpeedRequest_HP1 65280 "NOT_AVAILABLE" 65024 "ERROR" ;
VAL_ 2566895897 InverterEnable_HP2 3 "NOT AVAILABLE" 2 "ERROR" 1 "ON" 0 "OFF" ;
VAL_ 2566895897 InverterEnable_HP1 3 "NOT AVAILABLE" 2 "ERROR" 1 "ON" 0 "OFF" ;
VAL_ 2566890545 ActualAverageBatteryTemp_S6 255 "NOT_AVAILABLE" 254 "ERROR" ;
VAL_ 2566890545 ActualAverageBatteryTemp_S5 255 "NOT_AVAILABLE" 254 "ERROR" ;
VAL_ 2566890545 ActualAverageBatteryTemp_S4 255 "NOT_AVAILABLE" 254 "ERROR" ;
VAL_ 2566890545 BatteryTempSetpointHigh 255 "NOT_AVAILABLE" 254 "ERROR" ;
VAL_ 2566890545 ActualAverageBatteryTemp_S3 255 "NOT_AVAILABLE" 254 "ERROR" ;
VAL_ 2566890545 ActualAverageBatteryTemp_S2 255 "NOT_AVAILABLE" 254 "ERROR" ;
VAL_ 2566890545 ActualAverageBatteryTemp_S1 255 "NOT_AVAILABLE" 254 "ERROR" ;
VAL_ 2566890545 BatteryTempSetpointLow 255 "NOT_AVAILABLE" 254 "ERROR" ;
VAL_ 2566893593 ReheatOn_ACT 3 "NOT AVAILABLE" 2 "ERROR" 1 "ON" 0 "OFF" ;
VAL_ 2566893593 ACDriverOn_ACT 3 "NOT AVAILABLE" 2 "ERROR" 1 "ON" 0 "OFF" ;
VAL_ 2566893593 ActualDriverRecFlapPos 255 "NOT_AVAILABLE" 254 "ERROR" ;
VAL_ 2566893593 ActualDriverAirDist 255 "NOT_AVAILABLE" 254 "ERROR" ;
VAL_ 2566893593 FrontBoxMode_ACT 7 "MODE_NOT_AVAILABLE" 6 "MODE_ERROR" 5 "RESERVED" 4 "RESERVED" 3 "MODE_DEFROST" 2 "MODE_AUTOMATIC" 1 "MODE_MANUAL" 0 "MODE_OFF" ;
VAL_ 2566893593 ActualDriverBlowerSpeed 255 "NOT_AVAILABLE" 254 "ERROR" ;
VAL_ 2566893593 ActualDriverTemp 255 "NOT_AVAILABLE" 254 "ERROR" ;
VAL_ 2566893593 SystemMode 15 "NOT AVAILABLE" 14 "ERROR" 13 "COOLANT FILL MODE" 12 "AC FILL MODE AC ON" 11 "AC FILL MODE AC OFF" 10 "SW TEST MODE" 9 "HW TEST MODE" 8 "RESERVED" 7 "RESERVED" 6 "DEICE ON" 5 "PRECONDITION MODE" 4 "COIL DRY MODE" 3 "HEAT MODE" 2 "AC MODE" 1 "STANDBY MODE" 0 "OFF MODE" ;
VAL_ 2566891825 InverterTemperature_HP1 255 "Not Available" 254 "Error" ;
VAL_ 2566891825 ActualPowerUsed_HP1 65280 "NOT_AVAILABLE" 65024 "ERROR" ;
VAL_ 2566891825 ActualInverterSpeed_HP1 65280 "NOT_AVAILABLE" 65024 "ERROR" ;
VAL_ 2566891825 InverterState_HP1 3 "NOT AVAILABLE" 2 "ERROR" 1 "ENABLED" 0 "INHIBITED" ;
VAL_ 2566891825 InverterErrorState_HP1 3 "NOT_AVAILABLE" 2 "WARNING" 1 "ERROR" 0 "NO_ERROR" ;
VAL_ 2566891825 InverterReady_HP1 3 "NOT AVAILABLE" 2 "Reserved" 1 "READY" 0 "NOT READY" ;
VAL_ 2566891569 BatteryClimateEnable_6 3 "NOT AVAILABLE" 2 "ERROR" 1 "ENABLED" 0 "NOT ENABLED" ;
VAL_ 2566891569 BatteryClimateEnable_5 3 "NOT AVAILABLE" 2 "ERROR" 1 "ENABLED" 0 "NOT ENABLED" ;
VAL_ 2566891569 BatteryClimateEnable_4 3 "NOT AVAILABLE" 2 "ERROR" 1 "ENABLED" 0 "NOT ENABLED" ;
VAL_ 2566891569 ActualHighVoltageMeasured 255 "NOT_AVAILABLE" 254 "ERROR" ;
VAL_ 2566891569 BatteryClimateEnable_3 3 "NOT AVAILABLE" 2 "ERROR" 1 "ENABLED" 0 "NOT ENABLED" ;
VAL_ 2566891569 BatteryClimateEnable_2 3 "NOT AVAILABLE" 2 "ERROR" 1 "ENABLED" 0 "NOT ENABLED" ;
VAL_ 2566891569 BatteryClimateEnable_1 3 "NOT AVAILABLE" 2 "ERROR" 1 "ENABLED" 0 "NOT ENABLED" ;
VAL_ 2566891569 ActualMinBatteryTemperature 255 "NOT_AVAILABLE" 254 "ERROR" ;
VAL_ 2566891569 ActualMaxBatteryTemp 255 "NOT_AVAILABLE" 254 "ERROR" ;
VAL_ 2566891569 BatterySlowCharging 3 "NOT AVAILABLE" 2 "ERROR" 1 "Enabled" 0 "Not Enabled" ;
VAL_ 2566891569 BatteryMinTemp 255 "NOT_AVAILABLE" 254 "ERROR" ;
VAL_ 2566891569 BatteryMaxTemp 255 "NOT_AVAILABLE" 254 "ERROR" ;
VAL_ 2566891569 BatteryFastCharging 3 "NOT AVAILABLE" 2 "ERROR" 1 "ENABLED" 0 "NOT ENABLED" ;
VAL_ 2566891569 BatteryClimateEnableMaster 3 "NOT AVAILABLE" 2 "ERROR" 1 "ENABLED" 0 "NOT ENABLED" ;
VAL_ 2566891313 H2OFillModeRequest_REQ 15 "Not Available" 14 "Error" 13 "Reserved" 12 "Reserved" 11 "Reserved" 10 "Reserved" 9 "Reserved" 8 "Battery Partial Filling HP2" 7 "Battery Partial Filling HP1" 6 "Partial Filling" 5 "Reserved" 4 "Complete Fill Test" 3 "Battery Complete Filling HP2" 2 "Battery Complete Filling HP1" 1 "Complete Filling" 0 "Non Selected" ;
VAL_ 2566891313 CabinBlowerAdjust 255 "NOT_AVAILABLE" 254 "ERROR" ;
VAL_ 2566891313 SetCabinSetpointZ2 255 "NOT_AVAILABLE" 254 "ERROR" ;
VAL_ 2566891313 SetCabinSetpointZ1 255 "NOT_AVAILABLE" 254 "ERROR" ;
VAL_ 2566891313 SetInteriorFreshAirRequest 255 "NOT_AVAILABLE" 254 "ERROR" ;
VAL_ 2566891313 SetCabinSetpointZ3 255 "NOT_AVAILABLE" 254 "ERROR" ;
VAL_ 2566894105 CANMatrixUsed 8 "V13" 7 "V12" 6 "V11" 5 "V10" 4 "V9" 3 "V8" 2 "V7" 1 "V6" 0 "V5" ;
VAL_ 2566894105 CabinCO2Value 65280 "NOT_AVAILABLE" 65024 "ERROR" ;
VAL_ 2566894105 COPTotal 255 "NOT_AVAILABLE" 254 "ERROR" ;
VAL_ 2566894105 COPRefrigerent 255 "NOT_AVAILABLE" 254 "ERROR" ;
VAL_ 2566894105 WaterTemperature 255 "NOT_AVAILABLE" 254 "ERROR" ;
VAL_ 2566894105 LowVoltageVoltageValue 255 "NOT_AVAILABLE" 254 "ERROR" ;
VAL_ 2566894105 LowVoltagePowerUsage 255 "NOT_AVAILABLE" 254 "ERROR" ;
VAL_ 2566891057 ReheatOn_REQ 3 "NOT AVAILABLE" 2 "ERROR" 1 "ON" 0 "OFF" ;
VAL_ 2566891057 ACDriverOn_REQ 3 "NOT AVAILABLE" 2 "ERROR" 1 "ON" 0 "OFF" ;
VAL_ 2566891057 SetBlowerDriverSpeed 255 "NOT_AVAILABLE" 254 "ERROR" ;
VAL_ 2566891057 SetDriverRecirculation 255 "NOT_AVAILABLE" 254 "ERROR" ;
VAL_ 2566891057 SetDriverAirDistribution 255 "NOT_AVAILABLE" 254 "ERROR" ;
VAL_ 2566891057 SetDriverTempSetpoint 255 "NOT_AVAILABLE" 254 "ERROR" ;
VAL_ 2566891057 FrontBoxMode_REQ 7 "MODE_NOT_AVAILABLE" 6 "MODE_ERROR" 5 "RESERVED" 4 "RESERVED" 3 "MODE_DEFROST" 2 "MODE_AUTOMATIC" 1 "MODE_MANUAL" 0 "MODE_OFF" ;
VAL_ 2566890801 AmbientLimitOverwrite 3 "Not Available" 2 "Error" 1 "Enabled" 0 "Disabled" ;
VAL_ 2566890801 AuxHeatSelection 7 "Not Available" 6 "Error" 5 "HV Heaters + Diesel Heater" 4 "Diesel Heater" 3 "HV Heaters" 2 "Heat Pump + Diesel Heater" 1 "Heat Pump + HV Heaters" 0 "Heat Pump" ;
VAL_ 2566890801 PowerReductionRateBat 15 "Not available" 14 "Error" 13 "Reserved" 12 "Reserved" 11 "Reserved" 10 "OFF" 9 "Reduction of 90%" 8 "Reduction of 80%" 7 "Reduction of 70%" 6 "Reduction of 60%" 5 "Reduction of 50%" 4 "Reduction of 40%" 3 "Reduction of 30%" 2 "Reduction of 20%" 1 "Reduction of 10%" 0 "No reduction (0%)" ;
VAL_ 2566890801 AuxHeaterActualTemp 255 "NOT_AVAILABLE" 254 "ERROR" ;
VAL_ 2566890801 Preconditioning 3 "NOT AVAILABLE" 2 "ERROR" 1 "ON" 0 "OFF" ;
VAL_ 2566890801 PTCEnable 3 "NOT AVAILABLE" 2 "ERROR" 1 "ON" 0 "OFF" ;
VAL_ 2566890801 TractionHeatMinimum 255 "NOT_AVAILABLE" 254 "ERROR" ;
VAL_ 2566890801 Door4Status 3 "NOT AVAILABLE" 2 "RESERVED" 1 "OPEN" 0 "CLOSED" ;
VAL_ 2566890801 Door3Status 3 "NOT AVAILABLE" 2 "RESERVED" 1 "OPEN" 0 "CLOSED" ;
VAL_ 2566890801 Door2Status 3 "NOT AVAILABLE" 2 "RESERVED" 1 "OPEN" 0 "CLOSED" ;
VAL_ 2566890801 Door1Status 3 "NOT AVAILABLE" 2 "RESERVED" 1 "OPEN" 0 "CLOSED" ;
VAL_ 2566890801 PowerReductionRateDriver 15 "Not available" 14 "Error" 13 "Reserved" 12 "Reserved" 11 "Reserved" 10 "OFF" 9 "Reduction of 90%" 8 "Reduction of 80%" 7 "Reduction of 70%" 6 "Reduction of 60%" 5 "Reduction of 50%" 4 "Reduction of 40%" 3 "Reduction of 30%" 2 "Reduction of 20%" 1 "Reduction of 10%" 0 "No reduction (0%)" ;
VAL_ 2566890801 PowerReductionRateInterior 15 "Not available" 14 "Error" 13 "Reserved" 12 "Reserved" 11 "Reserved" 10 "OFF" 9 "Reduction of 90%" 8 "Reduction of 80%" 7 "Reduction of 70%" 6 "Reduction of 60%" 5 "Reduction of 50%" 4 "Reduction of 40%" 3 "Reduction of 30%" 2 "Reduction of 20%" 1 "Reduction of 10%" 0 "No reduction (0%)" ;
VAL_ 2566890801 PowerReductionRateHV 15 "Not available" 14 "Error" 13 "Reserved" 12 "Reserved" 11 "Reserved" 10 "OFF" 9 "Reduction of 90%" 8 "Reduction of 80%" 7 "Reduction of 70%" 6 "Reduction of 60%" 5 "Reduction of 50%" 4 "Reduction of 40%" 3 "Reduction of 30%" 2 "Reduction of 20%" 1 "Reduction of 10%" 0 "No reduction (0%)" ;
VAL_ 2566890801 AuxHeatActivation 3 "NOT AVAILABLE" 2 "ERROR" 1 "ON" 0 "OFF" ;
VAL_ 2566890801 TractionHeatEnable 3 "NOT AVAILABLE" 2 "ERROR" 1 "ON" 0 "OFF" ;
VAL_ 2566890801 DriveReady 3 "NOT AVAILABLE" 2 "ERROR" 1 "ON" 0 "OFF" ;
VAL_ 2566890801 EngineRunning 3 "NOT AVAILABLE" 2 "ERROR" 1 "ON" 0 "OFF" ;
VAL_ 2566890801 Ignition 3 "NOT AVAILABLE" 2 "ERROR" 1 "ON" 0 "OFF" ;
VAL_ 2566890801 MainSwitch 3 "NOT AVAILABLE" 2 "ERROR" 1 "ON" 0 "OFF" ;
VAL_ 2566893849 FillingDone 3 "Not Available" 2 "Error" 1 "Done" 0 "Not Done" ;
VAL_ 2566893849 H2OFillModeRequest_ACT 15 "Not Available" 14 "Error" 13 "Reserved" 12 "Reserved" 11 "Reserved" 10 "Reserved" 9 "Reserved" 8 "Battery Partial Filling HP2" 7 "Battery Partial Filling HP1" 6 "Partial Filling" 5 "Reserved" 4 "Complete Fill Test" 3 "Battery Complete Filling HP2" 2 "Battery Complete Filling HP1" 1 "Complete Filling" 0 "Non Selected" ;
VAL_ 2566893849 AuxHeaterTempRequest 255 "NOT_AVAILABLE" 254 "ERROR" ;
VAL_ 2566893849 FlowSwitchStatus 3 "NOT AVAILABLE" 2 "ERROR" 1 "ON" 0 "OFF" ;
VAL_ 2566893849 AuxPumpRequest 3 "NOT AVAILABLE" 2 "ERROR" 1 "ON" 0 "OFF" ;
VAL_ 2566893849 PTCStatus 3 "NOT AVAILABLE" 2 "ERROR" 1 "ON" 0 "OFF" ;
VAL_ 2566893849 TractionTemperature 255 "NOT_AVAILABLE" 254 "ERROR" ;
VAL_ 2566893849 AmbientTemperature 255 "NOT_AVAILABLE" 254 "ERROR" ;
VAL_ 2566893849 HPUnit2On 3 "NOT AVAILABLE" 2 "ERROR" 1 "ON" 0 "OFF" ;
VAL_ 2566893849 HPUnit1On 3 "NOT AVAILABLE" 2 "ERROR" 1 "ON" 0 "OFF" ;
VAL_ 2566893849 TractionHeatRequest 3 "NOT AVAILABLE" 2 "ERROR" 1 "ON" 0 "OFF" ;
VAL_ 2566893849 AuxHeatRequest 3 "NOT AVAILABLE" 2 "ERROR" 1 "ON" 0 "OFF" ;
VAL_ 2566893849 HVRequest 3 "NOT AVAILABLE" 2 "ERROR" 1 "ON" 0 "OFF" ;
VAL_ 2566893849 SystemOn 3 "NOT AVAILABLE" 2 "ERROR" 1 "ON" 0 "OFF" ;
VAL_ 2566894873 ActualAverageCabin4Temp 255 "NOT_AVAILABLE" 254 "ERROR" ;
VAL_ 2566894873 ActualAverageCabin3Temp 255 "NOT_AVAILABLE" 254 "ERROR" ;
VAL_ 2566894873 ActualAverageCabin2Temp 255 "NOT_AVAILABLE" 254 "ERROR" ;
VAL_ 2566894873 ActualCabinFreshAirIntake 255 "NOT_AVAILABLE" 254 "ERROR" ;
VAL_ 2566894873 ActualAverageCabinBlowerSpeed 255 "NOT_AVAILABLE" 254 "ERROR" ;
VAL_ 2566894873 ActualAverageCabin1Temp 255 "NOT_AVAILABLE" 254 "ERROR" ;
VAL_ 2566834941 FailureModeIdentifier5 31 "Not available" 19 "Received network data in error" 18 "Below normal (moderatels severe)" 17 "Below normal (least severe)" 16 "Above normal (moderately severe)" 15 "Above normal (least severe)" 14 "Special intstructions" 13 "Out of calibration" 12 "Bad intelligent device" 11 "Root cause not known" 10 "Abnormal rate of change" 9 "Abnormal update rate" 8 "Abnormal frequency" 7 "Mechanical system not responding" 6 "Current above normal" 5 "Current below normal" 4 "Voltage below normal" 3 "Voltage above normal" 2 "Data erratic" 1 "Below normal (most severe)" 0 "Above normal (most severe)" ;
VAL_ 2566834941 FailureModeIdentifier4 31 "Not available" 19 "Received network data in error" 18 "Below normal (moderatels severe)" 17 "Below normal (least severe)" 16 "Above normal (moderately severe)" 15 "Above normal (least severe)" 14 "Special intstructions" 13 "Out of calibration" 12 "Bad intelligent device" 11 "Root cause not known" 10 "Abnormal rate of change" 9 "Abnormal update rate" 8 "Abnormal frequency" 7 "Mechanical system not responding" 6 "Current above normal" 5 "Current below normal" 4 "Voltage below normal" 3 "Voltage above normal" 2 "Data erratic" 1 "Below normal (most severe)" 0 "Above normal (most severe)" ;
VAL_ 2566834941 FailureModeIdentifier3 31 "Not available" 19 "Received network data in error" 18 "Below normal (moderatels severe)" 17 "Below normal (least severe)" 16 "Above normal (moderately severe)" 15 "Above normal (least severe)" 14 "Special intstructions" 13 "Out of calibration" 12 "Bad intelligent device" 11 "Root cause not known" 10 "Abnormal rate of change" 9 "Abnormal update rate" 8 "Abnormal frequency" 7 "Mechanical system not responding" 6 "Current above normal" 5 "Current below normal" 4 "Voltage below normal" 3 "Voltage above normal" 2 "Data erratic" 1 "Below normal (most severe)" 0 "Above normal (most severe)" ;
VAL_ 2566834941 FailureModeIdentifier2 31 "Not available" 19 "Received network data in error" 18 "Below normal (moderatels severe)" 17 "Below normal (least severe)" 16 "Above normal (moderately severe)" 15 "Above normal (least severe)" 14 "Special intstructions" 13 "Out of calibration" 12 "Bad intelligent device" 11 "Root cause not known" 10 "Abnormal rate of change" 9 "Abnormal update rate" 8 "Abnormal frequency" 7 "Mechanical system not responding" 6 "Current above normal" 5 "Current below normal" 4 "Voltage below normal" 3 "Voltage above normal" 2 "Data erratic" 1 "Below normal (most severe)" 0 "Above normal (most severe)" ;
VAL_ 2566834941 FailureModeIdentifier1 31 "Not available" 19 "Received network data in error" 18 "Below normal (moderatels severe)" 17 "Below normal (least severe)" 16 "Above normal (moderately severe)" 15 "Above normal (least severe)" 14 "Special intstructions" 13 "Out of calibration" 12 "Bad intelligent device" 11 "Root cause not known" 10 "Abnormal rate of change" 9 "Abnormal update rate" 8 "Abnormal frequency" 7 "Mechanical system not responding" 6 "Current above normal" 5 "Current below normal" 4 "Voltage below normal" 3 "Voltage above normal" 2 "Data erratic" 1 "Below normal (most severe)" 0 "Above normal (most severe)" ;
VAL_ 2566834941 FlashMalfuncIndicatorLamp 3 "Unavailable / Do Not Flash" 2 "Reserved" 1 "Fast Flash" 0 "Slow Flash" ;
VAL_ 2566834941 FlashRedStopLamp 3 "Unavailable / Do Not Flash" 2 "Reserved" 1 "Fast Flash" 0 "Slow Flash" ;
VAL_ 2566834941 FlashAmberWarningLamp 3 "Unavailable / Do Not Flash" 2 "Reserved" 1 "Fast Flash" 0 "Slow Flash" ;
VAL_ 2566834941 FlashProtectLamp 3 "Unavailable / Do Not Flash" 2 "Reserved" 1 "Fast Flash" 0 "Slow Flash" ;
VAL_ 2566834941 MalfunctionIndicatorLampStatus 3 "Not available" 2 "Reserved" 1 "Lamp on" 0 "Lamp off" ;
VAL_ 2566834941 RedStopLampState 3 "Not available" 2 "Reserved" 1 "Lamp on" 0 "Lamp off" ;
VAL_ 2566834941 AmberWarningLampStatus 3 "Not available" 2 "Reserved" 1 "Lamp on" 0 "Lamp off" ;
VAL_ 2566834941 ProtectLampStatus 3 "Not available" 2 "Reserved" 1 "Lamp on" 0 "Lamp off" ;
VAL_ 2566834713 FailureModeIdentifier5 31 "Not available" 19 "Received network data in error" 18 "Below normal (moderatels severe)" 17 "Below normal (least severe)" 16 "Above normal (moderately severe)" 15 "Above normal (least severe)" 14 "Special intstructions" 13 "Out of calibration" 12 "Bad intelligent device" 11 "Root cause not known" 10 "Abnormal rate of change" 9 "Abnormal update rate" 8 "Abnormal frequency" 7 "Mechanical system not responding" 6 "Current above normal" 5 "Current below normal" 4 "Voltage below normal" 3 "Voltage above normal" 2 "Data erratic" 1 "Below normal (most severe)" 0 "Above normal (most severe)" ;
VAL_ 2566834713 FailureModeIdentifier4 31 "Not available" 19 "Received network data in error" 18 "Below normal (moderatels severe)" 17 "Below normal (least severe)" 16 "Above normal (moderately severe)" 15 "Above normal (least severe)" 14 "Special intstructions" 13 "Out of calibration" 12 "Bad intelligent device" 11 "Root cause not known" 10 "Abnormal rate of change" 9 "Abnormal update rate" 8 "Abnormal frequency" 7 "Mechanical system not responding" 6 "Current above normal" 5 "Current below normal" 4 "Voltage below normal" 3 "Voltage above normal" 2 "Data erratic" 1 "Below normal (most severe)" 0 "Above normal (most severe)" ;
VAL_ 2566834713 FailureModeIdentifier3 31 "Not available" 19 "Received network data in error" 18 "Below normal (moderatels severe)" 17 "Below normal (least severe)" 16 "Above normal (moderately severe)" 15 "Above normal (least severe)" 14 "Special intstructions" 13 "Out of calibration" 12 "Bad intelligent device" 11 "Root cause not known" 10 "Abnormal rate of change" 9 "Abnormal update rate" 8 "Abnormal frequency" 7 "Mechanical system not responding" 6 "Current above normal" 5 "Current below normal" 4 "Voltage below normal" 3 "Voltage above normal" 2 "Data erratic" 1 "Below normal (most severe)" 0 "Above normal (most severe)" ;
VAL_ 2566834713 FailureModeIdentifier2 31 "Not available" 19 "Received network data in error" 18 "Below normal (moderatels severe)" 17 "Below normal (least severe)" 16 "Above normal (moderately severe)" 15 "Above normal (least severe)" 14 "Special intstructions" 13 "Out of calibration" 12 "Bad intelligent device" 11 "Root cause not known" 10 "Abnormal rate of change" 9 "Abnormal update rate" 8 "Abnormal frequency" 7 "Mechanical system not responding" 6 "Current above normal" 5 "Current below normal" 4 "Voltage below normal" 3 "Voltage above normal" 2 "Data erratic" 1 "Below normal (most severe)" 0 "Above normal (most severe)" ;
VAL_ 2566834713 FailureModeIdentifier1 31 "Not available" 19 "Received network data in error" 18 "Below normal (moderatels severe)" 17 "Below normal (least severe)" 16 "Above normal (moderately severe)" 15 "Above normal (least severe)" 14 "Special intstructions" 13 "Out of calibration" 12 "Bad intelligent device" 11 "Root cause not known" 10 "Abnormal rate of change" 9 "Abnormal update rate" 8 "Abnormal frequency" 7 "Mechanical system not responding" 6 "Current above normal" 5 "Current below normal" 4 "Voltage below normal" 3 "Voltage above normal" 2 "Data erratic" 1 "Below normal (most severe)" 0 "Above normal (most severe)" ;
VAL_ 2566834713 FlashMalfuncIndicatorLamp 3 "Unavailable / Do Not Flash" 2 "Reserved" 1 "Fast Flash" 0 "Slow Flash" ;
VAL_ 2566834713 FlashRedStopLamp 3 "Unavailable / Do Not Flash" 2 "Reserved" 1 "Fast Flash" 0 "Slow Flash" ;
VAL_ 2566834713 FlashAmberWarningLamp 3 "Unavailable / Do Not Flash" 2 "Reserved" 1 "Fast Flash" 0 "Slow Flash" ;
VAL_ 2566834713 FlashProtectLamp 3 "Unavailable / Do Not Flash" 2 "Reserved" 1 "Fast Flash" 0 "Slow Flash" ;
VAL_ 2566834713 MalfunctionIndicatorLampStatus 3 "Not available" 2 "Reserved" 1 "Lamp on" 0 "Lamp off" ;
VAL_ 2566834713 RedStopLampState 3 "Not available" 2 "Reserved" 1 "Lamp on" 0 "Lamp off" ;
VAL_ 2566834713 AmberWarningLampStatus 3 "Not available" 2 "Reserved" 1 "Lamp on" 0 "Lamp off" ;
VAL_ 2566834713 ProtectLampStatus 3 "Not available" 2 "Reserved" 1 "Lamp on" 0 "Lamp off" ;
VAL_ 2566769969 RearWasherFunction 7 "NotAvailable" 4 "110Reserved" 3 "High" 2 "Medium" 1 "Low" 0 "Off" ;
VAL_ 2566769969 FrontOperatorWasherSwitch 7 "NotAvailable" 4 "110Reserved" 3 "High" 2 "Medium" 1 "Low" 0 "Off" ;
VAL_ 2566769969 FrontNonoperatorWasherSwitch 7 "NotAvailable" 4 "110Reserved" 3 "High" 2 "Medium" 1 "Low" 0 "Off" ;
VAL_ 2566769969 RearWiperSwitch 7 "1110Reserved" 6 "Mist" 5 "Delayed2" 4 "Delayed1" 2 "Medium" 15 "NotAvailable" 3 "High" 1 "Low" 0 "Off" ;
VAL_ 2566769969 FrontOperatorWiperSwitch 7 "1110Reserved" 6 "Mist" 5 "Delayed2" 4 "Delayed1" 2 "Medium" 15 "NotAvailable" 3 "High" 1 "Low" 0 "Off" ;
VAL_ 2566769969 FrontNonoperatorWiperSwitch 7 "1110Reserved" 6 "Mist" 5 "Delayed2" 4 "Delayed1" 2 "Medium" 15 "NotAvailable" 3 "High" 1 "Low" 0 "Off" ;
VAL_ 2561271857 LaneDepartureWarningEnableCmd 3 "DonTCare" 2 "Reserved" 1 "EnableLaneDepartureWarning" 0 "DisableLaneDepartureWarning" ;
VAL_ 2365443121 HighLowBeamSwitch 3 "NotAvailable" 2 "Error" 1 "HighBeamSelected" 0 "LowBeamSelected" ;
VAL_ 2365443121 HazardLightSwitch 3 "NotAvailable" 2 "Error" 1 "HazardLampsToBeFlashing" 0 "HazardLampsToBeOff" ;
VAL_ 2365443121 TurnSignalSwitch 2 "RightTurnToBeFlashing" 15 "NotAvailable" 14 "Error" 3 "1101Reserved" 1 "LeftTurnToBeFlashing" 0 "NoTurnBeingSignaled" ;
VAL_ 2365443121 MainLightSwitch 9 "1101Reserved" 8 "DlydOffPsByWhchThOprtrSlctsThtA" 4 "0111Reserved" 2 "HdlghtOnPsByWhchThOprtrSlctsTht" 15 "NotAvailable" 14 "Error" 3 "HdlghtAndPrkOnPsByWhchThOprtrSl" 1 "PrkOnPsByWhchThOprtrSlctsThtThP" 0 "OffPsByWhchThOprtrSlctsThtNnOfT" ;
VAL_ 2365443121 WorkLightSwitch 5 "1101Reserved" 4 "WrkLghtCmbntn4OnPsByWhchThOprtr" 2 "WrkLghtCmbntn2OnPsByWhchThOprtr" 15 "NotAvailable" 14 "Error" 3 "WrkLghtCmbntn3OnPsByWhchThOprtr" 1 "WrkLghtCmbntn1OnPsByWhchThOprtr" 0 "OffPsByWhchThOprtrSlctsThtNnOfT" ;
VAL_ 2566853399 Set_Alarm_Enable 3 "Not available" 2 "Error" 1 "On" 0 "Off" ;
VAL_ 2566806504 ForwardLaneImagerStatus 14 "Error" 5 "Imagerviewdegradedbutfunctional" 3 "Imager fully blocked" 2 "Imager partially blocked" ;
VAL_ 2566806504 LaneDepartureWarningSystemState 14 "Error" ;
VAL_ 2566806504 LnDprtureIndicationEnableStatus 3 "NotUsed" 2 "Reserved" 1 "LaneDepartureIndicationEnabled" 0 "LaneDepartureIndicationDisabled" ;
VAL_ 2566806504 LaneTrackingStatusLeftSide 3 "DontCare_TakeNoAction" 2 "Reserved" 1 "TrackingLeftSide" 0 "NotTrackingLeftSide" ;
VAL_ 2566806504 LaneTrackingStatusRightSide 3 "DontCare_TakeNoAction" 2 "Reserved" 1 "TrackingRightSide" 0 "NotTrackingRightSide" ;
VAL_ 2431649768 LaneDepartureImminentLeftSide 3 "NotUsed" 2 "Reserved" 1 "Imminent" 0 "NotImminent" ;
VAL_ 2431649768 LaneDepartureImminentRightSide 3 "NotUsed" 2 "Reserved" 1 "Imminent" 0 "NotImminent" ;
VAL_ 2566896268 Auxiliary_IO_65 3 "Not Available" 2 "Error" 1 "Active" 0 "Inactive" ;
VAL_ 2566896268 Auxiliary_IO_64 3 "Not Available" 2 "Error" 1 "Active" 0 "Inactive" ;
VAL_ 2566896268 Auxiliary_IO_63 3 "Not Available" 2 "Error" 1 "Active" 0 "Inactive" ;
VAL_ 2566896268 Auxiliary_IO_62 3 "Not Available" 2 "Error" 1 "Active" 0 "Inactive" ;
VAL_ 2566896268 Auxiliary_IO_61 3 "Not Available" 2 "Error" 1 "Active" 0 "Inactive" ;
VAL_ 2566896268 Auxiliary_IO_60 3 "Not Available" 2 "Error" 1 "Active" 0 "Inactive" ;
VAL_ 2566896268 Auxiliary_IO_59 3 "Not Available" 2 "Error" 1 "Active" 0 "Inactive" ;
VAL_ 2566896268 Auxiliary_IO_58 3 "Not Available" 2 "Error" 1 "Active" 0 "Inactive" ;
VAL_ 2566896268 Auxiliary_IO_56 3 "Not Available" 2 "Error" 1 "Active" 0 "Inactive" ;
VAL_ 2566896268 Auxiliary_IO_54 3 "Not Available" 2 "Error" 1 "Active" 0 "Inactive" ;
VAL_ 2566896268 Auxiliary_IO_53 3 "Not Available" 2 "Error" 1 "Active" 0 "Inactive" ;
VAL_ 2566896268 Auxiliary_IO_52 3 "Not Available" 2 "Error" 1 "Active" 0 "Inactive" ;
VAL_ 2566896268 Auxiliary_IO_51 3 "Not Available" 2 "Error" 1 "Active" 0 "Inactive" ;
VAL_ 2566896268 Auxiliary_IO_50 3 "Not Available" 2 "Error" 1 "Active" 0 "Inactive" ;
VAL_ 2566896268 Auxiliary_IO_49 3 "Not Available" 2 "Error" 1 "Active" 0 "Inactive" ;
VAL_ 2566873740 Auxiliary_IO_32 3 "Not Available" 2 "Error" 1 "Active" 0 "Inactive" ;
VAL_ 2566873740 Auxiliary_IO_31 3 "Not Available" 2 "Error" 1 "Active" 0 "Inactive" ;
VAL_ 2566873740 Auxiliary_IO_30 3 "Not Available" 2 "Error" 1 "Active" 0 "Inactive" ;
VAL_ 2566873740 Auxiliary_IO_29 3 "Not Available" 2 "Error" 1 "Active" 0 "Inactive" ;
VAL_ 2566873740 Auxiliary_IO_28 3 "Not Available" 2 "Error" 1 "Active" 0 "Inactive" ;
VAL_ 2566873740 Auxiliary_IO_27 3 "Not Available" 2 "Error" 1 "Active" 0 "Inactive" ;
VAL_ 2566873740 Auxiliary_IO_26 3 "Not Available" 2 "Error" 1 "Active" 0 "Inactive" ;
VAL_ 2566873740 Auxiliary_IO_25 3 "Not Available" 2 "Error" 1 "Active" 0 "Inactive" ;
VAL_ 2566873740 Auxiliary_IO_24 3 "Not Available" 2 "Error" 1 "Active" 0 "Inactive" ;
VAL_ 2566873740 Auxiliary_IO_23 3 "Not Available" 2 "Error" 1 "Active" 0 "Inactive" ;
VAL_ 2566873740 Auxiliary_IO_22 3 "Not Available" 2 "Error" 1 "Active" 0 "Inactive" ;
VAL_ 2566873740 Auxiliary_IO_21 3 "Not Available" 2 "Error" 1 "Active" 0 "Inactive" ;
VAL_ 2566873740 Auxiliary_IO_20 3 "Not Available" 2 "Error" 1 "Active" 0 "Inactive" ;
VAL_ 2566873740 Auxiliary_IO_19 3 "Not Available" 2 "Error" 1 "Active" 0 "Inactive" ;
VAL_ 2566873740 Auxiliary_IO_18 3 "Not Available" 2 "Error" 1 "Active" 0 "Inactive" ;
VAL_ 2566873740 Auxiliary_IO_17 3 "Not Available" 2 "Error" 1 "Active" 0 "Inactive" ;
VAL_ 2561015629 Auxiliary_IO_96 3 "Not Available" 2 "Error" 1 "Active" 0 "Inactive" ;
VAL_ 2561015629 Auxiliary_IO_93 3 "Not Available" 2 "Error" 1 "Active" 0 "Inactive" ;
VAL_ 2561015629 Auxiliary_IO_98 3 "Not Available" 2 "Error" 1 "Active" 0 "Inactive" ;
VAL_ 2561015629 Auxiliary_IO_99 3 "Not Available" 2 "Error" 1 "Active" 0 "Inactive" ;
VAL_ 2561015629 Auxiliary_IO_100 3 "Not Available" 2 "Error" 1 "Active" 0 "Inactive" ;
VAL_ 2561015629 Auxiliary_IO_95 3 "Not Available" 2 "Error" 1 "Active" 0 "Inactive" ;
VAL_ 2561015629 Auxiliary_IO_94 3 "Not Available" 2 "Error" 1 "Active" 0 "Inactive" ;
VAL_ 2561015629 Auxiliary_IO_92 3 "Not Available" 2 "Error" 1 "Active" 0 "Inactive" ;
VAL_ 2561015629 Auxiliary_IO_91 3 "Not Available" 2 "Error" 1 "Active" 0 "Inactive" ;
VAL_ 2561015629 Auxiliary_IO_90 3 "Not Available" 2 "Error" 1 "Active" 0 "Inactive" ;
VAL_ 2561015629 Auxiliary_IO_89 3 "Not Available" 2 "Error" 1 "Active" 0 "Inactive" ;
VAL_ 2561015629 Auxiliary_IO_88 3 "Not Available" 2 "Error" 1 "Active" 0 "Inactive" ;
VAL_ 2561015629 Auxiliary_IO_87 3 "Not Available" 2 "Error" 1 "Active" 0 "Inactive" ;
VAL_ 2561015629 Auxiliary_IO_86 3 "Not Available" 2 "Error" 1 "Active" 0 "Inactive" ;
VAL_ 2561015629 Auxiliary_IO_85 3 "Not Available" 2 "Error" 1 "Active" 0 "Inactive" ;
VAL_ 2561015629 Auxiliary_IO_81 3 "Not Available" 2 "Error" 1 "Active" 0 "Inactive" ;
VAL_ 2561015629 Auxiliary_IO_82 3 "Not Available" 2 "Error" 1 "Active" 0 "Inactive" ;
VAL_ 2561015629 Auxiliary_IO_84 3 "Not Available" 2 "Error" 1 "Active" 0 "Inactive" ;
VAL_ 2566834828 FailureModeIdentifier5 31 "Not available" 19 "Received network data in error" 18 "Below normal (moderatels severe)" 17 "Below normal (least severe)" 16 "Above normal (moderately severe)" 15 "Above normal (least severe)" 14 "Special intstructions" 13 "Out of calibration" 12 "Bad intelligent device" 11 "Root cause not known" 10 "Abnormal rate of change" 9 "Abnormal update rate" 8 "Abnormal frequency" 7 "Mechanical system not responding" 6 "Current above normal" 5 "Current below normal" 4 "Voltage below normal" 3 "Voltage above normal" 2 "Data erratic" 1 "Below normal (most severe)" 0 "Above normal (most severe)" ;
VAL_ 2566834828 FailureModeIdentifier4 31 "Not available" 19 "Received network data in error" 18 "Below normal (moderatels severe)" 17 "Below normal (least severe)" 16 "Above normal (moderately severe)" 15 "Above normal (least severe)" 14 "Special intstructions" 13 "Out of calibration" 12 "Bad intelligent device" 11 "Root cause not known" 10 "Abnormal rate of change" 9 "Abnormal update rate" 8 "Abnormal frequency" 7 "Mechanical system not responding" 6 "Current above normal" 5 "Current below normal" 4 "Voltage below normal" 3 "Voltage above normal" 2 "Data erratic" 1 "Below normal (most severe)" 0 "Above normal (most severe)" ;
VAL_ 2566834828 FailureModeIdentifier3 31 "Not available" 19 "Received network data in error" 18 "Below normal (moderatels severe)" 17 "Below normal (least severe)" 16 "Above normal (moderately severe)" 15 "Above normal (least severe)" 14 "Special intstructions" 13 "Out of calibration" 12 "Bad intelligent device" 11 "Root cause not known" 10 "Abnormal rate of change" 9 "Abnormal update rate" 8 "Abnormal frequency" 7 "Mechanical system not responding" 6 "Current above normal" 5 "Current below normal" 4 "Voltage below normal" 3 "Voltage above normal" 2 "Data erratic" 1 "Below normal (most severe)" 0 "Above normal (most severe)" ;
VAL_ 2566834828 FailureModeIdentifier2 31 "Not available" 19 "Received network data in error" 18 "Below normal (moderatels severe)" 17 "Below normal (least severe)" 16 "Above normal (moderately severe)" 15 "Above normal (least severe)" 14 "Special intstructions" 13 "Out of calibration" 12 "Bad intelligent device" 11 "Root cause not known" 10 "Abnormal rate of change" 9 "Abnormal update rate" 8 "Abnormal frequency" 7 "Mechanical system not responding" 6 "Current above normal" 5 "Current below normal" 4 "Voltage below normal" 3 "Voltage above normal" 2 "Data erratic" 1 "Below normal (most severe)" 0 "Above normal (most severe)" ;
VAL_ 2566834828 FailureModeIdentifier1 31 "Not available" 19 "Received network data in error" 18 "Below normal (moderatels severe)" 17 "Below normal (least severe)" 16 "Above normal (moderately severe)" 15 "Above normal (least severe)" 14 "Special intstructions" 13 "Out of calibration" 12 "Bad intelligent device" 11 "Root cause not known" 10 "Abnormal rate of change" 9 "Abnormal update rate" 8 "Abnormal frequency" 7 "Mechanical system not responding" 6 "Current above normal" 5 "Current below normal" 4 "Voltage below normal" 3 "Voltage above normal" 2 "Data erratic" 1 "Below normal (most severe)" 0 "Above normal (most severe)" ;
VAL_ 2566834828 FlashMalfuncIndicatorLamp 3 "Unavailable / Do Not Flash" 2 "Reserved" 1 "Fast Flash" 0 "Slow Flash" ;
VAL_ 2566834828 FlashRedStopLamp 3 "Unavailable / Do Not Flash" 2 "Reserved" 1 "Fast Flash" 0 "Slow Flash" ;
VAL_ 2566834828 FlashAmberWarningLamp 3 "Unavailable / Do Not Flash" 2 "Reserved" 1 "Fast Flash" 0 "Slow Flash" ;
VAL_ 2566834828 FlashProtectLamp 3 "Unavailable / Do Not Flash" 2 "Reserved" 1 "Fast Flash" 0 "Slow Flash" ;
VAL_ 2566834828 MalfunctionIndicatorLampStatus 3 "Not available" 2 "Reserved" 1 "Lamp on" 0 "Lamp off" ;
VAL_ 2566834828 RedStopLampState 3 "Not available" 2 "Reserved" 1 "Lamp on" 0 "Lamp off" ;
VAL_ 2566834828 AmberWarningLampStatus 3 "Not available" 2 "Reserved" 1 "Lamp on" 0 "Lamp off" ;
VAL_ 2566834828 ProtectLampStatus 3 "Not available" 2 "Reserved" 1 "Lamp on" 0 "Lamp off" ;
VAL_ 2566853937 ArticulationCollisionActive 3 "Not Available" 2 "Error" 1 "Active" 0 "Inactive" ;
VAL_ 2566853937 ArticulationAngleWarning 3 "Not Available" 2 "Error" 1 "Active" 0 "Inactive" ;
VAL_ 2566853937 TurnTableRedFault 3 "Not Available" 2 "Error" 1 "Active" 0 "Inactive" ;
VAL_ 2566853937 TurnTableAmberWarning 3 "Not Available" 2 "Error" 1 "Active" 0 "Inactive" ;
VAL_ 2566853937 FlapWarningColor 3 "Red" 2 "Yellow" 1 "Green" 0 "No colour" ;
VAL_ 2566853937 DriverDoorOpenWarning 3 "Not Available" 2 "Error" 1 "Active" 0 "Inactive" ;
VAL_ 2566853937 LDWSDisabledIndication 3 "Not Available" 2 "Error" 1 "Active" 0 "Inactive" ;
VAL_ 2566853937 LDWSActiveIndication 3 "Not Available" 2 "Error" 1 "Active" 0 "Inactive" ;
VAL_ 2566853937 Rearviewcamera 3 "Not Available" 2 "Error" 1 "Active" 0 "Inactive" ;
VAL_ 2566853937 AVBSTelltaleState 3 "Not Available" 2 "AVBS Active" 1 "AVBS Disabled" 0 "Inactive" ;
VAL_ 2566853937 PeopleReducedMobilityStopRequest 1 "On" 0 "Off" ;
VAL_ 2566853937 PRAMStopRequest 1 "On" 0 "Off" ;
VAL_ 2566853937 ParkBrakeDriverAlertMode 3 "Not Available" 2 "Alert Mode 2 Active" 1 "Alert Mode 1 Active" 0 "Inactive" ;
VAL_ 2566834698 FailureModeIdentifier5 31 "Not available" 19 "Received network data in error" 18 "Below normal (moderatels severe)" 17 "Below normal (least severe)" 16 "Above normal (moderately severe)" 15 "Above normal (least severe)" 14 "Special intstructions" 13 "Out of calibration" 12 "Bad intelligent device" 11 "Root cause not known" 10 "Abnormal rate of change" 9 "Abnormal update rate" 8 "Abnormal frequency" 7 "Mechanical system not responding" 6 "Current above normal" 5 "Current below normal" 4 "Voltage below normal" 3 "Voltage above normal" 2 "Data erratic" 1 "Below normal (most severe)" 0 "Above normal (most severe)" ;
VAL_ 2566834698 FailureModeIdentifier4 31 "Not available" 19 "Received network data in error" 18 "Below normal (moderatels severe)" 17 "Below normal (least severe)" 16 "Above normal (moderately severe)" 15 "Above normal (least severe)" 14 "Special intstructions" 13 "Out of calibration" 12 "Bad intelligent device" 11 "Root cause not known" 10 "Abnormal rate of change" 9 "Abnormal update rate" 8 "Abnormal frequency" 7 "Mechanical system not responding" 6 "Current above normal" 5 "Current below normal" 4 "Voltage below normal" 3 "Voltage above normal" 2 "Data erratic" 1 "Below normal (most severe)" 0 "Above normal (most severe)" ;
VAL_ 2566834698 FailureModeIdentifier3 31 "Not available" 19 "Received network data in error" 18 "Below normal (moderatels severe)" 17 "Below normal (least severe)" 16 "Above normal (moderately severe)" 15 "Above normal (least severe)" 14 "Special intstructions" 13 "Out of calibration" 12 "Bad intelligent device" 11 "Root cause not known" 10 "Abnormal rate of change" 9 "Abnormal update rate" 8 "Abnormal frequency" 7 "Mechanical system not responding" 6 "Current above normal" 5 "Current below normal" 4 "Voltage below normal" 3 "Voltage above normal" 2 "Data erratic" 1 "Below normal (most severe)" 0 "Above normal (most severe)" ;
VAL_ 2566834698 FailureModeIdentifier2 31 "Not available" 19 "Received network data in error" 18 "Below normal (moderatels severe)" 17 "Below normal (least severe)" 16 "Above normal (moderately severe)" 15 "Above normal (least severe)" 14 "Special intstructions" 13 "Out of calibration" 12 "Bad intelligent device" 11 "Root cause not known" 10 "Abnormal rate of change" 9 "Abnormal update rate" 8 "Abnormal frequency" 7 "Mechanical system not responding" 6 "Current above normal" 5 "Current below normal" 4 "Voltage below normal" 3 "Voltage above normal" 2 "Data erratic" 1 "Below normal (most severe)" 0 "Above normal (most severe)" ;
VAL_ 2566834698 FailureModeIdentifier1 31 "Not available" 19 "Received network data in error" 18 "Below normal (moderatels severe)" 17 "Below normal (least severe)" 16 "Above normal (moderately severe)" 15 "Above normal (least severe)" 14 "Special intstructions" 13 "Out of calibration" 12 "Bad intelligent device" 11 "Root cause not known" 10 "Abnormal rate of change" 9 "Abnormal update rate" 8 "Abnormal frequency" 7 "Mechanical system not responding" 6 "Current above normal" 5 "Current below normal" 4 "Voltage below normal" 3 "Voltage above normal" 2 "Data erratic" 1 "Below normal (most severe)" 0 "Above normal (most severe)" ;
VAL_ 2566834698 FlashMalfuncIndicatorLamp 3 "Unavailable / Do Not Flash" 2 "Reserved" 1 "Fast Flash" 0 "Slow Flash" ;
VAL_ 2566834698 FlashRedStopLamp 3 "Unavailable / Do Not Flash" 2 "Reserved" 1 "Fast Flash" 0 "Slow Flash" ;
VAL_ 2566834698 FlashAmberWarningLamp 3 "Unavailable / Do Not Flash" 2 "Reserved" 1 "Fast Flash" 0 "Slow Flash" ;
VAL_ 2566834698 FlashProtectLamp 3 "Unavailable / Do Not Flash" 2 "Reserved" 1 "Fast Flash" 0 "Slow Flash" ;
VAL_ 2566834698 MalfunctionIndicatorLampStatus 3 "Not available" 2 "Reserved" 1 "Lamp on" 0 "Lamp off" ;
VAL_ 2566834698 RedStopLampState 3 "Not available" 2 "Reserved" 1 "Lamp on" 0 "Lamp off" ;
VAL_ 2566834698 AmberWarningLampStatus 3 "Not available" 2 "Reserved" 1 "Lamp on" 0 "Lamp off" ;
VAL_ 2566834698 ProtectLampStatus 3 "Not available" 2 "Reserved" 1 "Lamp on" 0 "Lamp off" ;
